// *************************************************************************** *
// *                                                                           *
// *                      Mentor Graphics Corporation                          *
// *                          All rights reserved                              *
// *                                                                           *
// *************************************************************************** *
// *                                                                           *
// * Description:         CANDB File                                           *
// * Generated at:        2025-06-23 15:14                                     *
// * System:              PP                                                   *
// * Variant:             DMH                                                  *
// * Network:             PTCANFD                                              *
// *                                                                           *
// *************************************************************************** *
// *                                                                           *
// *             THIS CONFIGURATION MIGHT CONTAIN SOME ERRORS                  *
// *              IF THE INPUT MODEL WAS NOT PROPERLY FORMED!                  *
// *                    Do Not Use this File directly!                         *
// *                                                                           *
// *************************************************************************** *
VERSION "PTCANFD"

NS_ :

BS_ :

BU_ :  BMS CCU PEU PICU TC TESTER VIU0

BO_ 267 MCUR_State_2 : 32 TC
 SG_ MCUR_CBKTq : 31|10@0+ (1.0,-500.0) [-500.0|500.0] "Nm" VIU0
 SG_ MCUR_CurrtPhaA : 151|16@0+ (0.1,-3276.8) [-3276.8|3276.7] "A" VIU0
 SG_ MCUR_CurrtPhaB : 167|16@0+ (0.1,-3276.8) [-3276.8|3276.7] "A" VIU0
 SG_ MCUR_CurrtPhaC : 183|16@0+ (0.1,-3276.8) [-3276.8|3276.7] "A" VIU0
 SG_ MCUR_DATSTq : 199|10@0+ (1.0,-500.0) [-500.0|500.0] "Nm" TESTER
 SG_ MCUR_DCCurrt : 215|16@0+ (0.1,-1000.0) [-1000.0|5553.5] "A" BMS,VIU0
 SG_ MCUR_DCVolt : 231|16@0+ (0.1,0.0) [0.0|6553.5] "V" BMS,VIU0
 SG_ MCUR_FaultLamp : 247|1@0+ (1,0) [0|1] "" TESTER
 SG_ MCUR_IGBTNTCTempA : 79|8@0+ (1.0,-48.0) [-48.0|207.0] "℃" PICU,TESTER
 SG_ MCUR_IGBTNTCTempB : 135|8@0+ (1.0,-48.0) [-48.0|207.0] "℃" PICU,TESTER
 SG_ MCUR_IGBTNTCTemPC : 143|8@0+ (1.0,-48.0) [-48.0|207.0] "℃" PICU,TESTER
 SG_ MCUR_KL30_Volt : 246|9@0+ (0.1,0.0) [0.0|51.1] "V" TESTER
 SG_ MCUR_MIL_Request : 248|1@0+ (1,0) [0|1] "" PICU,TESTER
 SG_ MCUR_OBDFaultExistSts : 37|1@0+ (1,0) [0|1] "" PICU,VIU0
 SG_ MCUR_RMotActvDampLvlSt : 52|2@0+ (1,0) [0|3] "" VIU0
 SG_ MCUR_RMotTqContnsMax : 47|11@0+ (1.0,-1024.0) [-1000.0|1000.0] "Nm" VIU0
 SG_ MCUR_RMotTqContnsMin : 50|11@0+ (1.0,-1024.0) [-1000.0|1000.0] "Nm" VIU0
 SG_ MCUR_RMotTqLongMax : 111|11@0+ (1.0,-1024.0) [-1000.0|1000.0] "Nm" VIU0
 SG_ MCUR_RMotTqLongMin : 114|11@0+ (1.0,-1024.0) [-1000.0|1000.0] "Nm" VIU0
 SG_ MCUR_RMotTqShoMax : 87|11@0+ (1.0,-1024.0) [-1000.0|1000.0] "Nm" VIU0
 SG_ MCUR_RMotTqShoMin : 90|11@0+ (1.0,-1024.0) [-1000.0|1000.0] "Nm" VIU0
 SG_ MCUR_State_2_Checksum : 7|16@0+ (1.0,0.0) [0.0|65535.0] "" VIU0
 SG_ MCUR_State_2_Counter : 23|8@0+ (1.0,0.0) [0.0|255.0] "" VIU0

BO_ 854 MCUR_State_3 : 32 TC
 SG_ MCUR_CBKEnaSt : 127|1@0+ (1,0) [0|1] "" VIU0
 SG_ MCUR_DATSEnableSt : 113|2@0+ (1,0) [0|3] "" TESTER
 SG_ MCUR_DCHV_OverU_OBDFlt : 193|2@0+ (1,0) [0|3] "" TESTER
 SG_ MCUR_EOP_Actual_Speed : 31|8@0+ (1.0,0.0) [0.0|255.0] "" TESTER
 SG_ MCUR_EOP_AIRmix_Fault : 83|1@0+ (1,0) [0|1] "" TESTER
 SG_ MCUR_EOP_Current : 55|8@0+ (0.2,0.0) [0.0|51.0] "" TESTER
 SG_ MCUR_EOP_MOS_Temp : 63|8@0+ (1.0,-40.0) [-40.0|215.0] "℃" TESTER
 SG_ MCUR_EOP_Over_Current_Fault : 87|1@0+ (1,0) [0|1] "" TESTER
 SG_ MCUR_EOP_Over_Temp_Fault : 85|1@0+ (1,0) [0|1] "" TESTER
 SG_ MCUR_EOP_Over_Voltage_Fault : 86|1@0+ (1,0) [0|1] "" TESTER
 SG_ MCUR_EOP_Self_Check_Fault : 103|1@0+ (1,0) [0|1] "" TESTER
 SG_ MCUR_EOP_State : 82|3@0+ (1,0) [0|7] "" TESTER
 SG_ MCUR_EOP_Stuck_Fault : 84|1@0+ (1,0) [0|1] "" TESTER
 SG_ MCUR_EOP_Target_Speed : 39|8@0+ (1.0,0.0) [0.0|255.0] "" TESTER
 SG_ MCUR_EOP_Under_Voltage_Fault : 95|1@0+ (1,0) [0|1] "" TESTER
 SG_ MCUR_EOP_Voltage : 47|8@0+ (0.2,0.0) [0.0|51.0] "" TESTER
 SG_ MCUR_HVAuxPwrSt : 116|1@0+ (1,0) [0|1] "" TESTER
 SG_ MCUR_HVCalSt : 115|2@0+ (1,0) [0|3] "" TESTER
 SG_ MCUR_HWWakeupSt : 117|1@0+ (1,0) [0|1] "" TESTER
 SG_ MCUR_IGBTOverTWarn_OBDFlt : 197|2@0+ (1,0) [0|3] "" TESTER
 SG_ MCUR_KL30_OverU_OBDFlt : 195|2@0+ (1,0) [0|3] "" TESTER
 SG_ MCUR_MotOverTWarn_OBDFlt : 199|2@0+ (1,0) [0|3] "" TESTER
 SG_ MCUR_PCBTemp : 111|8@0+ (1.0,-48.0) [-48.0|207.0] "℃" VIU0
 SG_ MCUR_RMotHeatActPwr : 94|7@0+ (0.1,0.0) [0.0|10.0] "KW" TESTER
 SG_ MCUR_RMotHeatMaxPwr : 102|7@0+ (0.1,0.0) [0.0|10.0] "KW" TESTER
 SG_ MCUR_RMotHeatSt : 119|2@0+ (1,0) [0|3] "" TESTER

BO_ 1459 MCUR_Version : 32 TC
 SG_ MCUR_HwVersion : 23|8@0+ (1.0,0.0) [0.0|255.0] "" TESTER
 SG_ MCUR_SupplierCode : 7|16@0+ (1.0,0.0) [0.0|65535.0] "" TESTER
 SG_ MCUR_SwMajorVersion : 31|8@0+ (1.0,0.0) [0.0|255.0] "" TESTER
 SG_ MCUR_SwMinorVersion : 39|8@0+ (1.0,0.0) [0.0|255.0] "" TESTER
 SG_ MCUR_SwPatchVersion : 47|8@0+ (1.0,0.0) [0.0|255.0] "" TESTER
 SG_ MCUR_SwVersionDay : 71|8@0+ (1.0,0.0) [0.0|31.0] "" TESTER
 SG_ MCUR_SwVersionMonth : 63|8@0+ (1.0,0.0) [0.0|12.0] "" TESTER
 SG_ MCUR_SwVersionYear : 55|8@0+ (1.0,0.0) [0.0|255.0] "" TESTER

BO_ 1042 NM_Autosar_BMS : 8 BMS
 SG_ NM_Autosar_BMS : 7|64@0+ (1,0) [0|0] "" VIU0

BO_ 1045 NM_Autosar_CDU : 8 CCU
 SG_ NM_Autosar_CDU : 7|64@0+ (1,0) [0|0] "" VIU0

BO_ 1048 NM_Autosar_GCU : 8 PEU
 SG_ NM_Autosar_GCU : 7|64@0+ (1,0) [0|0] "" VIU0

BO_ 1044 NM_Autosar_MCUR : 8 TC
 SG_ NM_Autosar_MCUR : 7|64@0+ (1,0) [0|0] "" VIU0

BO_ 1073 NM_Autosar_TDU : 8 PICU
 SG_ NM_Autosar_TDU : 7|64@0+ (1,0) [0|0] "" VIU0

BO_ 1041 NM_Autosar_VDC : 8 VIU0
 SG_ NM_Autosar_VDC : 7|64@0+ (1,0) [0|0] "" BMS, CCU, PEU, PICU, TC, TESTER

BO_ 2018 OBD_PhyReq_BMS : 8 VIU0
 SG_ OBD_PhyReq_BMS : 7|64@0+ (1,0) [0|0] "" BMS

BO_ 2020 OBD_PhyReq_GCU : 8 VIU0
 SG_ OBD_PhyReq_GCU : 7|64@0+ (1,0) [0|0] "" PEU

BO_ 2019 OBD_PhyReq_MCUR : 8 VIU0
 SG_ OBD_PhyReq_MCUR : 7|64@0+ (1,0) [0|0] "" TC

BO_ 2026 OBD_Resp_BMS : 8 BMS
 SG_ OBD_Resp_BMS : 7|64@0+ (1,0) [0|0] "" VIU0

BO_ 2028 OBD_Resp_GCU : 8 PEU
 SG_ OBD_Resp_GCU : 7|64@0+ (1,0) [0|0] "" VIU0

BO_ 2027 OBD_Resp_MCUR : 8 TC
 SG_ OBD_Resp_MCUR : 7|64@0+ (1,0) [0|0] "" VIU0

BO_ 896 TBOX_RemoteSet : 32 VIU0
 SG_ TBOX_ACDefrostSet : 35|2@0+ (1,0) [0|3] "" PICU
 SG_ TBOX_ACONOFFSet : 25|2@0+ (1,0) [0|3] "" PICU
 SG_ Tbox_ACParkAutoVentSetSts : 45|2@0+ (1,0) [0|3] "" PICU
 SG_ TBOX_ACTempSet : 31|6@0+ (0.5,15.0) [15.0|32.5] "" PICU
 SG_ TBOX_ACVentSet : 33|2@0+ (1,0) [0|3] "" PICU
 SG_ TBOX_MaxACSet : 37|2@0+ (1,0) [0|3] "" PICU
 SG_ TBOX_MaxHeatSet : 39|2@0+ (1,0) [0|3] "" PICU
 SG_ VDC_ScheduleChrgEndHour : 76|5@0+ (1.0,0.0) [0.0|23.0] "h" BMS
 SG_ VDC_ScheduleChrgEndMin : 87|6@0+ (1.0,0.0) [0.0|59.0] "min" BMS
 SG_ VDC_ScheduleChrgStarMin : 66|6@0+ (1.0,0.0) [0.0|59.0] "min" BMS
 SG_ VDC_ScheduleChrgStartHour : 71|5@0+ (1.0,0.0) [0.0|23.0] "h" BMS

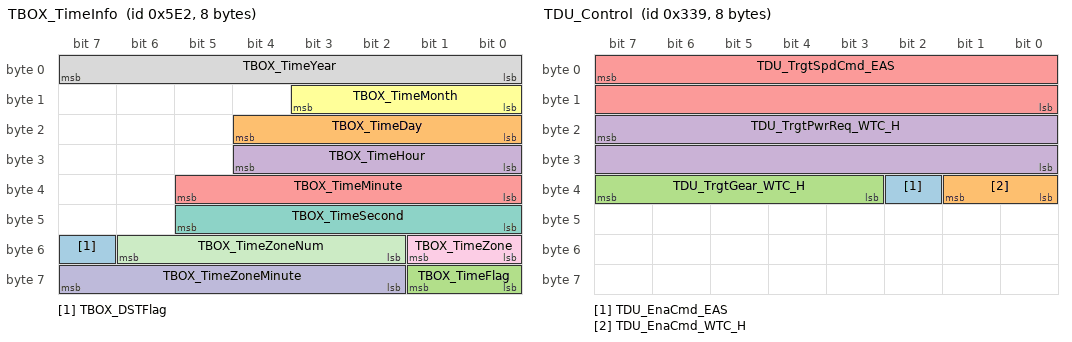
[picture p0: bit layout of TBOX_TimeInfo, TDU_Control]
BO_ 1506 TBOX_TimeInfo : 8 VIU0
 SG_ TBOX_DSTFlag : 55|1@0+ (1,0) [0|1] "" BMS,CCU,PEU,PICU,TC
 SG_ TBOX_TimeDay : 20|5@0+ (1.0,0.0) [1.0|31.0] "Day" BMS,CCU,PEU,PICU,TC
 SG_ TBOX_TimeFlag : 57|2@0+ (1,0) [0|3] "" BMS,CCU,PEU,PICU,TC
 SG_ TBOX_TimeHour : 28|5@0+ (1.0,0.0) [0.0|23.0] "h" BMS,CCU,PEU,PICU,TC
 SG_ TBOX_TimeMinute : 37|6@0+ (1.0,0.0) [0.0|59.0] "min" BMS,CCU,PEU,PICU,TC
 SG_ TBOX_TimeMonth : 11|4@0+ (1.0,0.0) [1.0|12.0] "Month" BMS,CCU,PEU,PICU,TC
 SG_ TBOX_TimeSecond : 45|6@0+ (1.0,0.0) [0.0|59.0] "s" BMS,CCU,PEU,PICU,TC
 SG_ TBOX_TimeYear : 7|8@0+ (1.0,2000.0) [2000.0|2255.0] "Year" BMS,CCU,PEU,PICU,TC
 SG_ TBOX_TimeZone : 49|2@0+ (1,0) [0|3] "" BMS,CCU,PEU,PICU,TC
 SG_ TBOX_TimeZoneMinute : 63|6@0+ (1.0,0.0) [0.0|63.0] "" BMS,CCU,PEU,PICU,TC
 SG_ TBOX_TimeZoneNum : 54|5@0+ (1,0) [0|31] "" BMS,CCU,PEU,PICU,TC

BO_ 820 TDU_ACCtrl : 32 PICU
 SG_ TDU_ACMainSwtSts : 25|2@0+ (1,0) [0|3] "" VIU0
 SG_ TDU_ACMaxSts : 109|2@0+ (1,0) [0|3] "" VIU0
 SG_ TDU_ACSts : 27|2@0+ (1,0) [0|3] "" VIU0
 SG_ TDU_ACSyncSts : 33|2@0+ (1,0) [0|3] "" VIU0
 SG_ TDU_ACWorkModeSts : 114|3@0+ (1,0) [0|7] "" VIU0
 SG_ TDU_AutoDefogRunSts : 213|2@0+ (1,0) [0|3] "" VIU0
 SG_ TDU_AutoDefogSts : 55|2@0+ (1,0) [0|3] "" VIU0
 SG_ TDU_CircModSts : 31|2@0+ (1,0) [0|3] "" VIU0
 SG_ TDU_DriverTempSts : 45|6@0+ (0.5,15.0) [15.0|32.5] "" VIU0
 SG_ TDU_FBlowModeAutoSts : 210|1@0+ (1,0) [0|1] "" VIU0
 SG_ TDU_FHvacBlowLv : 59|4@0+ (1,0) [0|15] "" VIU0
 SG_ TDU_FHvacBlowLvAutoSts : 208|1@0+ (1,0) [0|1] "" VIU0
 SG_ TDU_FogRiskLvl : 191|3@0+ (1,0) [0|7] "" VIU0
 SG_ TDU_FrontAutoSts : 29|2@0+ (1,0) [0|3] "" VIU0
 SG_ TDU_FrontBlowModeSts : 63|4@0+ (1,0) [0|15] "" VIU0
 SG_ TDU_FrontDefrostSts : 47|2@0+ (1,0) [0|3] "" VIU0
 SG_ TDU_HeatMaxSts : 111|2@0+ (1,0) [0|3] "" VIU0
 SG_ TDU_InsdTemp : 87|12@0+ (0.1,-48.0) [-48.0|80.0] "℃" VIU0
 SG_ TDU_OutdTemp : 91|12@0+ (0.1,-48.0) [-48.0|80.0] "℃" BMS,TC,VIU0
 SG_ TDU_ParkAutoVentSts : 116|2@0+ (1,0) [0|3] "" VIU0
 SG_ TDU_PassengerTemptSts : 53|6@0+ (0.5,15.0) [15.0|32.5] "" VIU0
 SG_ TDU_RACMainSwtSts : 159|2@0+ (1,0) [0|3] "" VIU0
 SG_ TDU_TempExclusiveSts : 35|2@0+ (1,0) [0|3] "" VIU0
 SG_ TDU_UnlockVentSt : 227|2@0+ (1,0) [0|3] "" VIU0

BO_ 827 TDU_ACCtrl1 : 32 PICU
 SG_ TDU_ACECOModSts : 107|2@0+ (1,0) [0|3] "" VIU0
 SG_ TDU_AGS1_Position_Cmd : 31|8@0+ (1.0,0.0) [0.0|255.0] "" VIU0
 SG_ TDU_AutoDrySts : 105|2@0+ (1,0) [0|3] "" VIU0
 SG_ TDU_RemDefrostSts : 147|2@0+ (1,0) [0|3] "" VIU0
 SG_ TDU_RemFaultSts : 145|2@0+ (1,0) [0|3] "" VIU0
 SG_ TDU_RemSts : 149|2@0+ (1,0) [0|3] "" VIU0
 SG_ TDU_RemTempSetSts : 159|8@0+ (0.5,0.0) [0.0|127.5] "" VIU0
 SG_ TDU_VentSts : 109|2@0+ (1,0) [0|3] "" VIU0

BO_ 825 TDU_Control : 8 PICU
 SG_ TDU_EnaCmd_EAS : 34|1@0+ (1,0) [0|1] "" TESTER
 SG_ TDU_EnaCmd_WTC_H : 33|2@0+ (1,0) [0|3] "" TESTER
 SG_ TDU_TrgtGear_WTC_H : 39|5@0+ (1,0) [0|31] "" TESTER
 SG_ TDU_TrgtPwrReq_WTC_H : 23|16@0+ (1.0,0.0) [0.0|10000.0] "W" TESTER
 SG_ TDU_TrgtSpdCmd_EAS : 7|16@0+ (0.25,0.0) [0.0|16383.75] "rpm" TESTER

BO_ 823 TDU_EngThermMngt : 32 PICU
 SG_ TDU_CVM_B_ActPerc : 63|8@0+ (0.4,0.0) [0.0|100.0] "%" TESTER
 SG_ TDU_CVM_B_TrgtPerc : 47|8@0+ (0.4,0.0) [0.0|100.0] "%" TESTER
 SG_ TDU_CVM_H_ActPerc : 71|8@0+ (0.4,0.0) [0.0|100.0] "%" TESTER
 SG_ TDU_CVM_H_TrgtPerc : 55|8@0+ (0.4,0.0) [0.0|100.0] "%" TESTER
 SG_ TDU_EngingstartReq : 15|1@0+ (1,0) [0|1] "" VIU0
 SG_ TDU_EngPmpSpdHeatReq : 7|7@0+ (1.0,0.0) [0.0|100.0] "%" VIU0
 SG_ TDU_EngPmpSpdHeatReqVld : 0|1@0+ (1,0) [0|1] "" VIU0
 SG_ TDU_EXV_B_LPTSnsrP : 98|9@0+ (0.01,0.0) [0.0|5.0] "MPa" TESTER
 SG_ TDU_EXV_B_LPTSnsrT : 115|12@0+ (0.1,-50.0) [-50.0|150.0] "℃" TESTER
 SG_ TDU_EXV_H_LPTSnsrP : 87|9@0+ (0.01,0.0) [0.0|5.0] "MPa" TESTER
 SG_ TDU_EXV_H_LPTSnsrT : 94|12@0+ (0.1,-50.0) [-50.0|150.0] "℃" TESTER
 SG_ TDU_FWV_CCWFlg : 38|1@0+ (1.0,0.0) [0.0|1.0] "" TESTER
 SG_ TDU_FWV_FltSt : 11|3@0+ (1.0,0.0) [0.0|7.0] "" TESTER
 SG_ TDU_FWV_InitSta : 39|1@0+ (1.0,0.0) [0.0|1.0] "" TESTER
 SG_ TDU_FWV_location : 8|9@0+ (0.25,0.0) [0.0|100.0] "%" TESTER
 SG_ TDU_FWV_location_FB : 31|8@0+ (0.4,0.0) [0.0|100.0] "%" TESTER
 SG_ TDU_FWV_MotorSta : 37|1@0+ (1.0,0.0) [0.0|1.0] "" TESTER
 SG_ TDU_FWV_MoveEnable : 14|1@0+ (1.0,0.0) [0.0|1.0] "" TESTER
 SG_ TDU_FWV_ReqMotorEmgyStop : 13|1@0+ (1.0,0.0) [0.0|1.0] "" TESTER
 SG_ TDU_FWV_ReqMotorOptRecovery : 12|1@0+ (1.0,0.0) [0.0|1.0] "" TESTER
 SG_ TDU_IcoInlT : 79|8@0+ (1.0,-48.0) [-48.0|207.0] "℃" TESTER,VIU0

BO_ 1420 TDU_Fault : 32 PICU
 SG_ TDU_FaultNum1 : 23|12@0+ (1.0,0.0) [0.0|4095.0] "" VIU0
 SG_ TDU_FaultNum10 : 123|12@0+ (1.0,0.0) [0.0|4095.0] "" VIU0
 SG_ TDU_FaultNum11 : 143|12@0+ (1.0,0.0) [0.0|4095.0] "" VIU0
 SG_ TDU_FaultNum12 : 147|12@0+ (1.0,0.0) [0.0|4095.0] "" VIU0
 SG_ TDU_FaultNum13 : 167|12@0+ (1.0,0.0) [0.0|4095.0] "" VIU0
 SG_ TDU_FaultNum14 : 171|12@0+ (1.0,0.0) [0.0|4095.0] "" VIU0
 SG_ TDU_FaultNum15 : 191|12@0+ (1.0,0.0) [0.0|4095.0] "" VIU0
 SG_ TDU_FaultNum16 : 195|12@0+ (1.0,0.0) [0.0|4095.0] "" VIU0
 SG_ TDU_FaultNum17 : 215|12@0+ (1.0,0.0) [0.0|4095.0] "" VIU0
 SG_ TDU_FaultNum18 : 219|12@0+ (1.0,0.0) [0.0|4095.0] "" VIU0
 SG_ TDU_FaultNum19 : 239|12@0+ (1.0,0.0) [0.0|4095.0] "" VIU0
 SG_ TDU_FaultNum2 : 27|12@0+ (1.0,0.0) [0.0|4095.0] "" VIU0
 SG_ TDU_FaultNum20 : 243|12@0+ (1.0,0.0) [0.0|4095.0] "" VIU0
 SG_ TDU_FaultNum3 : 47|12@0+ (1.0,0.0) [0.0|4095.0] "" VIU0
 SG_ TDU_FaultNum4 : 51|12@0+ (1.0,0.0) [0.0|4095.0] "" VIU0
 SG_ TDU_FaultNum5 : 71|12@0+ (1.0,0.0) [0.0|4095.0] "" VIU0
 SG_ TDU_FaultNum6 : 75|12@0+ (1.0,0.0) [0.0|4095.0] "" VIU0
 SG_ TDU_FaultNum7 : 95|12@0+ (1.0,0.0) [0.0|4095.0] "" VIU0
 SG_ TDU_FaultNum8 : 99|12@0+ (1.0,0.0) [0.0|4095.0] "" VIU0
 SG_ TDU_FaultNum9 : 119|12@0+ (1.0,0.0) [0.0|4095.0] "" VIU0
 SG_ TDU_FrameIndex : 12|5@0+ (1.0,0.0) [0.0|31.0] "" VIU0
 SG_ TDU_SupplierNum : 15|3@0+ (1.0,0.0) [0.0|7.0] "" VIU0
 SG_ TDU_TotalFaultNum : 7|8@0+ (1.0,0.0) [0.0|255.0] "" VIU0

BO_ 821 TDU_HybMotCtrl : 32 PICU
 SG_ TDU_CircHybThrMotActPerc : 55|8@0+ (1.0,0.0) [0.0|100.0] "%" VIU0
 SG_ TDU_CircHybThrMotTrgtPerc : 23|8@0+ (1.0,0.0) [0.0|100.0] "%" TESTER
 SG_ TDU_LeBlowFaceAirOutlT : 135|12@0+ (0.1,-48.0) [-48.0|207.0] "℃" TESTER
 SG_ TDU_LeBlowFootAirOutlT : 159|12@0+ (0.1,-48.0) [-48.0|207.0] "℃" TESTER
 SG_ TDU_LeModHybThrMotActGear_F : 59|4@0+ (1,0) [0|15] "" TESTER
 SG_ TDU_LeModHybThrMotTrgtGear_F : 27|4@0+ (1,0) [0|15] "" TESTER
 SG_ TDU_LeTHybThrMotActPerc_F : 39|8@0+ (1.0,0.0) [0.0|100.0] "%" TESTER
 SG_ TDU_LeTHybThrMotTrgtPerc_F : 7|8@0+ (1.0,0.0) [0.0|100.0] "%" TESTER
 SG_ TDU_RiBlowFaceAirOutlT : 139|12@0+ (0.1,-48.0) [-48.0|207.0] "℃" TESTER
 SG_ TDU_RiBlowFootAirOutlT : 163|12@0+ (0.1,-48.0) [-48.0|207.0] "℃" TESTER
 SG_ TDU_RiTHybThrMotActPerc_F : 47|8@0+ (1.0,0.0) [0.0|100.0] "%" TESTER
 SG_ TDU_RiTHybThrMotTrgtPerc_F : 15|8@0+ (1.0,0.0) [0.0|100.0] "%" TESTER

BO_ 908 TDU_PTCCtrlFD : 32 PICU
 SG_ ACComprMngmntInfo : 199|6@0+ (1,0) [0|63] "" TESTER
 SG_ AmbtTemSnsrFlrSts : 34|3@0+ (1.0,0.0) [0.0|7.0] "" TESTER
 SG_ AmbtTemSnsrFlrStsInvsn : 59|3@0+ (1.0,0.0) [0.0|7.0] "" TESTER
 SG_ EvapACMangmntInfo : 95|8@0+ (1.0,0.0) [0.0|255.0] "" TESTER
 SG_ HeatPumpErMngmntInfo : 207|5@0+ (1,0) [0|31] "" TESTER
 SG_ HeatPumpMd : 187|4@0+ (1,0) [0|15] "" TESTER
 SG_ PTCMngmntInfo : 103|8@0+ (1.0,0.0) [0.0|255.0] "" TESTER
 SG_ TDU_AGS1_CurrentPos : 79|8@0+ (1.0,0.0) [0.0|255.0] "%" VIU0
 SG_ TDU_AGS2_CurrentPos : 71|8@0+ (1.0,0.0) [0.0|255.0] "%" VIU0
 SG_ TDU_AGS_TarPos : 87|8@0+ (1.0,0.0) [0.0|255.0] "%" TESTER
 SG_ TDU_BypsVlv_Sts : 63|2@0+ (1.0,0.0) [0.0|3.0] "" TESTER
 SG_ TDU_ESSPTC_HVIL_St : 209|2@0+ (1,0) [0|3] "" VIU0
 SG_ TDU_ESSTC_HVIL_St : 202|2@0+ (1,0) [0|3] "" TESTER
 SG_ TDU_ExInnerInletTem : 163|12@0+ (0.1,-48.0) [-48.0|207.0] "℃" TESTER
 SG_ TDU_ExInnerOutletTem : 183|12@0+ (0.1,-48.0) [-48.0|207.0] "℃" TESTER
 SG_ TDU_HtngVlv_Sts : 61|2@0+ (1.0,0.0) [0.0|3.0] "" TESTER
 SG_ TDU_LePTCAirOutlT : 115|12@0+ (0.1,-48.0) [-48.0|207.0] "℃" TESTER
 SG_ TDU_LePTCAirOutlTrgtTemp : 139|12@0+ (0.1,-48.0) [-48.0|207.0] "℃" TESTER
 SG_ TDU_OtsdAirTemRaw : 111|12@0+ (0.1,-48.0) [-48.0|80.0] "℃" TESTER
 SG_ TDU_RiPTCAirOutlT : 135|12@0+ (0.1,-48.0) [-48.0|207.0] "℃" TESTER
 SG_ TDU_RiPTCAirOutlTrgtTemp : 159|12@0+ (0.1,-48.0) [-48.0|207.0] "℃" TESTER
 SG_ TDU_SOTXV_Sts : 36|2@0+ (1.0,0.0) [0.0|3.0] "" TESTER
 SG_ TDU_TempExclusiveRearFlg : 193|2@0+ (1,0) [0|3] "" TESTER
 SG_ TDUEnbPTC : 39|1@0+ (1,0) [0|1] "" VIU0
 SG_ TDUReqMd : 38|2@0+ (1,0) [0|3] "" VIU0
 SG_ TDUReqPTCPwr : 47|16@0+ (1.0,0.0) [0.0|65535.0] "" VIU0

BO_ 829 TDU_Pump : 32 PICU
 SG_ TDU_BatPumpTrgtSpd : 111|8@0+ (0.4,0.0) [0.0|100.0] "%" TESTER
 SG_ TDU_MotPumpTrgtSpd : 103|8@0+ (0.4,0.0) [0.0|100.0] "%" TESTER
 SG_ TDU_PumpBActSpd : 39|8@0+ (0.4,0.0) [0.0|100.0] "%" TESTER
 SG_ TDU_PumpBCurrt : 63|8@0+ (0.1,0.0) [0.0|25.5] "A" TESTER
 SG_ TDU_PumpBTemp : 55|8@0+ (1.0,-48.0) [-48.0|206.0] "℃" TESTER
 SG_ TDU_PumpBVolt : 47|8@0+ (0.1,0.0) [0.0|25.400000000000002] "V" TESTER
 SG_ TDU_PumpPActSpd : 71|8@0+ (0.4,0.0) [0.0|100.0] "%" TESTER
 SG_ TDU_PumpPCurrt : 95|8@0+ (0.1,0.0) [0.0|25.5] "A" TESTER
 SG_ TDU_PumpPTemp : 87|8@0+ (1.0,-48.0) [-48.0|206.0] "℃" TESTER
 SG_ TDU_PumpPVolt : 79|8@0+ (0.1,0.0) [0.0|25.400000000000002] "V" TESTER

BO_ 1329 TDU_SubSnsrState_1 : 32 PICU
 SG_ TDU_HPTSnsrP : 7|9@0+ (0.01,0.0) [0.0|5.0] "MPa" TESTER
 SG_ TDU_HPTSnsrT : 11|12@0+ (0.1,-50.0) [-50.0|150.0] "℃" TESTER
 SG_ TDU_LPTSnsrP : 31|9@0+ (0.01,0.0) [0.0|5.0] "MPa" TESTER
 SG_ TDU_LPTSnsrT : 35|12@0+ (0.1,-50.0) [-50.0|150.0] "℃" TESTER

BO_ 828 TDU_SubSnsrState_2 : 32 PICU
 SG_ TDU_AirBlowerDownFbU : 87|11@0+ (0.01,0.0) [0.0|16.0] "V" TESTER
 SG_ TDU_AirBlowerRelaySpdPWM : 55|8@0+ (0.4,0.0) [0.0|100.0] "" TESTER
 SG_ TDU_AirBlowerRelaySpdU : 71|11@0+ (0.01,0.0) [0.0|16.0] "V" TESTER
 SG_ TDU_AirBlowerUpFbU : 90|11@0+ (0.01,0.0) [0.0|16.0] "V" TESTER
 SG_ TDU_EvaprTemp : 35|12@0+ (0.1,-48.0) [-48.0|207.0] "℃" TESTER
 SG_ TDU_FEvaprTrgtTemp : 135|12@0+ (0.1,-48.0) [-48.0|207.0] "℃" TESTER
 SG_ TDU_LeSunshineSnsrT : 111|11@0+ (1.0,0.0) [0.0|1200.0] "W" TESTER
 SG_ TDU_RiSunshineSnsrT : 114|11@0+ (1.0,0.0) [0.0|1200.0] "" TESTER
 SG_ TDU_UBRVolt : 31|12@0+ (0.01,0.0) [0.0|16.0] "V" TESTER
 SG_ TDU_WakeupVolt : 23|8@0+ (0.1,0.0) [0.0|16.0] "V" TESTER

BO_ 1328 TDU_TempFeedBack : 32 PICU
 SG_ TDU_BattInlT : 23|8@0+ (1.0,-48.0) [-48.0|207.0] "℃" BMS,VIU0
 SG_ TDU_BattOutlT : 31|8@0+ (1.0,-48.0) [-48.0|207.0] "℃" BMS,VIU0
 SG_ TDU_HEXInWtrT : 55|12@0+ (1.0,-48.0) [-48.0|207.0] "°C" TESTER
 SG_ TDU_MotInletWaterT : 39|8@0+ (1.0,-48.0) [-48.0|207.0] "℃" TC,VIU0
 SG_ TDU_MotLoopCooltFlow : 47|8@0+ (0.1,0.0) [0.0|25.5] "L/min" TC,VIU0

BO_ 817 TDU_ThermalState : 32 PICU
 SG_ TDU_BattCoolgLoopSts : 43|2@0+ (1,0) [0|3] "" BMS
 SG_ TDU_BattModSt : 59|4@0+ (1,0) [0|15] "" BMS,VIU0
 SG_ TDU_BattThermRunawaySts : 82|1@0+ (1,0) [0|1] "" TESTER
 SG_ TDU_BattWrmLoopSts : 35|2@0+ (1,0) [0|3] "" BMS
 SG_ TDU_CabCoolLoopSts : 39|2@0+ (1,0) [0|3] "" TESTER
 SG_ TDU_CabHeatLoopSts : 37|2@0+ (1,0) [0|3] "" TESTER
 SG_ TDU_CabModSt : 55|4@0+ (1,0) [0|15] "" BMS,VIU0
 SG_ TDU_FaultLevel : 87|3@0+ (1,0) [0|7] "" VIU0
 SG_ TDU_HeatMngtFctLim : 33|1@0+ (1,0) [0|1] "" TESTER
 SG_ TDU_HeatMngtSysFlt : 24|1@0+ (1,0) [0|1] "" TESTER
 SG_ TDU_HeatMngtSysFltNr : 119|16@0+ (1.0,0.0) [0.0|65535.0] "" TESTER
 SG_ TDU_HEnerConsume : 103|16@0+ (1.0,0.0) [0.0|30000.0] "W" VIU0
 SG_ TDU_HVCnctHldReq : 83|1@0+ (1,0) [0|1] "" VIU0
 SG_ TDU_HVPwrMaxReq : 135|16@0+ (1.0,0.0) [0.0|60000.0] "" VIU0
 SG_ TDU_HVPwrMinReq : 151|16@0+ (1.0,0.0) [0.0|60000.0] "" VIU0
 SG_ TDU_LEnerConsume : 81|10@0+ (1.0,0.0) [0.0|1000.0] "W" TESTER
 SG_ TDU_LVPwrMaxReq : 167|16@0+ (1.0,0.0) [0.0|60000.0] "" TESTER
 SG_ TDU_LVPwrMinReq : 183|16@0+ (1.0,0.0) [0.0|60000.0] "" TESTER
 SG_ TDU_MotCoolgLoopSts : 41|2@0+ (1,0) [0|3] "" TC,VIU0
 SG_ TDU_MotHeatPwrAvl : 247|8@0+ (0.1,0.0) [0.0|25.400000000000002] "kw" VIU0
 SG_ TDU_OperMod : 51|4@0+ (1,0) [0|15] "" VIU0
 SG_ TDU_PTCPwrAct : 239|8@0+ (0.1,0.0) [0.0|25.400000000000002] "kw" VIU0
 SG_ TDU_PTCPwrAvl : 231|8@0+ (0.1,0.0) [0.0|25.400000000000002] "kw" VIU0
 SG_ TDU_PwrModSt : 63|4@0+ (1,0) [0|15] "" TESTER
 SG_ TDU_RefModSt : 47|4@0+ (1,0) [0|15] "" VIU0
 SG_ TDU_SafteyModSts : 32|1@0+ (1,0) [0|1] "" VIU0
 SG_ TDU_SilentCoolgErrWakeup : 29|1@0+ (1,0) [0|1] "" TESTER
 SG_ TDU_SilentCoolgSts : 28|2@0+ (1,0) [0|3] "" TESTER
 SG_ TDU_WakeupHldReq : 84|1@0+ (1,0) [0|1] "" TESTER

BO_ 1333 TDU_ValveCtrl : 32 PICU
 SG_ TDU_CoolgFanActSpd : 7|8@0+ (0.4,0.0) [0.0|100.0] "%" TESTER
 SG_ TDU_CoolgFanOpenCmd : 15|8@0+ (0.4,0.0) [0.0|100.0] "" TESTER
 SG_ TDU_EXVB_ActOpenVal : 103|16@0+ (1.0,0.0) [0.0|576.0] "" TESTER
 SG_ TDU_EXVB_InitSts : 132|2@0+ (1,0) [0|3] "" TESTER
 SG_ TDU_EXVB_OpenCmd : 71|16@0+ (1.0,0.0) [0.0|576.0] "" TESTER
 SG_ TDU_EXVB_Sts : 133|1@0+ (1,0) [0|1] "" TESTER
 SG_ TDU_EXVH_ActOpenVal : 119|16@0+ (1.0,0.0) [0.0|576.0] "" TESTER
 SG_ TDU_EXVH_InitSts : 129|2@0+ (1,0) [0|3] "" TESTER
 SG_ TDU_EXVH_OpenCmd : 87|16@0+ (1.0,0.0) [0.0|576.0] "" TESTER
 SG_ TDU_EXVH_Sts : 130|1@0+ (1,0) [0|1] "" TESTER

BO_ 1461 TDU_Version : 32 PICU
 SG_ EAS_HwVersion : 223|8@0+ (1.0,0.0) [0.0|255.0] "" TESTER
 SG_ EAS_SwMajorVersion : 231|8@0+ (1.0,0.0) [0.0|255.0] "" TESTER
 SG_ EAS_SwMinorVersion : 239|8@0+ (1.0,0.0) [0.0|255.0] "" TESTER
 SG_ PTC_R_HwVersion : 247|8@0+ (1.0,0.0) [0.0|255.0] "" TESTER
 SG_ PTC_R_SwVersion : 255|8@0+ (1.0,0.0) [0.0|255.0] "" TESTER
 SG_ TDU_HwVersion : 23|8@0+ (1.0,0.0) [0.0|255.0] "" TESTER
 SG_ TDU_PartVers : 79|32@0+ (1.0,0.0) [0.0|4294967295.0] "" TESTER
 SG_ TDU_SupplierCode : 7|16@0+ (1.0,0.0) [0.0|65535.0] "" TESTER
 SG_ TDU_SwMajorVersion : 31|8@0+ (1.0,0.0) [0.0|255.0] "" TESTER
 SG_ TDU_SwMinorVersion : 39|8@0+ (1.0,0.0) [0.0|255.0] "" TESTER
 SG_ TDU_SwPatchVersion : 47|8@0+ (1.0,0.0) [0.0|255.0] "" TESTER
 SG_ TDU_SwVersionDay : 71|8@0+ (1.0,0.0) [0.0|31.0] "" TESTER
 SG_ TDU_SwVersionMonth : 63|8@0+ (1.0,0.0) [0.0|12.0] "" TESTER
 SG_ TDU_SwVersionYear : 55|8@0+ (1.0,0.0) [0.0|255.0] "" TESTER
 SG_ WTC_H_HwVersion : 199|8@0+ (1.0,0.0) [0.0|255.0] "" TESTER
 SG_ WTC_H_SwMajorVersion : 207|8@0+ (1.0,0.0) [0.0|255.0] "" TESTER
 SG_ WTC_H_SwMinorVersion : 215|8@0+ (1.0,0.0) [0.0|255.0] "" TESTER

BO_ 818 TDU_WTC_EAS : 32 PICU
 SG_ TDU_EAS_CrtPwr : 207|16@0+ (0.2,0.0) [0.0|13107.0] "W" VIU0
 SG_ TDU_EAS_CrtSts : 141|2@0+ (1,0) [0|3] "" TESTER
 SG_ TDU_EAS_CtrlrCurrt : 247|16@0+ (0.02,0.0) [0.0|1310.7] "A" BMS
 SG_ TDU_EAS_CtrlrVolt : 231|16@0+ (0.02,0.0) [0.0|1310.7] "V" BMS
 SG_ TDU_EAS_HVIL_St : 143|2@0+ (1,0) [0|3] "" VIU0
 SG_ TDU_EAS_IPMTemp : 199|8@0+ (1.0,-48.0) [-48.0|207.0] "℃" TESTER
 SG_ TDU_EAS_MotCurrt : 183|16@0+ (0.02,0.0) [0.0|1310.7] "A" BMS,TESTER
 SG_ TDU_EAS_MotSpd : 167|16@0+ (0.25,0.0) [0.0|16383.75] "rpm" TESTER
 SG_ TDU_WTC_H_ActGear : 68|5@0+ (1,0) [0|31] "" TESTER
 SG_ TDU_WTC_H_CrtPwr : 39|16@0+ (1.0,0.0) [0.0|65534.0] "W" VIU0
 SG_ TDU_WTC_H_CrtSts : 71|3@0+ (1,0) [0|7] "" TESTER
 SG_ TDU_WTC_H_CrtTemp : 119|8@0+ (1.0,-48.0) [-48.0|207.0] "℃" TESTER
 SG_ TDU_WTC_H_Currt : 79|16@0+ (0.001,0.0) [0.0|65.535] "" BMS
 SG_ TDU_WTC_H_HVPwrSplySts : 95|16@0+ (0.02,0.0) [0.0|1310.7] "V" BMS
 SG_ TDU_WTC_H_InpTemp : 55|8@0+ (1.0,-48.0) [-48.0|207.0] "℃" TESTER
 SG_ TDU_WTC_H_OutpTemp : 63|8@0+ (1.0,-48.0) [-48.0|207.0] "℃" TESTER
 SG_ TDU_WTC_H_PCBTemp : 111|8@0+ (1.0,-48.0) [-48.0|207.0] "" TESTER
 SG_ TDU_WTC_H_TarOutpTemp : 127|8@0+ (1.0,-48.0) [-48.0|207.0] "℃" TESTER
 SG_ TDU_WTC_HVIL_St : 31|2@0+ (1,0) [0|3] "" VIU0

BO_ 582 VDC_BCM_DoorState : 32 VIU0
 SG_ VDC_DrvrDoorLockSt : 87|2@0+ (1,0) [0|3] "" PICU
 SG_ VDC_DrvrDoorLockStVld : 84|1@0+ (1,0) [0|1] "" PICU
 SG_ VDC_DrvrDoorSt : 31|2@0+ (1,0) [0|3] "" PICU
 SG_ VDC_DrvrDoorStValid : 29|1@0+ (1,0) [0|1] "" PICU
 SG_ VDC_HoodSts : 37|2@0+ (1,0) [0|3] "" PICU
 SG_ VDC_PassDoorLockSt : 83|2@0+ (1,0) [0|3] "" PICU
 SG_ VDC_PassDoorSt : 28|2@0+ (1,0) [0|3] "" PICU
 SG_ VDC_RLDoorLockSt : 81|2@0+ (1,0) [0|3] "" PICU
 SG_ VDC_RLDoorSt : 26|2@0+ (1,0) [0|3] "" PICU
 SG_ VDC_RRDoorLockSt : 95|2@0+ (1,0) [0|3] "" PICU
 SG_ VDC_RRDoorSt : 39|2@0+ (1,0) [0|3] "" PICU
 SG_ VDC_TailgateSt : 35|4@0+ (1,0) [0|15] "" PICU

BO_ 798 VDC_BCM_SeatState : 32 VIU0
 SG_ VDC_BCM_SeatState_Checksum : 7|16@0+ (1.0,0.0) [0.0|65535.0] "" TESTER
 SG_ VDC_BCM_SeatState_Counter : 23|8@0+ (1.0,0.0) [0.0|255.0] "" TESTER
 SG_ VDC_DriverSeatOccptSt : 47|2@0+ (1,0) [0|3] "" PICU
 SG_ VDC_PassSeatOccptSt : 45|2@0+ (1,0) [0|3] "" PICU
 SG_ VDC_RLSecRowSeatOccptSt : 43|2@0+ (1,0) [0|3] "" PICU
 SG_ VDC_RMSecRowSeatOccptSt : 41|2@0+ (1,0) [0|3] "" PICU
 SG_ VDC_RRSecRowSeatOccptSt : 55|2@0+ (1,0) [0|3] "" PICU

BO_ 819 VDC_CDC_TDUSet : 32 VIU0
 SG_ VDC_CDC_ACECOModReq : 151|2@0+ (1,0) [0|3] "" PICU
 SG_ VDC_CDC_ACFourZoneSync : 101|2@0+ (1,0) [0|3] "" PICU
 SG_ VDC_CDC_ACMaxSet : 97|2@0+ (1,0) [0|3] "" PICU
 SG_ VDC_CDC_ACParkAutoVentSet : 111|2@0+ (1,0) [0|3] "" PICU
 SG_ VDC_CDC_ACSet : 27|2@0+ (1,0) [0|3] "" PICU
 SG_ VDC_CDC_ACSystemOnOffSet : 31|2@0+ (1,0) [0|3] "" PICU
 SG_ VDC_CDC_AutoDefogSet : 105|2@0+ (1,0) [0|3] "" PICU
 SG_ VDC_CDC_AutoDrySet : 149|2@0+ (1,0) [0|3] "" PICU
 SG_ VDC_CDC_CircModSet : 87|2@0+ (1,0) [0|3] "" PICU
 SG_ VDC_CDC_DriverTempSet : 53|6@0+ (0.5,15.0) [15.0|32.5] "" PICU
 SG_ VDC_CDC_FHvacBlowLvSet : 39|4@0+ (1,0) [0|15] "" PICU
 SG_ VDC_CDC_FHvacModeSet : 47|4@0+ (1,0) [0|15] "" PICU
 SG_ VDC_CDC_FrontDefrostSet : 25|2@0+ (1,0) [0|3] "" PICU
 SG_ VDC_CDC_HeatMaxSet : 99|2@0+ (1,0) [0|3] "" PICU
 SG_ VDC_CDC_HvacAutoModeSet : 95|2@0+ (1,0) [0|3] "" PICU
 SG_ VDC_CDC_PassengerTempSet : 61|6@0+ (0.5,15.0) [15.0|32.5] "" PICU
 SG_ VDC_CDC_RACSystemOnOffSet : 29|2@0+ (1,0) [0|3] "" PICU
 SG_ VDC_CDC_SceneModPwrOnSts : 175|2@0+ (1,0) [0|3] "" PICU
 SG_ VDC_CDC_SupCoolingModSet : 117|2@0+ (1,0) [0|3] "" PICU
 SG_ VDC_CDC_TempExclusive : 103|2@0+ (1,0) [0|3] "" PICU
 SG_ VDC_CDC_VentSet : 153|2@0+ (1,0) [0|3] "" PICU

BO_ 289 VDC_EMSCtrl : 32 VIU0
 SG_ VDC_CoordiRespondSt : 26|1@0+ (1,0) [0|1] "" PICU
 SG_ VDC_DrvgCyc : 39|1@0+ (1,0) [0|1] "" TESTER
 SG_ VDC_EMSCtrl_Checksum : 7|16@0+ (1.0,0.0) [0.0|65535.0] "" PICU
 SG_ VDC_EMSCtrl_Counter : 23|8@0+ (1.0,0.0) [0.0|255.0] "" PICU
 SG_ VDC_EngCrankReq : 51|1@0+ (1,0) [0|1] "" PICU
 SG_ VDC_EngCtrlSt : 30|4@0+ (1,0) [0|15] "" PICU,TESTER
 SG_ VDC_EngMaxSpdLim : 183|13@0+ (1.0,0.0) [0.0|8000.0] "" PICU
 SG_ VDC_EngRampEna : 60|1@0+ (1,0) [0|1] "" PICU
 SG_ VDC_EngReadySt : 31|1@0+ (1,0) [0|1] "" PICU
 SG_ VDC_EngStartMod : 53|2@0+ (1,0) [0|3] "" PICU
 SG_ VDC_EngStartReq : 55|2@0+ (1,0) [0|3] "" PICU
 SG_ VDC_EngStopReq : 48|1@0+ (1,0) [0|1] "" PICU
 SG_ VDC_EngStrtFuInjInhb : 50|1@0+ (1,0) [0|1] "" PICU
 SG_ VDC_EngTqResv : 130|11@0+ (0.5,-500.0) [-500.0|500.0] "Nm" PICU
 SG_ VDC_FlyWhFastTqReq : 151|13@0+ (0.1,-350.0) [-350.0|400.0] "Nm" PICU
 SG_ VDC_FlyWhFastTqReqVld : 154|1@0+ (1,0) [0|1] "" PICU
 SG_ VDC_FlyWhSlowTqReq : 167|13@0+ (0.1,-350.0) [-350.0|400.0] "Nm" PICU
 SG_ VDC_FlyWhSlowTqReqVld : 170|1@0+ (1,0) [0|1] "" PICU
 SG_ VDC_FuelChargeStatus : 227|2@0+ (1,0) [0|3] "" TESTER
 SG_ VDC_FuelChargeSwitch : 228|1@0+ (1,0) [0|1] "" TESTER
 SG_ VDC_FuelCutOffReq : 63|1@0+ (1,0) [0|1] "" PICU
 SG_ VDC_FueldetectionStatus : 230|2@0+ (1,0) [0|3] "" TESTER
 SG_ VDC_FueldetectionSwitch : 231|1@0+ (1,0) [0|1] "" TESTER
 SG_ VDC_FuelRemaining : 47|7@0+ (1.0,0.0) [0.0|100.0] "%" PICU
 SG_ VDC_FuelRemainingVld : 40|1@0+ (1,0) [0|1] "" PICU
 SG_ VDC_FuelRemainingVol : 215|14@0+ (0.01,0.0) [0.0|100.0] "L" PICU
 SG_ VDC_GenStableTqAdpSt : 25|1@0+ (1,0) [0|1] "" PICU
 SG_ VDC_IdleChrgActvReq : 97|2@0+ (1,0) [0|3] "" PICU
 SG_ VDC_IdleChrgFlyWhlLoadTq : 127|13@0+ (0.1,-350.0) [-350.0|400.0] "" PICU
 SG_ VDC_IdleChrgFlyWhlLoadTqVld : 114|1@0+ (1,0) [0|1] "" PICU
 SG_ VDC_IdleChrgSpdReq : 111|12@0+ (1.0,0.0) [0.0|2550.0] "" PICU
 SG_ VDC_IdleChrgSpdReqVld : 115|1@0+ (1,0) [0|1] "" PICU
 SG_ VDC_IdleCtrlReq : 59|2@0+ (1,0) [0|3] "" PICU
 SG_ VDC_IdleLoadTq : 95|13@0+ (0.1,-350.0) [-350.0|400.0] "" PICU
 SG_ VDC_IdleLoadTqVld : 98|1@0+ (1,0) [0|1] "" PICU
 SG_ VDC_IgAglRlsActvSts : 62|2@0+ (1,0) [0|3] "" PICU
 SG_ VDC_IgnCyc : 24|1@0+ (1,0) [0|1] "" TESTER
 SG_ VDC_MILReq : 49|1@0+ (1,0) [0|1] "" PICU
 SG_ VDC_OBDFaultExistSts : 113|1@0+ (1,0) [0|1] "" PICU
 SG_ VDC_REVMod : 198|3@0+ (1,0) [0|7] "" TESTER
 SG_ VDC_TarIdleSpdReq : 77|13@0+ (1.0,0.0) [0.0|8000.0] "rpm" PICU
 SG_ VDC_TarIdleSpdReqVld : 80|1@0+ (1,0) [0|1] "" PICU
 SG_ VDC_WarmupCyc : 38|1@0+ (1,0) [0|1] "" TESTER

BO_ 1408 VDC_EngyCalcu : 64 VIU0
 SG_ VDC_ChrgPostCurrent : 495|10@0+ (1.0,0.0) [0.0|1000.0] "A" BMS
 SG_ VDC_ChrgPostPwr : 500|13@0+ (0.1,0.0) [0.0|819.1] "kW" BMS
 SG_ VDC_CLTCRang : 263|11@0+ (1.0,0.0) [0.0|2047.0] "km" PICU,TC
 SG_ VDC_CompositeRang_VV01 : 266|11@0+ (1.0,0.0) [0.0|2047.0] "km" PEU,PICU,TC
 SG_ VDC_EngyAfAvgLastChrg : 242|11@0+ (1.0,-50.0) [-50.0|1997.0] "kwh/100km" TESTER
 SG_ VDC_EngyAfLastChrg : 239|11@0+ (0.1,-100.0) [-100.0|100.0] "kWh" TESTER
 SG_ VDC_EngyAvgRstA : 215|11@0+ (1.0,-1024.0) [-1024.0|1023.0] "Wh/km" TESTER
 SG_ VDC_EngyAvgRstB : 218|11@0+ (1.0,-1024.0) [-1024.0|1023.0] "Wh/km" TESTER
 SG_ VDC_EngyDrvAvePerKm : 98|11@0+ (1.0,-1024.0) [-1024.0|1023.0] "Wh/km" TESTER
 SG_ VDC_EngyRegenPerKm : 73|10@0+ (1.0,0.0) [0.0|1023.0] "Wh/km" TESTER
 SG_ VDC_EngyRstA : 165|14@0+ (1.0,-100.0) [-100.0|8191.0] "kWh" TESTER
 SG_ VDC_EngyRstB : 181|14@0+ (1.0,-100.0) [-100.0|8191.0] "kWh" TESTER
 SG_ VDC_EngytotalCurCyc : 95|11@0+ (0.1,-100.0) [-100.0|100.0] "kWh" TESTER
 SG_ VDC_EngyTotalRegen : 55|16@0+ (1.0,0.0) [0.0|65535.0] "Wh" TESTER
 SG_ VDC_EstimdArrivalDst : 479|16@0+ (0.1,0.0) [0.0|6553.5] "km" BMS
 SG_ VDC_EstimdArrivalSOC : 455|10@0+ (0.1,0.0) [0.0|100.0] "%" BMS
 SG_ VDC_EstimdArrivalTi : 457|10@0+ (1.0,0.0) [0.0|1023.0] "min" BMS
 SG_ VDC_HeatEngy : 439|16@0+ (1.0,0.0) [0.0|65534.0] "wh" BMS
 SG_ VDC_RangAfLastChrg : 197|14@0+ (0.1,0.0) [0.0|1600.0] "km" TESTER
 SG_ VDC_RangChrgSet : 33|10@0+ (1.0,0.0) [0.0|1000.0] "Km" TESTER
 SG_ VDC_RangeRstSetSt : 18|3@0+ (1,0) [0|7] "" TESTER
 SG_ VDC_RangRstA : 134|15@0+ (1.0,0.0) [0.0|32767.0] "km" TESTER
 SG_ VDC_RangRstB : 150|15@0+ (1.0,0.0) [0.0|32767.0] "km" TESTER
 SG_ VDC_RatRegen : 119|8@0+ (1.0,0.0) [0.0|100.0] "%" TESTER
 SG_ VDC_RMotPwr : 71|14@0+ (0.1,-270.0) [-270.0|1000.0] "kW" TESTER
 SG_ VDC_TotalRang_VV01 : 7|20@0+ (1.0,0.0) [0.0|1048575.0] "km" BMS,CCU,PEU,PICU,TC

BO_ 848 VDC_EVR : 32 VIU0
 SG_ VDC_GCUPowergenerationstatus : 26|2@0+ (1,0) [0|3] "" BMS

BO_ 1302 VDC_Fault : 32 VIU0
 SG_ VDC_FaultNum1 : 23|12@0+ (1.0,0.0) [0.0|4095.0] "" TESTER
 SG_ VDC_FaultNum10 : 123|12@0+ (1.0,0.0) [0.0|4095.0] "" TESTER
 SG_ VDC_FaultNum11 : 143|12@0+ (1.0,0.0) [0.0|4095.0] "" TESTER
 SG_ VDC_FaultNum12 : 147|12@0+ (1.0,0.0) [0.0|4095.0] "" TESTER
 SG_ VDC_FaultNum13 : 167|12@0+ (1.0,0.0) [0.0|4095.0] "" TESTER
 SG_ VDC_FaultNum14 : 171|12@0+ (1.0,0.0) [0.0|4095.0] "" TESTER
 SG_ VDC_FaultNum15 : 191|12@0+ (1.0,0.0) [0.0|4095.0] "" TESTER
 SG_ VDC_FaultNum16 : 195|12@0+ (1.0,0.0) [0.0|4095.0] "" TESTER
 SG_ VDC_FaultNum17 : 215|12@0+ (1.0,0.0) [0.0|4095.0] "" TESTER
 SG_ VDC_FaultNum18 : 219|12@0+ (1.0,0.0) [0.0|4095.0] "" TESTER
 SG_ VDC_FaultNum19 : 239|12@0+ (1.0,0.0) [0.0|4095.0] "" TESTER
 SG_ VDC_FaultNum2 : 27|12@0+ (1.0,0.0) [0.0|4095.0] "" TESTER
 SG_ VDC_FaultNum20 : 243|12@0+ (1.0,0.0) [0.0|4095.0] "" TESTER
 SG_ VDC_FaultNum3 : 47|12@0+ (1.0,0.0) [0.0|4095.0] "" TESTER
 SG_ VDC_FaultNum4 : 51|12@0+ (1.0,0.0) [0.0|4095.0] "" TESTER
 SG_ VDC_FaultNum5 : 71|12@0+ (1.0,0.0) [0.0|4095.0] "" TESTER
 SG_ VDC_FaultNum6 : 75|12@0+ (1.0,0.0) [0.0|4095.0] "" TESTER
 SG_ VDC_FaultNum7 : 95|12@0+ (1.0,0.0) [0.0|4095.0] "" TESTER
 SG_ VDC_FaultNum8 : 99|12@0+ (1.0,0.0) [0.0|4095.0] "" TESTER
 SG_ VDC_FaultNum9 : 119|12@0+ (1.0,0.0) [0.0|4095.0] "" TESTER
 SG_ VDC_FrameIndex : 12|5@0+ (1.0,0.0) [0.0|31.0] "" TESTER
 SG_ VDC_SupplierNum : 15|3@0+ (1.0,0.0) [0.0|7.0] "" TESTER
 SG_ VDC_TotalFaultNum : 7|8@0+ (1.0,0.0) [0.0|255.0] "" TESTER

BO_ 384 VDC_GCUCtrl : 32 VIU0
 SG_ VDC_GCUCtrl_Checksum : 7|16@0+ (1.0,0.0) [0.0|65535.0] "" PEU,PICU
 SG_ VDC_GCUCtrl_Counter : 23|8@0+ (1.0,0.0) [0.0|255.0] "" PEU,PICU
 SG_ VDC_GMotActvDampReq : 30|1@0+ (1,0) [0|1] "" PEU,PICU
 SG_ VDC_GMotEna : 31|1@0+ (1,0) [0|1] "" PEU,PICU
 SG_ VDC_GMotModReq : 29|4@0+ (1,0) [0|15] "" PEU,PICU
 SG_ VDC_GMotSpdReq : 63|16@0+ (1.0,-32768.0) [-32768.0|32767.0] "rpm" PEU,PICU
 SG_ VDC_GMotTqReq : 47|16@0+ (0.1,-3276.8) [-3276.8|3276.7] "Nm" PEU,PICU
 SG_ VDC_GMotVoltReq : 25|10@0+ (1.0,0.0) [0.0|800.0] "V" PEU,PICU
 SG_ VDC_MaxEleTqLim : 83|12@0+ (1.0,-2048.0) [-1500.0|1500.0] "Nm" PEU,PICU
 SG_ VDC_MaxGenTqLim : 79|12@0+ (1.0,-2048.0) [-1500.0|1500.0] "Nm" PEU,PICU

BO_ 385 VDC_HVCtrl : 32 VIU0
 SG_ VDC_ACChrgAllwdSts : 158|1@0+ (1,0) [0|1] "" BMS
 SG_ VDC_BMSDchaMaxPwr : 150|7@0+ (0.1,0.0) [0.0|12.700000000000001] "kW" BMS,CCU
 SG_ VDC_BMSHVConsumePower : 87|8@0+ (0.1,0.0) [0.0|25.0] "kW" BMS
 SG_ VDC_ChrgAlld : 28|1@0+ (1,0) [0|1] "" BMS
 SG_ VDC_ChrgPilePowerSupplyAllow : 59|1@0+ (1,0) [0|1] "" BMS
 SG_ VDC_ChrgPortLockSt : 173|2@0+ (1,0) [0|3] "" BMS
 SG_ VDC_ChrgStopType : 61|2@0+ (1,0) [0|3] "" BMS
 SG_ VDC_ChrgTrgtSOC : 127|7@0+ (1.0,0.0) [0.0|100.0] "%" BMS
 SG_ VDC_DCBoostChrgAllwdSts : 159|1@0+ (1,0) [0|1] "" BMS
 SG_ VDC_DCChrgAllwd : 155|4@0+ (1,0) [0|15] "" BMS
 SG_ VDC_DCDCEnableCmd : 31|3@0+ (1,0) [0|7] "" CCU
 SG_ VDC_DCDCMaxCurrtAlld : 55|10@0+ (0.5,0.0) [0.0|511.5] "A" CCU
 SG_ VDC_DCDCMaxPwrAlld : 47|8@0+ (0.1,0.0) [0.0|15.0] "kW" TESTER
 SG_ VDC_DCDCSetVolt : 39|8@0+ (0.1,0.0) [0.0|25.400000000000002] "V" CCU
 SG_ VDC_DchaAllwdSts : 151|1@0+ (1,0) [0|1] "" BMS
 SG_ VDC_DchaStopType : 116|2@0+ (1,0) [0|3] "" BMS
 SG_ VDC_ExtrLoTMod : 175|2@0+ (1,0) [0|3] "" TESTER
 SG_ VDC_HeatMod : 157|2@0+ (1,0) [0|3] "" BMS,PICU
 SG_ VDC_HVBattHVONCmd : 27|4@0+ (1,0) [0|15] "" BMS
 SG_ VDC_HVCtrl_Checksum : 7|16@0+ (1.0,0.0) [0.0|65535.0] "" BMS,CCU
 SG_ VDC_HVCtrl_Counter : 23|8@0+ (1.0,0.0) [0.0|255.0] "" BMS,CCU
 SG_ VDC_NavChrgThermReq : 57|2@0+ (1,0) [0|3] "" BMS
 SG_ VDC_OBCACCurrtMaxPerm : 95|7@0+ (1.0,0.0) [0.0|100.0] "A" BMS,CCU
 SG_ VDC_PTCPwrReq : 167|8@0+ (0.1,0.0) [0.0|25.400000000000002] "kw" PICU
 SG_ VDC_TDUHVPwrLimMax : 111|8@0+ (0.1,0.0) [0.0|25.400000000000002] "kW" PICU
 SG_ VDC_TDUModReq : 119|3@0+ (1,0) [0|7] "" PICU
 SG_ VDC_VehDCChrgCurrtLimit : 88|9@0+ (2.0,0.0) [0.0|1000.0] "A" BMS

BO_ 283 VDC_PTSt_VV01 : 32 VIU0
 SG_ VDC_AccPedalAcPositionValid : 74|1@0+ (1,0) [0|1] "" PICU
 SG_ VDC_AccPedalActualPosition : 73|10@0+ (0.1,0.0) [0.0|102.30000000000001] "%" PICU
 SG_ VDC_AccPedalPosition : 71|10@0+ (0.1,0.0) [0.0|102.30000000000001] "%" PICU
 SG_ VDC_AccPedalPositionValid : 77|1@0+ (1,0) [0|1] "" PICU
 SG_ VDC_ActualGear : 93|2@0+ (1,0) [0|3] "" PICU
 SG_ VDC_ActualGearValid : 94|1@0+ (1,0) [0|1] "" PICU
 SG_ VDC_AdsLowPowCmd : 202|3@0+ (1,0) [0|7] "" TESTER
 SG_ VDC_BMS_SOC : 143|8@0+ (1.0,0.0) [0.0|255.0] "%" TESTER
 SG_ VDC_BrakePedalFeelSet : 145|2@0+ (1,0) [0|3] "" TESTER
 SG_ VDC_brakePedalSts : 111|1@0+ (1,0) [0|1] "" PICU
 SG_ VDC_brakePedalStsValid : 110|1@0+ (1,0) [0|1] "" PICU
 SG_ VDC_CDC_OnHighwaySt : 199|2@0+ (1,0) [0|3] "" TESTER
 SG_ VDC_CDCremindReq : 178|3@0+ (1,0) [0|7] "" TESTER
 SG_ VDC_CompositeRang : 39|11@0+ (1.0,0.0) [0.0|2047.0] "km" PEU,PICU
 SG_ VDC_driveReady : 97|2@0+ (1,0) [0|3] "" TESTER
 SG_ VDC_DrvMod : 167|4@0+ (1,0) [0|15] "" PICU
 SG_ VDC_DrvrAccrPedlOvrd : 117|1@0+ (1,0) [0|1] "" TESTER
 SG_ VDC_DrvrGearOvrd : 115|1@0+ (1,0) [0|1] "" TESTER
 SG_ VDC_ECASFuncLimit : 209|2@0+ (1,0) [0|3] "" TESTER
 SG_ VDC_ECASHeightAdjust : 213|3@0+ (1,0) [0|7] "" TESTER
 SG_ VDC_ECASMaintenanceMode : 215|2@0+ (1,0) [0|3] "" TESTER
 SG_ VDC_EDCModeSet : 151|3@0+ (1,0) [0|7] "" TESTER
 SG_ VDC_epbRequest : 103|2@0+ (1,0) [0|3] "" TESTER
 SG_ VDC_epbRequestValid : 98|1@0+ (1,0) [0|1] "" TESTER
 SG_ VDC_EPSModeRequest : 114|3@0+ (1,0) [0|7] "" TESTER
 SG_ VDC_ESCdriveReady : 119|2@0+ (1,0) [0|3] "" TESTER
 SG_ VDC_ESCModeSet : 159|3@0+ (1,0) [0|7] "" TESTER
 SG_ VDC_GearShiftAvl : 116|1@0+ (1,0) [0|1] "" TESTER
 SG_ VDC_HV_State : 109|3@0+ (1,0) [0|7] "" PICU
 SG_ VDC_LVEM_LoEgyCnsModReq : 241|2@0+ (1,0) [0|3] "" TESTER
 SG_ VDC_OnePedalstatus : 210|1@0+ (1,0) [0|1] "" TESTER
 SG_ VDC_PTSt_Checksum : 7|16@0+ (1.0,0.0) [0.0|65535.0] "" PICU
 SG_ VDC_PTSt_RollingCounter : 23|8@0+ (1.0,0.0) [0.0|255.0] "" PICU
 SG_ VDC_PtTqAvl : 243|2@0+ (1,0) [0|3] "" TESTER
 SG_ VDC_RegenModeStatus : 162|3@0+ (1,0) [0|7] "" TESTER
 SG_ VDC_targetGear : 89|2@0+ (1,0) [0|3] "" PICU
 SG_ VDC_targetGearValid : 90|1@0+ (1,0) [0|1] "" PICU
 SG_ VDC_TotalRang : 43|20@0+ (1.0,0.0) [0.0|1048575.0] "km" PEU,PICU
 SG_ VDC_towMode_VV01 : 101|2@0+ (1,0) [0|3] "" TESTER
 SG_ VDC_TraveMode : 131|3@0+ (1,0) [0|7] "" Vector_XXX
 SG_ VDC_VehicleStopTime : 197|10@0+ (1.0,0.0) [0.0|1023.0] "min" PICU
 SG_ VDC_VehicleStopTimeValid : 203|1@0+ (1,0) [0|1] "" PICU
 SG_ VDC_VehSpd : 223|13@0+ (0.05625,0.0) [0.0|460.74375000000003] "km/h" TESTER
 SG_ VDC_VehSpdDir : 76|2@0+ (1,0) [0|3] "" TESTER
 SG_ VDC_VehSpdVld : 226|2@0+ (1,0) [0|3] "" TESTER

BO_ 258 VDC_RMotCtrl : 32 VIU0
 SG_ VDC_RMcuWakUpReq : 26|1@0+ (1,0) [0|1] "" TC
 SG_ VDC_RMotActiveDampReq : 25|1@0+ (1,0) [0|1] "" TC
 SG_ VDC_RMotActiveDATSReq : 119|2@0+ (1,0) [0|3] "" TC
 SG_ VDC_RMotActvDampLvlReq : 117|2@0+ (1,0) [0|3] "" TC
 SG_ VDC_RMotCtrl_Checksum : 7|16@0+ (1.0,0.0) [0.0|65535.0] "" TC
 SG_ VDC_RMotCtrl_Counter : 23|8@0+ (1.0,0.0) [0.0|255.0] "" TC
 SG_ VDC_RMotEnable : 24|1@0+ (1,0) [0|1] "" TC
 SG_ VDC_RMotMaxDrvTqLimt : 87|12@0+ (1.0,-2048.0) [-1000.0|1000.0] "Nm" TC
 SG_ VDC_RMotMaxRegenTqLimt : 91|12@0+ (1.0,-2048.0) [-1000.0|1000.0] "Nm" TC
 SG_ VDC_RMotModReq : 31|4@0+ (1,0) [0|15] "" TC
 SG_ VDC_RMotSpdLimMax : 247|12@0+ (5.0,-3000.0) [-3000.0|17475.0] "rpm" TC
 SG_ VDC_RMotSpdRate : 226|11@0+ (5.0,-5115.0) [-5115.0|5120.0] "rpm/s" TC
 SG_ VDC_RMotSpdReq : 55|16@0+ (1.0,-32768.0) [-32768.0|32767.0] "rpm" TC
 SG_ VDC_RMotStopDst : 220|10@0+ (0.5,0.0) [0.0|511.5] "cm" TC
 SG_ VDC_RMotSVReplan : 251|2@0+ (1,0) [0|3] "" TC
 SG_ VDC_RMotTqRateLimMax : 206|9@0+ (5.0,-1275.0) [-1275.0|1280.0] "Nm/s" TC
 SG_ VDC_RMotTqRateLimMin : 199|9@0+ (5.0,-1275.0) [-1275.0|1280.0] "Nm/s" TC
 SG_ VDC_RMotTqReq : 39|16@0+ (0.1,-3276.8) [-3276.8|3276.7] "Nm" TC
 SG_ VDC_RMotTqUnloadEna : 111|2@0+ (1,0) [0|3] "" TC
 SG_ VDC_RMotTqUnloadRate : 213|9@0+ (5.0,-1275.0) [-1275.0|1280.0] "Nm/s" TC
 SG_ VDC_RMotTrackingMod : 249|2@0+ (1,0) [0|3] "" TC

BO_ 275 VDC_RMtTq_PT : 32 VIU0
 SG_ VDC_CoastRegenRequest_RA : 151|16@0+ (1.0,-32768.0) [-32768.0|32767.0] "N.m" TESTER
 SG_ VDC_CoastRegenRequest_RAValid : 136|1@0+ (1,0) [0|1] "" TESTER
 SG_ VDC_DriverTorqueDesired : 231|16@0+ (1.0,-32768.0) [-32768.0|32767.0] "N.m" TESTER
 SG_ VDC_MotorRegenTorqueInD_VV01 : 199|13@0+ (1.0,-8191.0) [-8191.0|0.0] "N.m" TESTER
 SG_ VDC_MotorRegenTorqueInDValid : 202|1@0+ (1,0) [0|1] "" TESTER
 SG_ VDC_MotorRegenTorqueLmtInD_VV01 : 215|13@0+ (1.0,-8191.0) [-8191.0|0.0] "N.m" TESTER
 SG_ VDC_MotorRegenTrqLmtInDValid : 200|1@0+ (1,0) [0|1] "" TESTER
 SG_ VDC_OPDHydBrkCompenRqSts : 40|1@0+ (1,0) [0|1] "" TESTER
 SG_ VDC_OPDHydBrkCompenRqTq : 55|16@0+ (1.0,-65535.0) [-65535.0|0.0] "Nm" TESTER
 SG_ VDC_OPDHydBrkCompenRqTqValid : 71|1@0+ (1,0) [0|1] "" TESTER
 SG_ VDC_PtTqActvSts : 217|1@0+ (1,0) [0|1] "" PICU
 SG_ VDC_rearMotorRegenTorqueInD : 115|12@0+ (1.0,-4095.0) [-4095.0|0.0] "N.m" TESTER
 SG_ VDC_rearMotorRegenTorqueInDValid : 116|1@0+ (1,0) [0|1] "" TESTER
 SG_ VDC_rearMotorRegenTorqueLmtInD : 135|12@0+ (1.0,-4095.0) [-4095.0|0.0] "N.m" TESTER
 SG_ VDC_rearMotorRegenTrqLmtInDValid : 139|1@0+ (1,0) [0|1] "" TESTER
 SG_ VDC_rearMotorRpm : 103|16@0+ (1.0,-30000.0) [-30000.0|35535.0] "RPM" TESTER
 SG_ VDC_rearMotorRpmValid : 119|1@0+ (1,0) [0|1] "" TESTER
 SG_ VDC_rearMotorTorquePed_VV01 : 85|14@0+ (1.0,-5000.0) [-5000.0|11383.0] "N.m" TESTER
 SG_ VDC_rearMotorTorquePedValid : 86|1@0+ (1,0) [0|1] "" TESTER
 SG_ VDC_rearMotorTorqueReqPed_VV01 : 69|14@0+ (1.0,-5000.0) [-5000.0|11383.0] "N.m" TESTER
 SG_ VDC_rearMotorTqReqPedValid : 70|1@0+ (1,0) [0|1] "" TESTER
 SG_ VDC_RMtTq_Checksum : 7|16@0+ (1.0,0.0) [0.0|65535.0] "" PICU
 SG_ VDC_RMtTq_RollingCounter : 23|8@0+ (1.0,0.0) [0.0|255.0] "" PICU
 SG_ VDC_vehicleTorqueMax : 165|14@0+ (1.0,0.0) [0.0|16383.0] "N.m" PICU
 SG_ VDC_vehicleTorqueMaxValid : 166|1@0+ (1,0) [0|1] "" PICU
 SG_ VDC_vehicleTorqueMin_VV01 : 181|14@0+ (1.0,-10000.0) [-10000.0|6383.0] "N.m" TESTER
 SG_ VDC_vehicleTorqueMinValid : 182|1@0+ (1,0) [0|1] "" PICU
 SG_ VDC_VehWhlActTq : 247|16@0+ (1.0,-32768.0) [-32768.0|32767.0] "N.m" PICU
 SG_ VDC_VehWhlActTqVld : 218|1@0+ (1,0) [0|1] "" PICU
 SG_ VDC_VehWhlReqTq : 31|16@0+ (1.0,-32768.0) [-32768.0|32767.0] "Nm" PICU
 SG_ VDC_VehWhlReqTqVld : 47|1@0+ (1,0) [0|1] "" PICU

BO_ 388 VDC_SysState : 32 VIU0
 SG_ VDC_AccPedalPos : 41|10@0+ (0.1,0.0) [0.0|100.0] "%" PICU,TC,TESTER
 SG_ VDC_AccrPedlUFirst : 84|13@0+ (0.001,0.0) [0.0|5.0] "V" PICU,TESTER
 SG_ VDC_AccrPedlUFirst_Input : 164|13@0+ (0.001,0.0) [0.0|6.0] "V" PICU,TESTER
 SG_ VDC_AccrPedlUSecond : 100|13@0+ (0.001,0.0) [0.0|3.0] "V" PICU,TESTER
 SG_ VDC_AccrPedlUSecond_Input : 180|13@0+ (0.001,0.0) [0.0|6.0] "V" PICU,TESTER
 SG_ VDC_ActGearSt : 31|4@0+ (1,0) [0|15] "" BMS,CCU,PEU,PICU,TC
 SG_ VDC_BrkPedalPressed : 42|1@0+ (1,0) [0|1] "" PICU,TC
 SG_ VDC_BrkPedalPressedValid : 43|1@0+ (1,0) [0|1] "" PICU,TC
 SG_ VDC_KeyOnSt : 27|1@0+ (1,0) [0|1] "" TESTER
 SG_ VDC_PowerMode : 47|2@0+ (1,0) [0|3] "" TESTER
 SG_ VDC_PTReadySt : 35|1@0+ (1,0) [0|1] "" BMS,PEU,PICU,TC
 SG_ VDC_RoadSlop : 151|9@0+ (0.2,-50.0) [-50.0|50.0] "deg" PICU
 SG_ VDC_RoadSlopRate : 158|9@0+ (0.2,-50.0) [-50.0|50.0] "deg/s" PICU
 SG_ VDC_SysFaultLevel_VV01 : 39|4@0+ (1,0) [0|15] "" PICU,TESTER
 SG_ VDC_SysState_Checksum : 7|16@0+ (1.0,0.0) [0.0|65535.0] "" BMS,CCU,PICU,TC
 SG_ VDC_SysState_Counter : 23|8@0+ (1.0,0.0) [0.0|255.0] "" BMS,CCU,PICU,TC
 SG_ VDC_TargetGearSt : 26|3@0+ (1,0) [0|7] "" PEU,PICU,TESTER
 SG_ VDC_VehPowerSt : 34|3@0+ (1,0) [0|7] "" TESTER

BO_ 785 VDC_VehState : 32 VIU0
 SG_ VDC_AccMod : 62|4@0+ (1,0) [0|15] "" PICU,TC
 SG_ VDC_CDC_ACChrgCurrtSet : 190|7@0+ (0.5,0.0) [0.0|63.0] "A" BMS
 SG_ VDC_ChrgFaultSt : 95|5@0+ (1,0) [0|31] "" TESTER
 SG_ VDC_ChrgLockSts : 79|2@0+ (1,0) [0|3] "" BMS
 SG_ VDC_CoastRegnSt : 42|3@0+ (1,0) [0|7] "" TESTER
 SG_ VDC_CoolSysOTSt : 29|1@0+ (1,0) [0|1] "" TESTER
 SG_ VDC_CooltLvlStatus : 174|2@0+ (1,0) [0|3] "" PICU
 SG_ VDC_CreepModSt : 44|1@0+ (1,0) [0|1] "" TESTER
 SG_ VDC_DCScheduleChrgAlld : 168|1@0+ (1,0) [0|1] "" BMS
 SG_ VDC_DrvMod_VV01 : 39|4@0+ (1,0) [0|15] "" BMS,PICU,TC
 SG_ VDC_EstimdSlop : 183|8@0+ (0.5,-50.0) [-50.0|50.0] "deg" PICU
 SG_ VDC_EstimdSlopVld : 172|1@0+ (1,0) [0|1] "" PICU
 SG_ VDC_FactoryReset : 56|1@0+ (1,0) [0|1] "" PICU
 SG_ VDC_GearFailedWarnInfo : 90|3@0+ (1,0) [0|7] "" TESTER
 SG_ VDC_HVAllowSts : 150|3@0+ (1,0) [0|7] "" TESTER
 SG_ VDC_HVBattFaultSt : 31|1@0+ (1,0) [0|1] "" TESTER
 SG_ VDC_LowSOCSt : 175|1@0+ (1,0) [0|1] "" TESTER
 SG_ VDC_LowSocWarn : 86|3@0+ (1,0) [0|7] "" TESTER
 SG_ VDC_LVBattChrgFault : 103|4@0+ (1,0) [0|15] "" TESTER
 SG_ VDC_LVBattChrgReqSt : 171|3@0+ (1,0) [0|7] "" TESTER
 SG_ VDC_LVBattChrgSt : 51|4@0+ (1,0) [0|15] "" TESTER
 SG_ VDC_LVBattFaultSt : 52|1@0+ (1,0) [0|1] "" TESTER
 SG_ VDC_MCUPwrAct : 231|8@0+ (0.1,0.0) [0.0|25.400000000000002] "kw" TESTER
 SG_ VDC_MCUPwrReq : 223|8@0+ (0.1,0.0) [0.0|25.400000000000002] "kw" TESTER
 SG_ VDC_MotFaultSt : 87|1@0+ (1,0) [0|1] "" TESTER
 SG_ VDC_NavTunnelSt : 205|1@0+ (1,0) [0|1] "" PICU
 SG_ VDC_OnePedlModSt : 47|2@0+ (1,0) [0|3] "" TC
 SG_ VDC_PwrLimitSt : 28|1@0+ (1,0) [0|1] "" TESTER
 SG_ VDC_RemThermReq : 215|2@0+ (1,0) [0|3] "" BMS
 SG_ VDC_RemThermTiCalcdReq : 213|2@0+ (1,0) [0|3] "" BMS
 SG_ VDC_RepairModeSts : 202|2@0+ (1,0) [0|3] "" TESTER
 SG_ VDC_ScheduleChrgCtrlSts : 67|4@0+ (1,0) [0|15] "" TESTER
 SG_ VDC_ScheduleChrgStartStopCmd : 71|4@0+ (1,0) [0|15] "" TESTER
 SG_ VDC_ShiftGearWarnSt : 27|4@0+ (1,0) [0|15] "" TESTER
 SG_ VDC_SpdLimWarn : 43|1@0+ (1,0) [0|1] "" TESTER
 SG_ VDC_SysFaultText : 99|4@0+ (1,0) [0|15] "" TESTER
 SG_ VDC_TempExclusivePassFlg : 211|2@0+ (1,0) [0|3] "" PICU
 SG_ VDC_TempExclusiveRearFlg : 209|2@0+ (1,0) [0|3] "" PICU
 SG_ VDC_TempExclusiveRearRiFlg : 207|2@0+ (1,0) [0|3] "" PICU
 SG_ VDC_TimeChargeSwtichSts : 58|1@0+ (1,0) [0|1] "" BMS
 SG_ VDC_TVModSt : 45|1@0+ (1,0) [0|1] "" TESTER
 SG_ VDC_Usagemode : 55|3@0+ (1,0) [0|7] "" TESTER
 SG_ VDC_VehFaultLevel : 83|4@0+ (1,0) [0|15] "" TESTER
 SG_ VDC_VehModSt : 35|4@0+ (1,0) [0|15] "" TESTER
 SG_ VDC_VehState_Checksum : 7|16@0+ (1.0,0.0) [0.0|65535.0] "" CCU
 SG_ VDC_VehState_Counter : 23|8@0+ (1.0,0.0) [0.0|255.0] "" CCU
 SG_ VDC_VehSysWarnSt : 30|1@0+ (1,0) [0|1] "" TESTER
 SG_ VDC_WeakRegnRemind : 63|1@0+ (1,0) [0|1] "" TESTER

BO_ 788 VDC_VehSts : 32 VIU0
 SG_ VDC_EnaCmd_EAS : 71|1@0+ (1,0) [0|1] "" TESTER
 SG_ VDC_EngCrankReason : 159|16@0+ (1.0,0.0) [0.0|65535.0] "" TESTER
 SG_ VDC_EngIdleReason : 143|16@0+ (1.0,0.0) [0.0|65535.0] "" TESTER
 SG_ VDC_EngNotReadyReason : 70|5@0+ (1,0) [0|31] "" PICU
 SG_ VDC_EngStartForbidReason : 175|4@0+ (1,0) [0|15] "" TESTER
 SG_ VDC_EngStartReason : 79|32@0+ (1.0,0.0) [0.0|4294967295.0] "" TESTER
 SG_ VDC_EngStartSOCCurrtMod : 183|7@0+ (1.0,0.0) [0.0|100.0] "" TESTER
 SG_ VDC_EngStopReason : 111|32@0+ (1.0,0.0) [0.0|4294967295.0] "" TESTER
 SG_ VDC_EngStopSOCCurrtMod : 191|7@0+ (1.0,0.0) [0.0|100.0] "" TESTER
 SG_ VDC_FuelAddingAlldSt : 65|2@0+ (1,0) [0|3] "" TESTER
 SG_ VDC_ReevVHRSignal1 : 199|8@0+ (1.0,0.0) [0.0|255.0] "" TESTER
 SG_ VDC_ReevVHRSignal2 : 207|8@0+ (1.0,0.0) [0.0|255.0] "" TESTER
 SG_ VDC_ReevVHRSignal3 : 215|8@0+ (1.0,0.0) [0.0|255.0] "" TESTER
 SG_ VDC_ReevVHRSignal4 : 223|8@0+ (1.0,0.0) [0.0|255.0] "" TESTER
 SG_ VDC_ReevVHRSignal5 : 231|8@0+ (1.0,0.0) [0.0|255.0] "" TESTER
 SG_ VDC_TarSpdCmd_EAS : 55|16@0+ (0.25,0.0) [0.0|16383.75] "rpm" TESTER
 SG_ VDC_TotalRang_1 : 31|24@0+ (0.1,0.0) [0.0|1677721.5] "km" PEU,PICU

BO_ 1456 VDC_Version : 32 VIU0
 SG_ VDC_HwVersion : 23|8@0+ (1.0,0.0) [0.0|255.0] "" TESTER
 SG_ VDC_SupplierCode : 7|16@0+ (1.0,0.0) [0.0|65535.0] "" TESTER
 SG_ VDC_SwMajorVersion : 31|8@0+ (1.0,0.0) [0.0|255.0] "" TESTER
 SG_ VDC_SwMinorVersion : 39|8@0+ (1.0,0.0) [0.0|255.0] "" TESTER
 SG_ VDC_SwPatchVersion : 47|8@0+ (1.0,0.0) [0.0|255.0] "" TESTER
 SG_ VDC_SwVersionDay : 71|8@0+ (1.0,0.0) [0.0|31.0] "" TESTER
 SG_ VDC_SwVersionMonth : 63|8@0+ (1.0,0.0) [0.0|12.0] "" TESTER
 SG_ VDC_SwVersionYear : 55|8@0+ (1.0,0.0) [0.0|255.0] "" TESTER

BO_ 857 VIU_API2CAN_EVR : 32 VIU0
 SG_ VIU_AmbT : 35|12@0+ (0.1,-48.0) [-48.0|80.0] "℃" PICU
 SG_ VIU_AmbTVld : 55|1@0+ (1,0) [0|1] "" PICU
 SG_ VIU_API2CAN_EMS_GCU_Checksum : 7|16@0+ (1.0,0.0) [0.0|65535.0] "" PICU
 SG_ VIU_API2CAN_EMS_GCU_Counter : 23|8@0+ (1.0,0.0) [0.0|255.0] "" PICU
 SG_ VIU_FuelSigFlt : 38|3@0+ (1,0) [0|7] "" PICU
 SG_ VIU_HVFuelRleaseRequest : 54|2@0+ (1,0) [0|3] "" PICU
 SG_ VIU_OilSnsrResistorVal : 31|9@0+ (1.0,0.0) [0.0|509.0] "Ω" PICU

BO_ 688 VIU_DoorLock_VV01 : 32 VIU0
 SG_ VIU_DoorLock_Chks : 7|16@0+ (1.0,0.0) [0.0|65535.0] "" PICU
 SG_ VIU_DoorLock_Cntr : 23|8@0+ (1.0,0.0) [0.0|255.0] "" PICU
 SG_ VIU_FuCapSt : 45|2@0+ (1,0) [0|3] "" PICU

BO_ 467 VIU_Info_VV02 : 32 VIU0
 SG_ VIU_CarMode : 27|4@0+ (1,0) [0|15] "" BMS,CCU,PEU,PICU,TC
 SG_ VIU_Info_Checksum_VV01 : 7|16@0+ (1.0,0.0) [0.0|65535.0] "" BMS,CCU,PEU,PICU,TC
 SG_ VIU_Info_Counter : 23|8@0+ (1.0,0.0) [0.0|255.0] "" BMS,CCU,PEU,PICU,TC
 SG_ VIU_PowerMode : 39|2@0+ (1,0) [0|3] "" BMS,CCU,PEU,PICU,TC
 SG_ VIU_PowerModeFltFlag : 37|2@0+ (1,0) [0|3] "" BMS,PICU,TC
 SG_ VIU_UsageMode : 31|4@0+ (1,0) [0|15] "" BMS,CCU,PEU,PICU,TC
 SG_ VIU_VehAntithftSt : 87|3@0+ (1,0) [0|7] "" PICU

BO_ 856 VIU_Route_EP : 32 VIU0
 SG_ RSM_AirT : 82|11@0+ (0.1,-39.6) [-39.6|100.0] "℃" PICU
 SG_ RSM_DewPointT : 111|11@0+ (0.1,-39.6) [-39.6|100.0] "℃" PICU
 SG_ RSM_HumTFlt : 85|1@0+ (1,0) [0|1] "" PICU
 SG_ RSM_LeSolarInten : 159|8@0+ (5.0,0.0) [0.0|1265.0] "" PICU
 SG_ RSM_LiSnsrErr : 84|1@0+ (1,0) [0|1] "" PICU
 SG_ RSM_Rainfall : 116|2@0+ (1,0) [0|3] "" PICU
 SG_ RSM_RainSnsrErr : 83|1@0+ (1,0) [0|1] "" PICU
 SG_ RSM_RelHum : 103|8@0+ (0.5,-0.5) [-0.5|100.0] "%" PICU
 SG_ RSM_RiSolarInten : 167|8@0+ (5.0,0.0) [0.0|1265.0] "" PICU
 SG_ RSM_WinT : 114|11@0+ (0.1,-39.6) [-39.6|100.0] "℃" PICU
 SG_ VIU_Reserved : 184|1@0+ (1.0,0.0) [0.0|1.0] "" TESTER
 SG_ VIU_Route_EP_Checksum : 7|16@0+ (1.0,0.0) [0.0|65535.0] "" BMS,CCU
 SG_ VIU_Route_EP_Counter : 23|8@0+ (1.0,0.0) [0.0|255.0] "" BMS,CCU

BO_ 463 VIU_Route_EP_2 : 32 VIU0
 SG_ ADS_MotSpdCtrlEna : 56|1@0+ (1,0) [0|1] "" TC
 SG_ CS_FWiperMistReq : 44|2@0+ (1,0) [0|3] "" PICU
 SG_ CS_FWiperSwtReq : 47|3@0+ (1,0) [0|7] "" PICU
 SG_ CS_FWiperWashReq : 42|2@0+ (1,0) [0|3] "" PICU
 SG_ EPS_SteerWheelAngle : 31|14@0+ (0.1,-780.0) [-780.0|858.3000000000002] "deg" TC
 SG_ EPS_SteerWheelAngleValid : 33|1@0+ (1,0) [0|1] "" TC
 SG_ IBS_AVHAvailable : 53|1@0+ (1,0) [0|1] "" TC
 SG_ IBS_AVHStatus : 55|2@0+ (1,0) [0|3] "" TC
 SG_ IBS_ESCOFF_Status : 40|1@0+ (1,0) [0|1] "" TC
 SG_ VIU_Route_EP_2_Checksum : 7|16@0+ (1.0,0.0) [0.0|65535.0] "" TC
 SG_ VIU_Route_EP_2_Counter : 23|8@0+ (1.0,0.0) [0.0|255.0] "" TC

BO_ 796 VIU_Route_EVR_1 : 32 VIU0
 SG_ IBS_OBDFaultExistSts : 102|1@0+ (1,0) [0|1] "" PICU
 SG_ IPB_OBD_MILOnReq : 88|1@0+ (1,0) [0|1] "" PICU
 SG_ VIU_Route_EMS_GCU_1_Checksum : 7|16@0+ (1.0,0.0) [0.0|65535.0] "" PEU,PICU
 SG_ VIU_Route_EMS_GCU_1_Counter : 23|8@0+ (1.0,0.0) [0.0|255.0] "" PEU,PICU

CM_ SG_ 267 MCUR_CBKTq "MCUR 舒适制动扭矩值";
CM_ SG_ 267 MCUR_CurrtPhaA "后电机A相电流";
CM_ SG_ 267 MCUR_CurrtPhaB "后电机B相电流";
CM_ SG_ 267 MCUR_CurrtPhaC "后电机C相电流";
CM_ SG_ 267 MCUR_DATSTq "MCUR DATS扭矩值";
CM_ SG_ 267 MCUR_DCCurrt "MCUR直流母线电流";
CM_ SG_ 267 MCUR_DCVolt "MCUR直流母线电压";
CM_ SG_ 267 MCUR_FaultLamp "后电机系统故障指示灯控制";
CM_ SG_ 267 MCUR_IGBTNTCTempA "IGBT NTC温度A";
CM_ SG_ 267 MCUR_IGBTNTCTempB "IGBT NTC温度B";
CM_ SG_ 267 MCUR_IGBTNTCTemPC "IGBT NTC温度C";
CM_ SG_ 267 MCUR_KL30_Volt "MCUR KL30电压";
CM_ SG_ 267 MCUR_MIL_Request "后电机点MIL灯请求(EVR需求)";
CM_ SG_ 267 MCUR_OBDFaultExistSts "当前驾驶循环MCUF监测OBD实时故障标志位";
CM_ SG_ 267 MCUR_RMotActvDampLvlSt "后电机主动阻尼档位状态(三电机默认左后)";
CM_ SG_ 267 MCUR_RMotTqContnsMax "后电机持续最大扭矩限值";
CM_ SG_ 267 MCUR_RMotTqContnsMin "后电机持续最小扭矩限值";
CM_ SG_ 267 MCUR_RMotTqLongMax "后电机长时最大扭矩限值";
CM_ SG_ 267 MCUR_RMotTqLongMin "后电机长时最小扭矩限值";
CM_ SG_ 267 MCUR_RMotTqShoMax "后电机短时最大扭矩限值";
CM_ SG_ 267 MCUR_RMotTqShoMin "后电机短时最小扭矩限值";
CM_ SG_ 267 MCUR_State_2_Checksum "CRC16 checksum  (DataID: 0x810B)";
CM_ SG_ 267 MCUR_State_2_Counter "Rolling Counter";
CM_ SG_ 854 MCUR_CBKEnaSt "MCUR 舒适制动开启状态";
CM_ SG_ 854 MCUR_DATSEnableSt "MCUR DATS开启状态";
CM_ SG_ 854 MCUR_DCHV_OverU_OBDFlt "后电机直流软件过压";
CM_ SG_ 854 MCUR_EOP_Actual_Speed "油泵反馈的实际转速占空步进值
F=(N/255)*100";
CM_ SG_ 854 MCUR_EOP_AIRmix_Fault "空吸(干转)故障";
CM_ SG_ 854 MCUR_EOP_Current "油泵反馈的实际电流";
CM_ SG_ 854 MCUR_EOP_MOS_Temp "油泵反馈的实际MOS温度";
CM_ SG_ 854 MCUR_EOP_Over_Current_Fault "过流故障";
CM_ SG_ 854 MCUR_EOP_Over_Temp_Fault "过温停机故障";
CM_ SG_ 854 MCUR_EOP_Over_Voltage_Fault "过压故障";
CM_ SG_ 854 MCUR_EOP_Self_Check_Fault "自检故障";
CM_ SG_ 854 MCUR_EOP_State "油泵反馈的运行状态";
CM_ SG_ 854 MCUR_EOP_Stuck_Fault "堵转故障";
CM_ SG_ 854 MCUR_EOP_Target_Speed "油泵目标转速占空步进值
F=(N/255)*100";
CM_ SG_ 854 MCUR_EOP_Under_Voltage_Fault "欠压故障";
CM_ SG_ 854 MCUR_EOP_Voltage "油泵反馈的实际电压";
CM_ SG_ 854 MCUR_HVAuxPwrSt "MCUR 高压辅源开启状态";
CM_ SG_ 854 MCUR_HVCalSt "MCUR 母线电压校准状态";
CM_ SG_ 854 MCUR_HWWakeupSt "硬线唤醒源状态";
CM_ SG_ 854 MCUR_IGBTOverTWarn_OBDFlt "后电机IGBT过温";
CM_ SG_ 854 MCUR_KL30_OverU_OBDFlt "后电机低压电源过压";
CM_ SG_ 854 MCUR_MotOverTWarn_OBDFlt "后电机电机过温";
CM_ SG_ 854 MCUR_PCBTemp "控制器单板温度";
CM_ SG_ 854 MCUR_RMotHeatActPwr "后电机制热功率";
CM_ SG_ 854 MCUR_RMotHeatMaxPwr "后电机最大制热功率";
CM_ SG_ 854 MCUR_RMotHeatSt "后电机制热状态";
CM_ SG_ 1459 MCUR_HwVersion "硬件版本号";
CM_ SG_ 1459 MCUR_SupplierCode "供应商代码";
CM_ SG_ 1459 MCUR_SwMajorVersion "软件主版本号";
CM_ SG_ 1459 MCUR_SwMinorVersion "软件子版本号";
CM_ SG_ 1459 MCUR_SwPatchVersion "软件补充版本号";
CM_ SG_ 1459 MCUR_SwVersionDay "软件版本日";
CM_ SG_ 1459 MCUR_SwVersionMonth "软件版本月";
CM_ SG_ 1459 MCUR_SwVersionYear "软件版本年-2000";
CM_ SG_ 896 TBOX_ACDefrostSet "远程除霜设置";
CM_ SG_ 896 TBOX_ACONOFFSet "远程空调开启设置";
CM_ SG_ 896 Tbox_ACParkAutoVentSetSts "驻车自动通风设置开关状态";
CM_ SG_ 896 TBOX_ACTempSet "远程温度设置";
CM_ SG_ 896 TBOX_ACVentSet "远程通风设置";
CM_ SG_ 896 TBOX_MaxACSet "远程速冷设置";
CM_ SG_ 896 TBOX_MaxHeatSet "远程速热设置";
CM_ SG_ 896 VDC_ScheduleChrgEndHour "预约充电结束时间_时";
CM_ SG_ 896 VDC_ScheduleChrgEndMin "预约充电结束时间_分";
CM_ SG_ 896 VDC_ScheduleChrgStarMin "预约充电开始时间_分";
CM_ SG_ 896 VDC_ScheduleChrgStartHour "预约充电开始时间_时";
CM_ SG_ 1506 TBOX_DSTFlag "夏令时标志位";
CM_ SG_ 1506 TBOX_TimeDay "本地时间_日";
CM_ SG_ 1506 TBOX_TimeFlag "时间有效性标志";
CM_ SG_ 1506 TBOX_TimeHour "本地时间_时";
CM_ SG_ 1506 TBOX_TimeMinute "本地时间_分";
CM_ SG_ 1506 TBOX_TimeMonth "本地时间_月";
CM_ SG_ 1506 TBOX_TimeSecond "本地时间_秒";
CM_ SG_ 1506 TBOX_TimeYear "本地时间_年";
CM_ SG_ 1506 TBOX_TimeZone "东/西时区";
CM_ SG_ 1506 TBOX_TimeZoneMinute "时区信息_分钟";
CM_ SG_ 1506 TBOX_TimeZoneNum "时区编号";
CM_ SG_ 820 TDU_ACMainSwtSts "空调总开关状态";
CM_ SG_ 820 TDU_ACMaxSts "最大制冷状态";
CM_ SG_ 820 TDU_ACSts "AC压缩机状态";
CM_ SG_ 820 TDU_ACSyncSts "温区同步状态";
CM_ SG_ 820 TDU_ACWorkModeSts "空调系统模式状态(制冷,制热,通风)(预留)";
CM_ SG_ 820 TDU_AutoDefogRunSts "自动除雾运行状态";
CM_ SG_ 820 TDU_AutoDefogSts "自动除雾状态";
CM_ SG_ 820 TDU_CircModSts "内外循环状态";
CM_ SG_ 820 TDU_DriverTempSts "主驾温度值设定状态";
CM_ SG_ 820 TDU_FBlowModeAutoSts "前空调吹风模式自动状态";
CM_ SG_ 820 TDU_FHvacBlowLv "前排风量档位";
CM_ SG_ 820 TDU_FHvacBlowLvAutoSts "前空调箱风量自动状态";
CM_ SG_ 820 TDU_FogRiskLvl "起雾风险等级";
CM_ SG_ 820 TDU_FrontAutoSts "前空调AUTO状态";
CM_ SG_ 820 TDU_FrontBlowModeSts "前排吹风模式状态";
CM_ SG_ 820 TDU_FrontDefrostSts "前除霜状态";
CM_ SG_ 820 TDU_HeatMaxSts "最大制热状态";
CM_ SG_ 820 TDU_InsdTemp "车内温度";
CM_ SG_ 820 TDU_OutdTemp "车外环境温度";
CM_ SG_ 820 TDU_ParkAutoVentSts "驻车自动通风状态";
CM_ SG_ 820 TDU_PassengerTemptSts "副驾温度值设定状态";
CM_ SG_ 820 TDU_RACMainSwtSts "后空调开关状态";
CM_ SG_ 820 TDU_TempExclusiveSts "温区独享状态(单席)";
CM_ SG_ 820 TDU_UnlockVentSt "解锁通风状态";
CM_ SG_ 827 TDU_ACECOModSts "空调ECO模式状态";
CM_ SG_ 827 TDU_AGS1_Position_Cmd "目标位置指令";
CM_ SG_ 827 TDU_AutoDrySts "空调自干燥状态";
CM_ SG_ 827 TDU_RemDefrostSts "远程除霜工作状态";
CM_ SG_ 827 TDU_RemFaultSts "空调故障反馈(远控)";
CM_ SG_ 827 TDU_RemSts "远程空调工作状态";
CM_ SG_ 827 TDU_RemTempSetSts "远程温度设定状态";
CM_ SG_ 827 TDU_VentSts "通风反馈信号";
CM_ SG_ 825 TDU_EnaCmd_EAS "EAS使能指令";
CM_ SG_ 825 TDU_EnaCmd_WTC_H "WTC_H使能指令";
CM_ SG_ 825 TDU_TrgtGear_WTC_H "WTC_H目标挡位";
CM_ SG_ 825 TDU_TrgtPwrReq_WTC_H "WTC_H目标功率需求";
CM_ SG_ 825 TDU_TrgtSpdCmd_EAS "压缩机目标转速指令";
CM_ SG_ 823 TDU_CVM_B_ActPerc "三通水阀CVM_B实际开度";
CM_ SG_ 823 TDU_CVM_B_TrgtPerc "三通水阀CVM_B目标开度";
CM_ SG_ 823 TDU_CVM_H_ActPerc "三通水阀CVM_H实际开度";
CM_ SG_ 823 TDU_CVM_H_TrgtPerc "三通水阀CVM_H目标开度";
CM_ SG_ 823 TDU_EngingstartReq "发动机启动请求";
CM_ SG_ 823 TDU_EngPmpSpdHeatReq "基于采暖请求对EMS发动机水泵请求信号";
CM_ SG_ 823 TDU_EngPmpSpdHeatReqVld "基于采暖请求对EMS发动机水泵请求信号有效位";
CM_ SG_ 823 TDU_EXV_B_LPTSnsrP "EXV_B出口低压压力温度传感器压力值";
CM_ SG_ 823 TDU_EXV_B_LPTSnsrT "EXV_B出口低压压力温度传感器温度值";
CM_ SG_ 823 TDU_EXV_H_LPTSnsrP "EXV_H出口低压压力温度传感器压力值";
CM_ SG_ 823 TDU_EXV_H_LPTSnsrT "EXV_H出口低压压力温度传感器温度值";
CM_ SG_ 823 TDU_FWV_CCWFlg "四通阀逆时针状态";
CM_ SG_ 823 TDU_FWV_FltSt "四通阀故障状态";
CM_ SG_ 823 TDU_FWV_InitSta "四通阀初始化状态";
CM_ SG_ 823 TDU_FWV_location "四通阀位置请求";
CM_ SG_ 823 TDU_FWV_location_FB "四通阀位置反馈";
CM_ SG_ 823 TDU_FWV_MotorSta "四通阀电机工作状态";
CM_ SG_ 823 TDU_FWV_MoveEnable "四通阀电机工作请求";
CM_ SG_ 823 TDU_FWV_ReqMotorEmgyStop "四通阀电机紧急停机请求";
CM_ SG_ 823 TDU_FWV_ReqMotorOptRecovery "四通阀电机位置复位请求";
CM_ SG_ 823 TDU_IcoInlT "中冷器的进水温度";
CM_ SG_ 1420 TDU_FaultNum1 "故障编号1";
CM_ SG_ 1420 TDU_FaultNum10 "故障编号10";
CM_ SG_ 1420 TDU_FaultNum11 "故障编号11";
CM_ SG_ 1420 TDU_FaultNum12 "故障编号12";
CM_ SG_ 1420 TDU_FaultNum13 "故障编号13";
CM_ SG_ 1420 TDU_FaultNum14 "故障编号14";
CM_ SG_ 1420 TDU_FaultNum15 "故障编号15";
CM_ SG_ 1420 TDU_FaultNum16 "故障编号16";
CM_ SG_ 1420 TDU_FaultNum17 "故障编号17";
CM_ SG_ 1420 TDU_FaultNum18 "故障编号18";
CM_ SG_ 1420 TDU_FaultNum19 "故障编号19";
CM_ SG_ 1420 TDU_FaultNum2 "故障编号2";
CM_ SG_ 1420 TDU_FaultNum20 "故障编号20";
CM_ SG_ 1420 TDU_FaultNum3 "故障编号3";
CM_ SG_ 1420 TDU_FaultNum4 "故障编号4";
CM_ SG_ 1420 TDU_FaultNum5 "故障编号5";
CM_ SG_ 1420 TDU_FaultNum6 "故障编号6";
CM_ SG_ 1420 TDU_FaultNum7 "故障编号7";
CM_ SG_ 1420 TDU_FaultNum8 "故障编号8";
CM_ SG_ 1420 TDU_FaultNum9 "故障编号9";
CM_ SG_ 1420 TDU_FrameIndex "帧序号";
CM_ SG_ 1420 TDU_SupplierNum "供应商代码";
CM_ SG_ 1420 TDU_TotalFaultNum "当前故障总数";
CM_ SG_ 821 TDU_CircHybThrMotActPerc "内外循环风门电机实际开度";
CM_ SG_ 821 TDU_CircHybThrMotTrgtPerc "内外循环风门电机目标开度";
CM_ SG_ 821 TDU_LeBlowFaceAirOutlT "左吹面出风口温度";
CM_ SG_ 821 TDU_LeBlowFootAirOutlT "左吹脚出风口温度";
CM_ SG_ 821 TDU_LeModHybThrMotActGear_F "前左模式风门电机实际档位";
CM_ SG_ 821 TDU_LeModHybThrMotTrgtGear_F "前左模式风门电机目标档位";
CM_ SG_ 821 TDU_LeTHybThrMotActPerc_F "前左温度风门电机实际开度";
CM_ SG_ 821 TDU_LeTHybThrMotTrgtPerc_F "前左温度风门电机目标开度";
CM_ SG_ 821 TDU_RiBlowFaceAirOutlT "右吹面出风口温度";
CM_ SG_ 821 TDU_RiBlowFootAirOutlT "右吹脚出风口温度";
CM_ SG_ 821 TDU_RiTHybThrMotActPerc_F "前右温度风门电机实际开度";
CM_ SG_ 821 TDU_RiTHybThrMotTrgtPerc_F "前右温度风门电机目标开度";
CM_ SG_ 908 ACComprMngmntInfo "压缩机运行状态";
CM_ SG_ 908 AmbtTemSnsrFlrSts "环境温度传感器故障状态";
CM_ SG_ 908 AmbtTemSnsrFlrStsInvsn "环境温度传感器故障状态取反";
CM_ SG_ 908 EvapACMangmntInfo "蒸发器运行状态";
CM_ SG_ 908 HeatPumpErMngmntInfo "热泵系统故障信号";
CM_ SG_ 908 HeatPumpMd "热泵模式";
CM_ SG_ 908 PTCMngmntInfo "HVPTC运行状态";
CM_ SG_ 908 TDU_AGS1_CurrentPos "当前位置反馈
(0x1~0x63按步进1线性增长)";
CM_ SG_ 908 TDU_AGS2_CurrentPos "当前位置反馈
(0x1~0x63按步进1线性增长)";
CM_ SG_ 908 TDU_AGS_TarPos "当前位置反馈
(0x1~0x63按步进1线性增长)";
CM_ SG_ 908 TDU_BypsVlv_Sts "热泵控制bypass阀状态";
CM_ SG_ 908 TDU_ESSPTC_HVIL_St "ESSPTC连接互锁状态";
CM_ SG_ 908 TDU_ESSTC_HVIL_St "TDU转发的ESSPTC高压互锁状态";
CM_ SG_ 908 TDU_ExInnerInletTem "内冷进口温度";
CM_ SG_ 908 TDU_ExInnerOutletTem "内冷出口温度";
CM_ SG_ 908 TDU_HtngVlv_Sts "热泵控制制热阀状态";
CM_ SG_ 908 TDU_LePTCAirOutlT "左PTC出风口温度";
CM_ SG_ 908 TDU_LePTCAirOutlTrgtTemp "左PTC出风口目标温度";
CM_ SG_ 908 TDU_OtsdAirTemRaw "车外环境温度原始值";
CM_ SG_ 908 TDU_RiPTCAirOutlT "右PTC出风口温度";
CM_ SG_ 908 TDU_RiPTCAirOutlTrgtTemp "右PTC出风口目标温度";
CM_ SG_ 908 TDU_SOTXV_Sts "Cabin SO-TXV状态";
CM_ SG_ 908 TDU_TempExclusiveRearFlg "后排温区独享进入标志位";
CM_ SG_ 908 TDUEnbPTC "TDU使能ESSPTC";
CM_ SG_ 908 TDUReqMd "TDU的请求模式";
CM_ SG_ 908 TDUReqPTCPwr "TDU请求ESSPTC功率";
CM_ SG_ 829 TDU_BatPumpTrgtSpd "电池水泵目标转速";
CM_ SG_ 829 TDU_MotPumpTrgtSpd "电机水泵目标转速";
CM_ SG_ 829 TDU_PumpBActSpd "水泵Pump_B实际转速";
CM_ SG_ 829 TDU_PumpBCurrt "水泵Pump_B电流";
CM_ SG_ 829 TDU_PumpBTemp "水泵Pump_B温度";
CM_ SG_ 829 TDU_PumpBVolt "水泵Pump_B电压";
CM_ SG_ 829 TDU_PumpPActSpd "水泵Pump_P实际转速";
CM_ SG_ 829 TDU_PumpPCurrt "水泵Pump_P电流";
CM_ SG_ 829 TDU_PumpPTemp "水泵Pump_P温度";
CM_ SG_ 829 TDU_PumpPVolt "水泵Pump_P电压";
CM_ SG_ 1329 TDU_HPTSnsrP "压缩机出口高压压力温度传感器压力值";
CM_ SG_ 1329 TDU_HPTSnsrT "压缩机出口高压压力温度传感器温度值";
CM_ SG_ 1329 TDU_LPTSnsrP "低压压力温度传感器压力值";
CM_ SG_ 1329 TDU_LPTSnsrT "低压压力温度传感器温度值";
CM_ SG_ 828 TDU_AirBlowerDownFbU "鼓风机下端反馈电压值";
CM_ SG_ 828 TDU_AirBlowerRelaySpdPWM "鼓风机调速PWM";
CM_ SG_ 828 TDU_AirBlowerRelaySpdU "鼓风机调速电压";
CM_ SG_ 828 TDU_AirBlowerUpFbU "鼓风机上端反馈电压值";
CM_ SG_ 828 TDU_EvaprTemp "蒸发器温度";
CM_ SG_ 828 TDU_FEvaprTrgtTemp "前蒸发器目标温度";
CM_ SG_ 828 TDU_LeSunshineSnsrT "左阳光传感器值";
CM_ SG_ 828 TDU_RiSunshineSnsrT "右阳光传感器值";
CM_ SG_ 828 TDU_UBRVolt "UBR电压";
CM_ SG_ 828 TDU_WakeupVolt "TDU硬线唤醒电压";
CM_ SG_ 1328 TDU_BattInlT "电池包进水口温度";
CM_ SG_ 1328 TDU_BattOutlT "电池包出水口温度";
CM_ SG_ 1328 TDU_HEXInWtrT "暖风进水口温度";
CM_ SG_ 1328 TDU_MotInletWaterT "驱动电机进水口温度";
CM_ SG_ 1328 TDU_MotLoopCooltFlow "驱动电机回路冷却液流量";
CM_ SG_ 817 TDU_BattCoolgLoopSts "电池冷却回路状态";
CM_ SG_ 817 TDU_BattModSt "电池热管理模式";
CM_ SG_ 817 TDU_BattThermRunawaySts "电池热失控冷却运行状态";
CM_ SG_ 817 TDU_BattWrmLoopSts "电池加热回路状态";
CM_ SG_ 817 TDU_CabCoolLoopSts "乘员舱冷却回路状态";
CM_ SG_ 817 TDU_CabHeatLoopSts "乘员舱采暖回路状态";
CM_ SG_ 817 TDU_CabModSt "乘员舱热管理模式";
CM_ SG_ 817 TDU_FaultLevel "TDU故障等级";
CM_ SG_ 817 TDU_HeatMngtFctLim "乘员舱热管理功能限制";
CM_ SG_ 817 TDU_HeatMngtSysFlt "热管理系统故障";
CM_ SG_ 817 TDU_HeatMngtSysFltNr "热管理系统故障码";
CM_ SG_ 817 TDU_HEnerConsume "高压能耗";
CM_ SG_ 817 TDU_HVCnctHldReq "TMS请求高压保持连接";
CM_ SG_ 817 TDU_HVPwrMaxReq "高压功率总需求";
CM_ SG_ 817 TDU_HVPwrMinReq "高压功率最小需求";
CM_ SG_ 817 TDU_LEnerConsume "低压能耗";
CM_ SG_ 817 TDU_LVPwrMaxReq "低压功率总需求";
CM_ SG_ 817 TDU_LVPwrMinReq "低压功率最小需求";
CM_ SG_ 817 TDU_MotCoolgLoopSts "驱动电机冷却回路状态";
CM_ SG_ 817 TDU_MotHeatPwrAvl "TDU反馈电机加热允许功率";
CM_ SG_ 817 TDU_OperMod "TDU工作模式";
CM_ SG_ 817 TDU_PTCPwrAct "TDU实际执行PTC功率";
CM_ SG_ 817 TDU_PTCPwrAvl "TDU反馈PTC可用功率";
CM_ SG_ 817 TDU_PwrModSt "动力系统热管理模式";
CM_ SG_ 817 TDU_RefModSt "制冷剂回路模式";
CM_ SG_ 817 TDU_SafteyModSts "TDU最小系统运行状态";
CM_ SG_ 817 TDU_SilentCoolgErrWakeup "热管理静默异常唤醒";
CM_ SG_ 817 TDU_SilentCoolgSts "热管理静默工作状态";
CM_ SG_ 817 TDU_WakeupHldReq "TMS请求唤醒保持";
CM_ SG_ 1333 TDU_CoolgFanActSpd "冷却风扇实际转速";
CM_ SG_ 1333 TDU_CoolgFanOpenCmd "冷却风扇开度指令";
CM_ SG_ 1333 TDU_EXVB_ActOpenVal "EXVB电池电子膨胀阀实际开度";
CM_ SG_ 1333 TDU_EXVB_InitSts "EXVB初始化状态";
CM_ SG_ 1333 TDU_EXVB_OpenCmd "电子膨胀阀EXVB开度指令";
CM_ SG_ 1333 TDU_EXVB_Sts "EXVB运行状态";
CM_ SG_ 1333 TDU_EXVH_ActOpenVal "EXVH空调箱电子膨胀阀实际开度";
CM_ SG_ 1333 TDU_EXVH_InitSts "EXVH初始化状态";
CM_ SG_ 1333 TDU_EXVH_OpenCmd "电子膨胀阀EXVH开度指令";
CM_ SG_ 1333 TDU_EXVH_Sts "EXVH运行状态";
CM_ SG_ 1461 EAS_HwVersion "EAS硬件版本号";
CM_ SG_ 1461 EAS_SwMajorVersion "EAS主软件版本号";
CM_ SG_ 1461 EAS_SwMinorVersion "EAS次软件版本号";
CM_ SG_ 1461 PTC_R_HwVersion "PTC_R硬件版本号";
CM_ SG_ 1461 PTC_R_SwVersion "PTC_R软件版本号";
CM_ SG_ 1461 TDU_HwVersion "硬件版本号";
CM_ SG_ 1461 TDU_PartVers "TDU零部件总成号";
CM_ SG_ 1461 TDU_SupplierCode "供应商代码";
CM_ SG_ 1461 TDU_SwMajorVersion "软件主版本号";
CM_ SG_ 1461 TDU_SwMinorVersion "软件子版本号";
CM_ SG_ 1461 TDU_SwPatchVersion "软件补充版本号";
CM_ SG_ 1461 TDU_SwVersionDay "软件版本日";
CM_ SG_ 1461 TDU_SwVersionMonth "软件版本月";
CM_ SG_ 1461 TDU_SwVersionYear "软件版本年-2000";
CM_ SG_ 1461 WTC_H_HwVersion "WTC_H硬件版本号";
CM_ SG_ 1461 WTC_H_SwMajorVersion "WTC_H主软件版本号";
CM_ SG_ 1461 WTC_H_SwMinorVersion "WTC_H次软件版本号";
CM_ SG_ 818 TDU_EAS_CrtPwr "压缩机当前功率";
CM_ SG_ 818 TDU_EAS_CrtSts "压缩机当前状态";
CM_ SG_ 818 TDU_EAS_CtrlrCurrt "压缩机当前工作电流";
CM_ SG_ 818 TDU_EAS_CtrlrVolt "压缩机高压供电电压";
CM_ SG_ 818 TDU_EAS_HVIL_St "压缩机高压互锁状态";
CM_ SG_ 818 TDU_EAS_IPMTemp "压缩机IPM温度";
CM_ SG_ 818 TDU_EAS_MotCurrt "压缩机电机电流";
CM_ SG_ 818 TDU_EAS_MotSpd "压缩机电机实际转速";
CM_ SG_ 818 TDU_WTC_H_ActGear "WTC_H实际挡位";
CM_ SG_ 818 TDU_WTC_H_CrtPwr "WTC_H当前功率";
CM_ SG_ 818 TDU_WTC_H_CrtSts "WTC_H当前工作状态";
CM_ SG_ 818 TDU_WTC_H_CrtTemp "WTC_H当前工作温度";
CM_ SG_ 818 TDU_WTC_H_Currt "WTC_H当前工作电流";
CM_ SG_ 818 TDU_WTC_H_HVPwrSplySts "WTC_H高压供电电压";
CM_ SG_ 818 TDU_WTC_H_InpTemp "WTC_H进口温度";
CM_ SG_ 818 TDU_WTC_H_OutpTemp "WTC_H出口温度";
CM_ SG_ 818 TDU_WTC_H_PCBTemp "WTC_HPCB温度";
CM_ SG_ 818 TDU_WTC_H_TarOutpTemp "PTC出口目标水温";
CM_ SG_ 818 TDU_WTC_HVIL_St "WTC高压互锁状态";
CM_ SG_ 582 VDC_DrvrDoorLockSt "主驾门锁状态";
CM_ SG_ 582 VDC_DrvrDoorLockStVld "主驾门锁状态有效";
CM_ SG_ 582 VDC_DrvrDoorSt "主驾门状态";
CM_ SG_ 582 VDC_DrvrDoorStValid "主驾门状态有效位";
CM_ SG_ 582 VDC_HoodSts "前舱盖状态";
CM_ SG_ 582 VDC_PassDoorLockSt "副驾门锁状态";
CM_ SG_ 582 VDC_PassDoorSt "副驾门状态";
CM_ SG_ 582 VDC_RLDoorLockSt "左后门锁状态";
CM_ SG_ 582 VDC_RLDoorSt "左后门状态";
CM_ SG_ 582 VDC_RRDoorLockSt "右后门锁状态";
CM_ SG_ 582 VDC_RRDoorSt "右后门状态";
CM_ SG_ 582 VDC_TailgateSt "后背门状态";
CM_ SG_ 798 VDC_BCM_SeatState_Checksum "CRC16 checksum  (DataID: 0x831E)";
CM_ SG_ 798 VDC_BCM_SeatState_Counter "Rolling Counter";
CM_ SG_ 798 VDC_DriverSeatOccptSt "主驾占位状态";
CM_ SG_ 798 VDC_PassSeatOccptSt "副驾占位状态";
CM_ SG_ 798 VDC_RLSecRowSeatOccptSt "二排左占位状态";
CM_ SG_ 798 VDC_RMSecRowSeatOccptSt "二排中占位状态";
CM_ SG_ 798 VDC_RRSecRowSeatOccptSt "二排右占位状态";
CM_ SG_ 819 VDC_CDC_ACECOModReq "空调ECO模式设置";
CM_ SG_ 819 VDC_CDC_ACFourZoneSync "温区同步设置";
CM_ SG_ 819 VDC_CDC_ACMaxSet "最大制冷设置";
CM_ SG_ 819 VDC_CDC_ACParkAutoVentSet "驻车自动通风开关设置";
CM_ SG_ 819 VDC_CDC_ACSet "AC请求设置";
CM_ SG_ 819 VDC_CDC_ACSystemOnOffSet "空调系统开关设置";
CM_ SG_ 819 VDC_CDC_AutoDefogSet "自动除雾设置";
CM_ SG_ 819 VDC_CDC_AutoDrySet "空调自干燥设置";
CM_ SG_ 819 VDC_CDC_CircModSet "内外循环设置";
CM_ SG_ 819 VDC_CDC_DriverTempSet "驾驶侧温度设置";
CM_ SG_ 819 VDC_CDC_FHvacBlowLvSet "前排风量档位设置";
CM_ SG_ 819 VDC_CDC_FHvacModeSet "前空调出风模式设置";
CM_ SG_ 819 VDC_CDC_FrontDefrostSet "前除霜设置";
CM_ SG_ 819 VDC_CDC_HeatMaxSet "最大制热设置";
CM_ SG_ 819 VDC_CDC_HvacAutoModeSet "前空调Auto设置";
CM_ SG_ 819 VDC_CDC_PassengerTempSet "副驾温度设置";
CM_ SG_ 819 VDC_CDC_RACSystemOnOffSet "后空调系统开关设置";
CM_ SG_ 819 VDC_CDC_SceneModPwrOnSts "情景智能模式维持上电状态通知";
CM_ SG_ 819 VDC_CDC_SupCoolingModSet "超级冷却功能开关请求";
CM_ SG_ 819 VDC_CDC_TempExclusive "温区独享设置";
CM_ SG_ 819 VDC_CDC_VentSet "通风设置信号";
CM_ SG_ 289 VDC_CoordiRespondSt "VDC工况协调响应状态";
CM_ SG_ 289 VDC_DrvgCyc "驾驶循环";
CM_ SG_ 289 VDC_EMSCtrl_Checksum "CRC16 checksum  (DataID: 0x8121)";
CM_ SG_ 289 VDC_EMSCtrl_Counter "Rolling Counter";
CM_ SG_ 289 VDC_EngCrankReq "发电机倒拖启动指令";
CM_ SG_ 289 VDC_EngCtrlSt "增程系统控制状态";
CM_ SG_ 289 VDC_EngMaxSpdLim "发动机最大转速限制";
CM_ SG_ 289 VDC_EngRampEna "发动机扭矩快降使能";
CM_ SG_ 289 VDC_EngReadySt "增程系统就绪状态";
CM_ SG_ 289 VDC_EngStartMod "发动机启动模式";
CM_ SG_ 289 VDC_EngStartReq "发动机启动请求";
CM_ SG_ 289 VDC_EngStopReq "发动机停机请求";
CM_ SG_ 289 VDC_EngStrtFuInjInhb "发动机启动喷油抑制指令";
CM_ SG_ 289 VDC_EngTqResv "飞轮段负载要求发动机建立的储备扭矩";
CM_ SG_ 289 VDC_FlyWhFastTqReq "发动机快扭目标请求值";
CM_ SG_ 289 VDC_FlyWhFastTqReqVld "发动机快扭目标请求值有效位";
CM_ SG_ 289 VDC_FlyWhSlowTqReq "发动机慢扭目标请求值";
CM_ SG_ 289 VDC_FlyWhSlowTqReqVld "发动机慢扭目标请求值有效位";
CM_ SG_ 289 VDC_FuelChargeStatus "燃油补电模式档位";
CM_ SG_ 289 VDC_FuelChargeSwitch "燃油补电模式状态";
CM_ SG_ 289 VDC_FuelCutOffReq "减速断油指令";
CM_ SG_ 289 VDC_FueldetectionStatus "燃油检测模式档位";
CM_ SG_ 289 VDC_FueldetectionSwitch "燃油检测模式状态";
CM_ SG_ 289 VDC_FuelRemaining "剩余油量";
CM_ SG_ 289 VDC_FuelRemainingVld "剩余油量有效位";
CM_ SG_ 289 VDC_FuelRemainingVol "剩余油量真实体积";
CM_ SG_ 289 VDC_GenStableTqAdpSt "发动机工况稳定状态,可进行扭矩自学习";
CM_ SG_ 289 VDC_IdleChrgActvReq "发动机怠速充电激活标志";
CM_ SG_ 289 VDC_IdleChrgFlyWhlLoadTq "发动机飞轮端怠速充电负载扭矩";
CM_ SG_ 289 VDC_IdleChrgFlyWhlLoadTqVld "发动机飞轮端怠速充电负载扭矩有效位";
CM_ SG_ 289 VDC_IdleChrgSpdReq "发动机怠速充电目标转速";
CM_ SG_ 289 VDC_IdleChrgSpdReqVld "发动机怠速充电目标转速有效位";
CM_ SG_ 289 VDC_IdleCtrlReq "发动机怠速控制请求";
CM_ SG_ 289 VDC_IdleLoadTq "怠速负载扭矩";
CM_ SG_ 289 VDC_IdleLoadTqVld "怠速负载扭矩有效位";
CM_ SG_ 289 VDC_IgAglRlsActvSts "点火角释放请求";
CM_ SG_ 289 VDC_IgnCyc "点火循环";
CM_ SG_ 289 VDC_MILReq "VDC点MIL灯请求";
CM_ SG_ 289 VDC_OBDFaultExistSts "当前驾驶循环VDC监测OBD实时故障标志位";
CM_ SG_ 289 VDC_REVMod "增程模式";
CM_ SG_ 289 VDC_TarIdleSpdReq "发动机目标怠速请求";
CM_ SG_ 289 VDC_TarIdleSpdReqVld "发动机目标怠速有效位";
CM_ SG_ 289 VDC_WarmupCyc "暖机循环";
CM_ SG_ 1408 VDC_ChrgPostCurrent "充电桩额定电流";
CM_ SG_ 1408 VDC_ChrgPostPwr "充电桩额定功率";
CM_ SG_ 1408 VDC_CLTCRang "CLTC总续航里程";
CM_ SG_ 1408 VDC_EngyAfAvgLastChrg "自上次充电平均电耗";
CM_ SG_ 1408 VDC_EngyAfLastChrg "上次充电后的能耗";
CM_ SG_ 1408 VDC_EngyAvgRstA "小计里程A重置后平均能耗";
CM_ SG_ 1408 VDC_EngyAvgRstB "小计里程B重置后平均能耗";
CM_ SG_ 1408 VDC_EngyDrvAvePerKm "当前驾驶循环所行驶的里程的平均能耗";
CM_ SG_ 1408 VDC_EngyRegenPerKm "当前驾驶循环每公里再生制动回收能源";
CM_ SG_ 1408 VDC_EngyRstA "小计里程A重置后的能耗";
CM_ SG_ 1408 VDC_EngyRstB "小计里程B重置后的能耗";
CM_ SG_ 1408 VDC_EngytotalCurCyc "当前驾驶循环在行驶中的总能耗";
CM_ SG_ 1408 VDC_EngyTotalRegen "当前驾驶循环再生制动回收的总能量";
CM_ SG_ 1408 VDC_EstimdArrivalDst "预估到达充电桩剩余里程";
CM_ SG_ 1408 VDC_EstimdArrivalSOC "预估到达充电桩SOC";
CM_ SG_ 1408 VDC_EstimdArrivalTi "预估到达充电桩时间";
CM_ SG_ 1408 VDC_HeatEngy "当前驾驶循环累计加热能量";
CM_ SG_ 1408 VDC_RangAfLastChrg "自上次充电里程";
CM_ SG_ 1408 VDC_RangChrgSet "目标充电续驶里程设置值";
CM_ SG_ 1408 VDC_RangeRstSetSt "里程重置设置信号(每一个bit,0表示不重置,1表示重置)";
CM_ SG_ 1408 VDC_RangRstA "小计里程A重置后的里程";
CM_ SG_ 1408 VDC_RangRstB "小计里程B重置后的里程";
CM_ SG_ 1408 VDC_RatRegen "当前驾驶循环再生制动回收能源与总消耗的能量比值";
CM_ SG_ 1408 VDC_RMotPwr "后电机瞬时功率";
CM_ SG_ 848 VDC_GCUPowergenerationstatus "GCU发电状态";
CM_ SG_ 1302 VDC_FaultNum1 "故障编号1";
CM_ SG_ 1302 VDC_FaultNum10 "故障编号10";
CM_ SG_ 1302 VDC_FaultNum11 "故障编号11";
CM_ SG_ 1302 VDC_FaultNum12 "故障编号12";
CM_ SG_ 1302 VDC_FaultNum13 "故障编号13";
CM_ SG_ 1302 VDC_FaultNum14 "故障编号14";
CM_ SG_ 1302 VDC_FaultNum15 "故障编号15";
CM_ SG_ 1302 VDC_FaultNum16 "故障编号16";
CM_ SG_ 1302 VDC_FaultNum17 "故障编号17";
CM_ SG_ 1302 VDC_FaultNum18 "故障编号18";
CM_ SG_ 1302 VDC_FaultNum19 "故障编号19";
CM_ SG_ 1302 VDC_FaultNum2 "故障编号2";
CM_ SG_ 1302 VDC_FaultNum20 "故障编号20";
CM_ SG_ 1302 VDC_FaultNum3 "故障编号3";
CM_ SG_ 1302 VDC_FaultNum4 "故障编号4";
CM_ SG_ 1302 VDC_FaultNum5 "故障编号5";
CM_ SG_ 1302 VDC_FaultNum6 "故障编号6";
CM_ SG_ 1302 VDC_FaultNum7 "故障编号7";
CM_ SG_ 1302 VDC_FaultNum8 "故障编号8";
CM_ SG_ 1302 VDC_FaultNum9 "故障编号9";
CM_ SG_ 1302 VDC_FrameIndex "帧序号";
CM_ SG_ 1302 VDC_SupplierNum "供应商代码";
CM_ SG_ 1302 VDC_TotalFaultNum "当前故障总数";
CM_ SG_ 384 VDC_GCUCtrl_Checksum "CRC16 checksum (DataID: 0x8180)";
CM_ SG_ 384 VDC_GCUCtrl_Counter "Rolling Counter";
CM_ SG_ 384 VDC_GMotActvDampReq "发电机主动阻尼功能请求";
CM_ SG_ 384 VDC_GMotEna "发电机控制器使能指令";
CM_ SG_ 384 VDC_GMotModReq "发电机工作模式请求";
CM_ SG_ 384 VDC_GMotSpdReq "发电机转速请求";
CM_ SG_ 384 VDC_GMotTqReq "发电机扭矩请求";
CM_ SG_ 384 VDC_GMotVoltReq "发电机目标电压请求";
CM_ SG_ 384 VDC_MaxEleTqLim "最大允许电动转矩限制";
CM_ SG_ 384 VDC_MaxGenTqLim "最大允许发电转矩限制";
CM_ SG_ 385 VDC_ACChrgAllwdSts "VDC允许交流充电状态";
CM_ SG_ 385 VDC_BMSDchaMaxPwr "VDC允许放电功率";
CM_ SG_ 385 VDC_BMSHVConsumePower "高压附件消耗功率";
CM_ SG_ 385 VDC_ChrgAlld "VDC允许充电";
CM_ SG_ 385 VDC_ChrgPilePowerSupplyAllow "VDC允许桩端供电";
CM_ SG_ 385 VDC_ChrgPortLockSt "充电电子锁状态";
CM_ SG_ 385 VDC_ChrgStopType "充电停止形式";
CM_ SG_ 385 VDC_ChrgTrgtSOC "充电目标SOC";
CM_ SG_ 385 VDC_DCBoostChrgAllwdSts "VDC允许升压直流充电状态";
CM_ SG_ 385 VDC_DCChrgAllwd "直流充电允许";
CM_ SG_ 385 VDC_DCDCEnableCmd "DCDC工作使能指令";
CM_ SG_ 385 VDC_DCDCMaxCurrtAlld "DCDC最大许用输出电流(低压侧)";
CM_ SG_ 385 VDC_DCDCMaxPwrAlld "DCDC最大允许输入功率(高压侧)(预留)";
CM_ SG_ 385 VDC_DCDCSetVolt "DCDC输出目标电压(低压侧)";
CM_ SG_ 385 VDC_DchaAllwdSts "VDC允许放电状态";
CM_ SG_ 385 VDC_DchaStopType "整车禁止放电原因";
CM_ SG_ 385 VDC_ExtrLoTMod "极低温启动模式状态反馈";
CM_ SG_ 385 VDC_HeatMod "VDC加热模式";
CM_ SG_ 385 VDC_HVBattHVONCmd "动力电池上高压指令";
CM_ SG_ 385 VDC_HVCtrl_Checksum "CRC16 checksum  (DataID: 0x8181)";
CM_ SG_ 385 VDC_HVCtrl_Counter "Rolling Counter";
CM_ SG_ 385 VDC_NavChrgThermReq "使能BMS开启导航充电场景热管理";
CM_ SG_ 385 VDC_OBCACCurrtMaxPerm "OBC交流侧电流限值";
CM_ SG_ 385 VDC_PTCPwrReq "VDC计算的PTC功率";
CM_ SG_ 385 VDC_TDUHVPwrLimMax "TDU高压功率限值MAX";
CM_ SG_ 385 VDC_TDUModReq "TDU工作模式请求";
CM_ SG_ 385 VDC_VehDCChrgCurrtLimit "整车直流充电电流限制值";
CM_ SG_ 283 VDC_AccPedalAcPositionValid "加速踏板实际位置有效位";
CM_ SG_ 283 VDC_AccPedalActualPosition "加速踏板实际位置(如果在巡航状态下踩下踏板,该信号是实际踏板位置)";
CM_ SG_ 283 VDC_AccPedalPosition "加速踏板位置(巡航状态为虚拟踏板,如果巡航功能不开,驾驶员踩油门踏板的话两个信号是一致的)";
CM_ SG_ 283 VDC_AccPedalPositionValid "加速踏板位置有效位";
CM_ SG_ 283 VDC_ActualGear "真实挡位";
CM_ SG_ 283 VDC_ActualGearValid "真实挡位有效位";
CM_ SG_ 283 VDC_AdsLowPowCmd "ADAS低功耗命令";
CM_ SG_ 283 VDC_BMS_SOC "大电池SOC(预留信号)";
CM_ SG_ 283 VDC_BrakePedalFeelSet "IBS踏板感设置";
CM_ SG_ 283 VDC_brakePedalSts "Indicating brake pedal activated by driver or not
制动踏板状态";
CM_ SG_ 283 VDC_brakePedalStsValid "Indicating the valid bit for brake pedal status
制动踏板状态有效位";
CM_ SG_ 283 VDC_CDC_OnHighwaySt "车辆处于高速公路状态";
CM_ SG_ 283 VDC_CDCremindReq "CDC 提示请求";
CM_ SG_ 283 VDC_CompositeRang "综合总续航里程";
CM_ SG_ 283 VDC_driveReady "驾驶员Ready指示";
CM_ SG_ 283 VDC_DrvMod "车辆驾驶模式";
CM_ SG_ 283 VDC_DrvrAccrPedlOvrd "驾驶员加速踏板干预状态
当驾驶员踩油门驱动扭矩大于ADS请求驱动扭矩,置为1";
CM_ SG_ 283 VDC_DrvrGearOvrd "驾驶员干预档位状态";
CM_ SG_ 283 VDC_ECASFuncLimit "空气弹簧功能限制";
CM_ SG_ 283 VDC_ECASHeightAdjust "空气弹簧高度调节";
CM_ SG_ 283 VDC_ECASMaintenanceMode "空气弹簧手动维修模式请求";
CM_ SG_ 283 VDC_EDCModeSet "EDC Mode Set
EDC模式设置";
CM_ SG_ 283 VDC_epbRequest "驻车请求";
CM_ SG_ 283 VDC_epbRequestValid "驻车请求有效位";
CM_ SG_ 283 VDC_EPSModeRequest "EPS Mode Request
EPS模式请求";
CM_ SG_ 283 VDC_ESCdriveReady "Drive ready indicator To ESC";
CM_ SG_ 283 VDC_ESCModeSet "ESC模式设置";
CM_ SG_ 283 VDC_GearShiftAvl "挡位切换可用状态";
CM_ SG_ 283 VDC_HV_State "高压上电状态";
CM_ SG_ 283 VDC_LVEM_LoEgyCnsModReq "低功耗模式请求";
CM_ SG_ 283 VDC_OnePedalstatus "单踏板模式开启状态(底盘专用)";
CM_ SG_ 283 VDC_PTSt_Checksum "CRC16 checksum(DataID: 0x611B)";
CM_ SG_ 283 VDC_PTSt_RollingCounter "Rolling Counter";
CM_ SG_ 283 VDC_PtTqAvl "动力系统扭矩可用状态";
CM_ SG_ 283 VDC_RegenModeStatus "能量回收状态
Energy recovery on off status";
CM_ SG_ 283 VDC_targetGear "Target gear
目标挡位";
CM_ SG_ 283 VDC_targetGearValid "Target gear valid signal
目标挡位有效位";
CM_ SG_ 283 VDC_TotalRang "整个寿命内的车辆总行驶里程";
CM_ SG_ 283 VDC_TraveMode "道路模式";
CM_ SG_ 283 VDC_VehicleStopTime "整车停车时间(当车辆起步时,如果车辆停止时间大于5min,则发出该信号;前期车型为IC发送)";
CM_ SG_ 283 VDC_VehicleStopTimeValid "整车停车时间有效位";
CM_ SG_ 283 VDC_VehSpd "车速";
CM_ SG_ 283 VDC_VehSpdDir "车速方向";
CM_ SG_ 283 VDC_VehSpdVld "车速有效位";
CM_ SG_ 258 VDC_RMcuWakUpReq "后MCU唤醒/休眠指令(VIU硬线唤醒预留信号)";
CM_ SG_ 258 VDC_RMotActiveDampReq "后电机主动阻尼功能请求";
CM_ SG_ 258 VDC_RMotActiveDATSReq "后驱动电机DATS功能请求";
CM_ SG_ 258 VDC_RMotActvDampLvlReq "后电机主动阻尼档位(三电机默认左后)";
CM_ SG_ 258 VDC_RMotCtrl_Checksum "CRC16 checksum  (DataID: 0x8102)";
CM_ SG_ 258 VDC_RMotCtrl_Counter "Rolling Counter";
CM_ SG_ 258 VDC_RMotEnable "后电机控制器使能指令";
CM_ SG_ 258 VDC_RMotMaxDrvTqLimt "最大允许驱动扭矩限制";
CM_ SG_ 258 VDC_RMotMaxRegenTqLimt "最大允许回收扭矩限制";
CM_ SG_ 258 VDC_RMotModReq "后电机工作模式请求";
CM_ SG_ 258 VDC_RMotSpdLimMax "电机最大转速限值";
CM_ SG_ 258 VDC_RMotSpdRate "转速变化率参考";
CM_ SG_ 258 VDC_RMotSpdReq "后电机转速请求";
CM_ SG_ 258 VDC_RMotStopDst "剩余距离";
CM_ SG_ 258 VDC_RMotSVReplan "SV重规划标志";
CM_ SG_ 258 VDC_RMotTqRateLimMax "电机端扭矩变化率上限";
CM_ SG_ 258 VDC_RMotTqRateLimMin "电机端扭矩变化率下限";
CM_ SG_ 258 VDC_RMotTqReq "后电机扭矩请求";
CM_ SG_ 258 VDC_RMotTqUnloadEna "请求卸扭使能";
CM_ SG_ 258 VDC_RMotTqUnloadRate "电机端卸扭斜率";
CM_ SG_ 258 VDC_RMotTrackingMod "跟踪模式标志";
CM_ SG_ 275 VDC_CoastRegenRequest_RA "Currently requested Coast Recuperation from Generator
后电机当前滑行目标扭矩,轮端扭矩
(三电机配置时默认为左后电机)";
CM_ SG_ 275 VDC_CoastRegenRequest_RAValid "Status of Currently requested Coast Recuperation from Generator
后电机当前滑行目标扭矩有效位
(三电机配置时默认为左后电机)";
CM_ SG_ 275 VDC_DriverTorqueDesired "驾驶员需求驱动力矩(驾驶员油门对应的驱动力矩)
结合加速踏板开度,车速,电系统能力等因素进行计算,经驾驶性处理后的整车轮端扭矩需求";
CM_ SG_ 275 VDC_MotorRegenTorqueInD_VV01 "motor actual regen torque in D gearAlways positive or 0Only valid in D gear when rear motor generates regen torqueOtherwise this value will be 0Nm
整车实际制动能量回收扭矩,轮端扭矩(减去滑行后扭矩)";
CM_ SG_ 275 VDC_MotorRegenTorqueInDValid "VDC_MotorRegenTorqueInDValid
整车实际制动能量回收扭矩有效位";
CM_ SG_ 275 VDC_MotorRegenTorqueLmtInD_VV01 "motor minimum torque limitIt stands for the maximum torque that the front motor can generate towards the rear end of the carPositive value means the torque points to the front end of the carNegative value means the torque points to the rear end of the car
整车最大允许制动能量回收扭矩,轮端扭矩";
CM_ SG_ 275 VDC_MotorRegenTrqLmtInDValid "VDC_MotorRegenTrqLmtInDValid
整车最大允许制动能量回收扭矩有效位";
CM_ SG_ 275 VDC_OPDHydBrkCompenRqSts "液压制动补偿请求状态";
CM_ SG_ 275 VDC_OPDHydBrkCompenRqTq "液压制动补偿力矩";
CM_ SG_ 275 VDC_OPDHydBrkCompenRqTqValid "液压制动补偿力矩有效位";
CM_ SG_ 275 VDC_PtTqActvSts "VDC扭矩响应状态";
CM_ SG_ 275 VDC_rearMotorRegenTorqueInD "Rear motor actual regen torque in D gearAlways positive or 0Only valid in D gear when rear motor generates regen torqueOtherwise this value will be 0Nm
后电机实际能量回收扭矩,轮端扭矩";
CM_ SG_ 275 VDC_rearMotorRegenTorqueInDValid "VDC_rearMotorRegenTorqueInDValid
后电机实际能量回收扭矩有效位";
CM_ SG_ 275 VDC_rearMotorRegenTorqueLmtInD "Rear motor minimum torque limitIt stands for the maximum torque that the rear motor can generate towards the rear end of the carPositive value means the torque points to the front end of the carNegative value means the torque points to the rear end of the car
后电机最大制动能量回收扭矩,轮端扭矩";
CM_ SG_ 275 VDC_rearMotorRegenTrqLmtInDValid "VDC_rearMotorRegenTrqLmtInDValid
后电机最大制动能量回收扭矩有效位";
CM_ SG_ 275 VDC_rearMotorRpm "Rear motor actual motor speed in RPMPositive value means the motor speed points to the front end of the carNegative value means the motor speed points to the rear end of the car
后电机转速
(三电机配置时默认为左后电机)";
CM_ SG_ 275 VDC_rearMotorRpmValid "VDC_rearMotorRpmValid
后电机转速有效位
(三电机配置时默认为左后电机)";
CM_ SG_ 275 VDC_rearMotorTorquePed_VV01 "Rear motor actual generated torqueIn D gear, positive value means the torque points to the front end of the car; negative value means the torque points to the rear end of the car. In R gear, positive value means the torque points to the rear end of the car; negative value means the torque points to the front end of the car 
后电机实际扭矩(正值代表驱动,负值代表回馈),轮端扭矩
(三电机配置时默认为左后电机)";
CM_ SG_ 275 VDC_rearMotorTorquePedValid "VDC_rearMotorTorquePedValid
后电机实际扭矩有效位
(三电机配置时默认为左后电机)";
CM_ SG_ 275 VDC_rearMotorTorqueReqPed_VV01 "Rear motor torque request from VDCIn D gear, positive value means the torque points to the front end of the car; negative value means the torque points to the rear end of the car. In R gear, positive value means the torque points to the rear end of the car; negative value means the torque points to the front end of the car 
后电机需求扭矩(正值代表驱动,负值代表回馈),轮端扭矩
(三电机配置时默认为左后电机)";
CM_ SG_ 275 VDC_rearMotorTqReqPedValid "VDC_rearMotorTorqueReqPedValid
后电机需求扭矩有效位
(三电机配置时默认为左后电机)";
CM_ SG_ 275 VDC_RMtTq_Checksum "CRC16 checksum(DataID: 0x6113)";
CM_ SG_ 275 VDC_RMtTq_RollingCounter "Rolling Counter";
CM_ SG_ 275 VDC_vehicleTorqueMax "整车最大扭矩,轮端扭矩(驱动最大扭矩)";
CM_ SG_ 275 VDC_vehicleTorqueMaxValid "整车最大扭矩有效,轮端扭矩";
CM_ SG_ 275 VDC_vehicleTorqueMin_VV01 "整车最小回收扭矩,轮端扭矩(回馈最小扭矩)";
CM_ SG_ 275 VDC_vehicleTorqueMinValid "整车最小扭矩有效,轮端扭矩";
CM_ SG_ 275 VDC_VehWhlActTq "整车实际轮端扭矩";
CM_ SG_ 275 VDC_VehWhlActTqVld "整车实际轮端扭矩有效";
CM_ SG_ 275 VDC_VehWhlReqTq "整车需求轮端扭矩";
CM_ SG_ 275 VDC_VehWhlReqTqVld "整车需求轮端扭矩有效";
CM_ SG_ 388 VDC_AccPedalPos "油门踏板开度";
CM_ SG_ 388 VDC_AccrPedlUFirst "加速踏板1路电压值";
CM_ SG_ 388 VDC_AccrPedlUFirst_Input "加速踏板1路传感器输入电压";
CM_ SG_ 388 VDC_AccrPedlUSecond "加速踏板2路电压值";
CM_ SG_ 388 VDC_AccrPedlUSecond_Input "加速踏板2路传感器输入电压";
CM_ SG_ 388 VDC_ActGearSt "实际挡位";
CM_ SG_ 388 VDC_BrkPedalPressed "制动踏板状态";
CM_ SG_ 388 VDC_BrkPedalPressedValid "制动踏板状态有效";
CM_ SG_ 388 VDC_KeyOnSt "KeyOn信号(预留)";
CM_ SG_ 388 VDC_PowerMode "整车电源模式(预留)";
CM_ SG_ 388 VDC_PTReadySt "Ready信号";
CM_ SG_ 388 VDC_RoadSlop "道路坡度";
CM_ SG_ 388 VDC_RoadSlopRate "道路坡度坡度变化率";
CM_ SG_ 388 VDC_SysState_Checksum "CRC16 checksum  (DataID: 0x8184)";
CM_ SG_ 388 VDC_SysState_Counter "Rolling Counter";
CM_ SG_ 388 VDC_TargetGearSt "目标档位";
CM_ SG_ 388 VDC_VehPowerSt "整车低压电源状态信号(预留)";
CM_ SG_ 785 VDC_AccMod "车辆加速模式";
CM_ SG_ 785 VDC_CDC_ACChrgCurrtSet "大屏设置交流充电电流";
CM_ SG_ 785 VDC_ChrgFaultSt "停充故障";
CM_ SG_ 785 VDC_ChrgLockSts "充电枪锁状态";
CM_ SG_ 785 VDC_CoastRegnSt "滑行制动回馈状态";
CM_ SG_ 785 VDC_CoolSysOTSt "冷却系统过温指示灯";
CM_ SG_ 785 VDC_CooltLvlStatus "冷却液位状态";
CM_ SG_ 785 VDC_CreepModSt "爬行功能开启状态";
CM_ SG_ 785 VDC_DCScheduleChrgAlld "直流预约充电允许";
CM_ SG_ 785 VDC_EstimdSlop "坡度估计值(上坡为正,下坡为负)";
CM_ SG_ 785 VDC_EstimdSlopVld "坡度估计值有效位";
CM_ SG_ 785 VDC_FactoryReset "恢复空调设置项为出厂";
CM_ SG_ 785 VDC_GearFailedWarnInfo "换挡失败提醒信息";
CM_ SG_ 785 VDC_HVAllowSts "允许上高压状态(维修模式)";
CM_ SG_ 785 VDC_HVBattFaultSt "动力电池故障状态";
CM_ SG_ 785 VDC_LowSOCSt "SOC低报警信号";
CM_ SG_ 785 VDC_LowSocWarn "低电量报警提示";
CM_ SG_ 785 VDC_LVBattChrgFault "无法低压补电故障原因";
CM_ SG_ 785 VDC_LVBattChrgReqSt "智能补电模式请求状态";
CM_ SG_ 785 VDC_LVBattChrgSt "12V蓄电池补电状态";
CM_ SG_ 785 VDC_LVBattFaultSt "低压供电系统故障状态";
CM_ SG_ 785 VDC_MCUPwrAct "MCU实际执行功率";
CM_ SG_ 785 VDC_MCUPwrReq "VDC请求MCU功率";
CM_ SG_ 785 VDC_MotFaultSt "电机系统故障状态";
CM_ SG_ 785 VDC_NavTunnelSt "导航隧道状态";
CM_ SG_ 785 VDC_OnePedlModSt "单踏板模式开启状态";
CM_ SG_ 785 VDC_PwrLimitSt "功率限制灯信号(乌龟灯,故障或电量不足时点亮)";
CM_ SG_ 785 VDC_RemThermReq "VDC使能BMS开始备车热管理指令";
CM_ SG_ 785 VDC_RemThermTiCalcdReq "VDC请求BMS计算备车热管理所需时间";
CM_ SG_ 785 VDC_RepairModeSts "维修模式状态反馈";
CM_ SG_ 785 VDC_ScheduleChrgCtrlSts "直流预约充电控制命令";
CM_ SG_ 785 VDC_ScheduleChrgStartStopCmd "预约充电指令";
CM_ SG_ 785 VDC_ShiftGearWarnSt "驾驶员换挡操作异常提示标志位,每个bit表示一个标志";
CM_ SG_ 785 VDC_SpdLimWarn "超速警示标志";
CM_ SG_ 785 VDC_SysFaultText "系统故障文字提示";
CM_ SG_ 785 VDC_TempExclusivePassFlg "副驾温区独享进入标志位";
CM_ SG_ 785 VDC_TempExclusiveRearFlg "后排温区独享进入标志位";
CM_ SG_ 785 VDC_TempExclusiveRearRiFlg "后排右温区独享进入标志位";
CM_ SG_ 785 VDC_TimeChargeSwtichSts "车辆预约充电开启状态";
CM_ SG_ 785 VDC_TVModSt "TV模式开启状态";
CM_ SG_ 785 VDC_Usagemode "整车用户模式(预留)";
CM_ SG_ 785 VDC_VehFaultLevel "整车故障等级";
CM_ SG_ 785 VDC_VehModSt "整车模式状态(依赖平台定义)";
CM_ SG_ 785 VDC_VehState_Checksum "CRC16 checksum  (DataID: 0x8311)";
CM_ SG_ 785 VDC_VehState_Counter "Rolling Counter";
CM_ SG_ 785 VDC_VehSysWarnSt "整车系统警示信号";
CM_ SG_ 785 VDC_WeakRegnRemind "能量回收制动力减弱信号提示";
CM_ SG_ 788 VDC_EnaCmd_EAS "EAS使能指令";
CM_ SG_ 788 VDC_EngCrankReason "倒拖原因";
CM_ SG_ 788 VDC_EngIdleReason "怠速原因";
CM_ SG_ 788 VDC_EngNotReadyReason "发动机未Ready原因";
CM_ SG_ 788 VDC_EngStartForbidReason "禁止启动原因";
CM_ SG_ 788 VDC_EngStartReason "启动运行原因";
CM_ SG_ 788 VDC_EngStartSOCCurrtMod "当前增程模式启动SOC";
CM_ SG_ 788 VDC_EngStopReason "停机原因";
CM_ SG_ 788 VDC_EngStopSOCCurrtMod "当前增程模式停机SOC";
CM_ SG_ 788 VDC_FuelAddingAlldSt "VDC允许加油标志位(维测)";
CM_ SG_ 788 VDC_ReevVHRSignal1 "VDC增程控制VHR信号1";
CM_ SG_ 788 VDC_ReevVHRSignal2 "VDC增程控制VHR信号2";
CM_ SG_ 788 VDC_ReevVHRSignal3 "VDC增程控制VHR信号3";
CM_ SG_ 788 VDC_ReevVHRSignal4 "VDC增程控制VHR信号4";
CM_ SG_ 788 VDC_ReevVHRSignal5 "VDC增程控制VHR信号5";
CM_ SG_ 788 VDC_TarSpdCmd_EAS "压缩机目标转速指令";
CM_ SG_ 788 VDC_TotalRang_1 "整个生命内的车辆总行驶里程(精度0.1)";
CM_ SG_ 1456 VDC_HwVersion "硬件版本号";
CM_ SG_ 1456 VDC_SupplierCode "供应商代码";
CM_ SG_ 1456 VDC_SwMajorVersion "软件主版本号";
CM_ SG_ 1456 VDC_SwMinorVersion "软件子版本号";
CM_ SG_ 1456 VDC_SwPatchVersion "软件补充版本号";
CM_ SG_ 1456 VDC_SwVersionDay "软件版本日";
CM_ SG_ 1456 VDC_SwVersionMonth "软件版本月";
CM_ SG_ 1456 VDC_SwVersionYear "软件版本年-2000";
CM_ SG_ 857 VIU_AmbT "环境温度";
CM_ SG_ 857 VIU_AmbTVld "环境温度有效";
CM_ SG_ 857 VIU_API2CAN_EMS_GCU_Checksum "CRC16 checksum  (DataID: 0x4359)";
CM_ SG_ 857 VIU_API2CAN_EMS_GCU_Counter "Rolling Counter";
CM_ SG_ 857 VIU_FuelSigFlt "油位信号输入电路故障";
CM_ SG_ 857 VIU_HVFuelRleaseRequest "高压油箱泄压请求";
CM_ SG_ 857 VIU_OilSnsrResistorVal "油位传感器电阻值";
CM_ SG_ 688 VIU_DoorLock_Chks "CRC16 checksum(DataID: 0x42B0)";
CM_ SG_ 688 VIU_DoorLock_Cntr "Rolling Counter";
CM_ SG_ 688 VIU_FuCapSt "加油口盖状态";
CM_ SG_ 467 VIU_CarMode "车辆模式";
CM_ SG_ 467 VIU_Info_Checksum_VV01 "CRC16 Checksum(Data ID:0x81D3)";
CM_ SG_ 467 VIU_Info_Counter "RollingCounter";
CM_ SG_ 467 VIU_PowerMode "电源模式";
CM_ SG_ 467 VIU_PowerModeFltFlag "电源模式故障状态";
CM_ SG_ 467 VIU_UsageMode "用户模式";
CM_ SG_ 467 VIU_VehAntithftSt "车辆防盗状态";
CM_ SG_ 856 RSM_AirT "玻璃附近空气温度";
CM_ SG_ 856 RSM_DewPointT "露点温度";
CM_ SG_ 856 RSM_HumTFlt "温湿度传感器故障";
CM_ SG_ 856 RSM_LeSolarInten "左太阳光强度";
CM_ SG_ 856 RSM_LiSnsrErr "光线传感器故障";
CM_ SG_ 856 RSM_Rainfall "雨量大小";
CM_ SG_ 856 RSM_RainSnsrErr "雨量传感器故障";
CM_ SG_ 856 RSM_RelHum "相对湿度";
CM_ SG_ 856 RSM_RiSolarInten "右太阳光强度";
CM_ SG_ 856 RSM_WinT "玻璃温度";
CM_ SG_ 856 VIU_Reserved "预留";
CM_ SG_ 856 VIU_Route_EP_Checksum "CRC16 checksum  (DataID: 0x8358)";
CM_ SG_ 856 VIU_Route_EP_Counter "Rolling Counter";
CM_ SG_ 463 ADS_MotSpdCtrlEna "转速模式控制使能";
CM_ SG_ 463 CS_FWiperMistReq "前雨刮点刮请求";
CM_ SG_ 463 CS_FWiperSwtReq "前雨刮刮刷请求";
CM_ SG_ 463 CS_FWiperWashReq "前雨刮洗涤刮刷请求";
CM_ SG_ 463 EPS_SteerWheelAngle "小齿轮转角(左正右负)TAS";
CM_ SG_ 463 EPS_SteerWheelAngleValid "小齿轮转角有效位TAS";
CM_ SG_ 463 IBS_AVHAvailable "HMI Responsible,CAN get degrateAVH statement from DSW and send out
AVH是否可用";
CM_ SG_ 463 IBS_AVHStatus "indicates AVH in active or not
AVH状态";
CM_ SG_ 463 IBS_ESCOFF_Status "电子(车身)稳定控制系统关闭";
CM_ SG_ 463 VIU_Route_EP_2_Checksum "CRC16 checksum  (DataID: 0x81CF)";
CM_ SG_ 463 VIU_Route_EP_2_Counter "Rolling Counter";
CM_ SG_ 796 IBS_OBDFaultExistSts "OBD故障标志位";
CM_ SG_ 796 IPB_OBD_MILOnReq "MIL灯点亮请求";
CM_ SG_ 796 VIU_Route_EMS_GCU_1_Checksum "CRC16 checksum  (DataID: 0x831C)";
CM_ SG_ 796 VIU_Route_EMS_GCU_1_Counter "Rolling Counter";

// Attribute definitions
BA_DEF_ BO_ "CANFD_BRS" ENUM "1","0"; //
BA_DEF_ BO_ "DiagRequest" ENUM "Yes","No"; //
BA_DEF_ BO_ "DiagResponse" ENUM "Yes","No"; //
BA_DEF_ BO_ "DiagState" ENUM "Yes","No"; //
BA_DEF_ BO_ "GenMsgSendType" ENUM "Cycle","Event","CE"; //
BA_DEF_ SG_ "GenSigSendType" ENUM "Cycle","OnWrite","OnWriteWithRepetition","OnChange","OnChangeWithRepetition"; //
BA_DEF_ BO_ "MSG IL Support" ENUM "Yes","No"; //
BA_DEF_ BO_ "NmMessage" ENUM "Yes","No"; //
BA_DEF_ BO_ "VFrameFormat" ENUM "StandardCAN","ExtendedCAN","reserved","J1939PG","reserved","reserved","reserved","reserved","reserved","reserved","reserved","reserved","reserved","reserved","StandardCAN_FD","ExtendedCAN_FD";
BA_DEF_ BO_ "GenMsgCycleTime" FLOAT 0 300000; // [ms]
BA_DEF_ BO_ "GenMsgStartDelayTime" FLOAT 0 300000; // [ms]
BA_DEF_ BO_ "GenMsgDelayTime" FLOAT 0 300000; // [ms]
BA_DEF_ SG_ "GenSigStartValue" FLOAT -1.7976931348623157E308 18446744073709551615;
BA_DEF_ BO_ "GenMsgNrOfRepetition" INT 0 100000;
BA_DEF_ BO_ "GenMsgCycleTimeFast" FLOAT 0 300000;

BA_DEF_DEF_ "CANFD_BRS" "1";
BA_DEF_DEF_ "DiagRequest" "No";
BA_DEF_DEF_ "DiagResponse" "No";
BA_DEF_DEF_ "DiagState" "No";
BA_DEF_DEF_ "GenMsgSendType" "Cycle";
BA_DEF_DEF_ "GenSigSendType" "Cycle";
BA_DEF_DEF_ "MSG IL Support" "Yes";
BA_DEF_DEF_ "NmMessage" "No";
BA_DEF_DEF_ "VFrameFormat" "J1939PG";
BA_DEF_DEF_ "GenSigStartValue" 0;
BA_DEF_DEF_ "GenMsgNrOfRepetition" 0;
// Frame: MCUR_State_2
BA_ "VFrameFormat" BO_ 267 14;
BA_ "GenMsgCycleTime" BO_ 267 10.000;
BA_ "GenMsgStartDelayTime" BO_ 267 0.000;
BA_ "GenSigStartValue" SG_ 267 MCUR_CBKTq 500;
BA_ "GenSigStartValue" SG_ 267 MCUR_CurrtPhaA 32768;
BA_ "GenSigStartValue" SG_ 267 MCUR_CurrtPhaB 32768;
BA_ "GenSigStartValue" SG_ 267 MCUR_CurrtPhaC 32768;
BA_ "GenSigStartValue" SG_ 267 MCUR_DATSTq 500;
BA_ "GenSigStartValue" SG_ 267 MCUR_DCCurrt 10000;
BA_ "GenSigStartValue" SG_ 267 MCUR_IGBTNTCTempA 48;
BA_ "GenSigStartValue" SG_ 267 MCUR_IGBTNTCTempB 48;
BA_ "GenSigStartValue" SG_ 267 MCUR_IGBTNTCTemPC 48;
BA_ "GenSigStartValue" SG_ 267 MCUR_RMotTqContnsMax 1024;
BA_ "GenSigStartValue" SG_ 267 MCUR_RMotTqContnsMin 1024;
BA_ "GenSigStartValue" SG_ 267 MCUR_RMotTqLongMax 1024;
BA_ "GenSigStartValue" SG_ 267 MCUR_RMotTqLongMin 1024;
BA_ "GenSigStartValue" SG_ 267 MCUR_RMotTqShoMax 1024;
BA_ "GenSigStartValue" SG_ 267 MCUR_RMotTqShoMin 1024;
// Frame: MCUR_State_3
BA_ "VFrameFormat" BO_ 854 14;
BA_ "GenMsgCycleTime" BO_ 854 100.000;
BA_ "GenMsgStartDelayTime" BO_ 854 0.000;
BA_ "GenSigStartValue" SG_ 854 MCUR_EOP_MOS_Temp 40;
BA_ "GenSigStartValue" SG_ 854 MCUR_PCBTemp 48;
// Frame: MCUR_Version
BA_ "VFrameFormat" BO_ 1459 14;
BA_ "GenMsgCycleTime" BO_ 1459 10000.000;
BA_ "GenMsgStartDelayTime" BO_ 1459 0.000;
// Frame: NM_Autosar_BMS
BA_ "CANFD_BRS" BO_ 1042 1;
BA_ "GenMsgSendType" BO_ 1042 1;
BA_ "NmMessage" BO_ 1042 0;
BA_ "VFrameFormat" BO_ 1042 0;
BA_ "GenMsgDelayTime" BO_ 1042 10.000;
// Frame: NM_Autosar_CDU
BA_ "CANFD_BRS" BO_ 1045 1;
BA_ "GenMsgSendType" BO_ 1045 1;
BA_ "NmMessage" BO_ 1045 0;
BA_ "VFrameFormat" BO_ 1045 0;
BA_ "GenMsgDelayTime" BO_ 1045 10.000;
// Frame: NM_Autosar_GCU
BA_ "CANFD_BRS" BO_ 1048 1;
BA_ "GenMsgSendType" BO_ 1048 1;
BA_ "NmMessage" BO_ 1048 0;
BA_ "VFrameFormat" BO_ 1048 0;
BA_ "GenMsgDelayTime" BO_ 1048 10.000;
// Frame: NM_Autosar_MCUR
BA_ "CANFD_BRS" BO_ 1044 1;
BA_ "GenMsgSendType" BO_ 1044 1;
BA_ "NmMessage" BO_ 1044 0;
BA_ "VFrameFormat" BO_ 1044 0;
BA_ "GenMsgDelayTime" BO_ 1044 10.000;
// Frame: NM_Autosar_TDU
BA_ "CANFD_BRS" BO_ 1073 1;
BA_ "VFrameFormat" BO_ 1073 0;
BA_ "GenMsgSendType" BO_ 1073 1;
BA_ "GenMsgDelayTime" BO_ 1073 10.000;
// Frame: NM_Autosar_VDC
BA_ "CANFD_BRS" BO_ 1041 1;
BA_ "GenMsgSendType" BO_ 1041 1;
BA_ "NmMessage" BO_ 1041 0;
BA_ "VFrameFormat" BO_ 1041 0;
BA_ "GenMsgDelayTime" BO_ 1041 10.000;
// Frame: OBD_PhyReq_BMS
BA_ "VFrameFormat" BO_ 2018 14;
BA_ "GenMsgSendType" BO_ 2018 1;
BA_ "GenMsgDelayTime" BO_ 2018 20.000;
// Frame: OBD_PhyReq_GCU
BA_ "VFrameFormat" BO_ 2020 14;
BA_ "GenMsgSendType" BO_ 2020 1;
BA_ "GenMsgDelayTime" BO_ 2020 20.000;
// Frame: OBD_PhyReq_MCUR
BA_ "VFrameFormat" BO_ 2019 14;
BA_ "GenMsgSendType" BO_ 2019 1;
BA_ "GenMsgDelayTime" BO_ 2019 20.000;
// Frame: OBD_Resp_BMS
BA_ "VFrameFormat" BO_ 2026 14;
BA_ "GenMsgSendType" BO_ 2026 1;
BA_ "GenMsgDelayTime" BO_ 2026 20.000;
// Frame: OBD_Resp_GCU
BA_ "VFrameFormat" BO_ 2028 14;
BA_ "GenMsgSendType" BO_ 2028 1;
BA_ "GenMsgDelayTime" BO_ 2028 20.000;
// Frame: OBD_Resp_MCUR
BA_ "VFrameFormat" BO_ 2027 14;
BA_ "GenMsgSendType" BO_ 2027 1;
BA_ "GenMsgDelayTime" BO_ 2027 20.000;
// Frame: TBOX_RemoteSet
BA_ "GenMsgSendType" BO_ 896 2;
BA_ "VFrameFormat" BO_ 896 14;
BA_ "GenMsgCycleTime" BO_ 896 100.000;
BA_ "GenMsgStartDelayTime" BO_ 896 0.000;
BA_ "GenMsgNrOfRepetition" BO_ 896 3;
BA_ "GenMsgCycleTimeFast" BO_ 896 20.000;
BA_ "GenSigSendType" SG_ 896 TBOX_ACDefrostSet 2;
BA_ "GenSigSendType" SG_ 896 TBOX_ACONOFFSet 2;
BA_ "GenSigSendType" SG_ 896 TBOX_ACTempSet 2;
BA_ "GenSigSendType" SG_ 896 TBOX_ACVentSet 2;
BA_ "GenSigSendType" SG_ 896 TBOX_MaxACSet 2;
BA_ "GenSigSendType" SG_ 896 TBOX_MaxHeatSet 2;
BA_ "GenSigStartValue" SG_ 896 VDC_ScheduleChrgEndHour 30;
BA_ "GenSigStartValue" SG_ 896 VDC_ScheduleChrgEndMin 62;
BA_ "GenSigStartValue" SG_ 896 VDC_ScheduleChrgStarMin 62;
BA_ "GenSigStartValue" SG_ 896 VDC_ScheduleChrgStartHour 30;
// Frame: TBOX_TimeInfo
BA_ "VFrameFormat" BO_ 1506 14;
BA_ "GenMsgSendType" BO_ 1506 1;
BA_ "GenSigStartValue" SG_ 1506 TBOX_TimeDay 1;
BA_ "GenSigStartValue" SG_ 1506 TBOX_TimeMonth 1;
// Frame: TDU_ACCtrl
BA_ "VFrameFormat" BO_ 820 14;
BA_ "GenMsgCycleTime" BO_ 820 100.000;
BA_ "GenMsgStartDelayTime" BO_ 820 0.000;
BA_ "GenSigStartValue" SG_ 820 TDU_InsdTemp 680;
BA_ "GenSigStartValue" SG_ 820 TDU_OutdTemp 680;
// Frame: TDU_ACCtrl1
BA_ "VFrameFormat" BO_ 827 14;
BA_ "GenMsgCycleTime" BO_ 827 100.000;
BA_ "GenMsgStartDelayTime" BO_ 827 0.000;
// Frame: TDU_Control
BA_ "VFrameFormat" BO_ 825 14;
BA_ "GenMsgCycleTime" BO_ 825 100.000;
BA_ "GenMsgStartDelayTime" BO_ 825 0.000;
// Frame: TDU_EngThermMngt
BA_ "VFrameFormat" BO_ 823 14;
BA_ "GenMsgCycleTime" BO_ 823 100.000;
BA_ "GenMsgStartDelayTime" BO_ 823 0.000;
BA_ "GenSigStartValue" SG_ 823 TDU_EngPmpSpdHeatReq 126;
BA_ "GenSigStartValue" SG_ 823 TDU_EngPmpSpdHeatReqVld 1;
BA_ "GenSigStartValue" SG_ 823 TDU_EXV_B_LPTSnsrT 700;
BA_ "GenSigStartValue" SG_ 823 TDU_EXV_H_LPTSnsrT 700;
BA_ "GenSigStartValue" SG_ 823 TDU_IcoInlT 68;
// Frame: TDU_Fault
BA_ "VFrameFormat" BO_ 1420 14;
BA_ "GenMsgCycleTime" BO_ 1420 500.000;
BA_ "GenMsgStartDelayTime" BO_ 1420 0.000;
// Frame: TDU_HybMotCtrl
BA_ "VFrameFormat" BO_ 821 14;
BA_ "GenMsgCycleTime" BO_ 821 100.000;
BA_ "GenMsgStartDelayTime" BO_ 821 0.000;
BA_ "GenSigStartValue" SG_ 821 TDU_LeBlowFaceAirOutlT 680;
BA_ "GenSigStartValue" SG_ 821 TDU_LeBlowFootAirOutlT 680;
BA_ "GenSigStartValue" SG_ 821 TDU_RiBlowFaceAirOutlT 680;
BA_ "GenSigStartValue" SG_ 821 TDU_RiBlowFootAirOutlT 680;
// Frame: TDU_PTCCtrlFD
BA_ "VFrameFormat" BO_ 908 14;
BA_ "GenMsgCycleTime" BO_ 908 100.000;
BA_ "GenMsgStartDelayTime" BO_ 908 0.000;
BA_ "GenSigStartValue" SG_ 908 TDU_AGS1_CurrentPos 127;
BA_ "GenSigStartValue" SG_ 908 TDU_AGS2_CurrentPos 127;
BA_ "GenSigStartValue" SG_ 908 TDU_AGS_TarPos 127;
BA_ "GenSigStartValue" SG_ 908 TDU_ExInnerInletTem 680;
BA_ "GenSigStartValue" SG_ 908 TDU_ExInnerOutletTem 680;
BA_ "GenSigStartValue" SG_ 908 TDU_LePTCAirOutlT 680;
BA_ "GenSigStartValue" SG_ 908 TDU_LePTCAirOutlTrgtTemp 680;
BA_ "GenSigStartValue" SG_ 908 TDU_OtsdAirTemRaw 680;
BA_ "GenSigStartValue" SG_ 908 TDU_RiPTCAirOutlT 680;
BA_ "GenSigStartValue" SG_ 908 TDU_RiPTCAirOutlTrgtTemp 680;
// Frame: TDU_Pump
BA_ "VFrameFormat" BO_ 829 14;
BA_ "GenMsgCycleTime" BO_ 829 100.000;
BA_ "GenMsgStartDelayTime" BO_ 829 0.000;
BA_ "GenSigStartValue" SG_ 829 TDU_PumpBTemp 68;
BA_ "GenSigStartValue" SG_ 829 TDU_PumpPTemp 68;
// Frame: TDU_SubSnsrState_1
BA_ "VFrameFormat" BO_ 1329 14;
BA_ "GenMsgCycleTime" BO_ 1329 200.000;
BA_ "GenMsgStartDelayTime" BO_ 1329 0.000;
BA_ "GenSigStartValue" SG_ 1329 TDU_HPTSnsrT 700;
BA_ "GenSigStartValue" SG_ 1329 TDU_LPTSnsrT 700;
// Frame: TDU_SubSnsrState_2
BA_ "VFrameFormat" BO_ 828 14;
BA_ "GenMsgCycleTime" BO_ 828 100.000;
BA_ "GenMsgStartDelayTime" BO_ 828 0.000;
BA_ "GenSigStartValue" SG_ 828 TDU_EvaprTemp 680;
BA_ "GenSigStartValue" SG_ 828 TDU_FEvaprTrgtTemp 680;
// Frame: TDU_TempFeedBack
BA_ "VFrameFormat" BO_ 1328 14;
BA_ "GenMsgCycleTime" BO_ 1328 200.000;
BA_ "GenMsgStartDelayTime" BO_ 1328 0.000;
BA_ "GenSigStartValue" SG_ 1328 TDU_BattInlT 68;
BA_ "GenSigStartValue" SG_ 1328 TDU_BattOutlT 68;
BA_ "GenSigStartValue" SG_ 1328 TDU_MotInletWaterT 68;
// Frame: TDU_ThermalState
BA_ "VFrameFormat" BO_ 817 14;
BA_ "GenMsgCycleTime" BO_ 817 100.000;
BA_ "GenMsgStartDelayTime" BO_ 817 0.000;
// Frame: TDU_ValveCtrl
BA_ "VFrameFormat" BO_ 1333 14;
BA_ "GenMsgCycleTime" BO_ 1333 200.000;
BA_ "GenMsgStartDelayTime" BO_ 1333 0.000;
// Frame: TDU_Version
BA_ "VFrameFormat" BO_ 1461 14;
BA_ "GenMsgCycleTime" BO_ 1461 10000.000;
BA_ "GenMsgStartDelayTime" BO_ 1461 0.000;
BA_ "GenSigStartValue" SG_ 1461 TDU_PartVers 1;
// Frame: TDU_WTC_EAS
BA_ "VFrameFormat" BO_ 818 14;
BA_ "GenMsgCycleTime" BO_ 818 100.000;
BA_ "GenMsgStartDelayTime" BO_ 818 0.000;
BA_ "GenSigStartValue" SG_ 818 TDU_EAS_IPMTemp 68;
BA_ "GenSigStartValue" SG_ 818 TDU_WTC_H_CrtTemp 68;
BA_ "GenSigStartValue" SG_ 818 TDU_WTC_H_InpTemp 68;
BA_ "GenSigStartValue" SG_ 818 TDU_WTC_H_OutpTemp 68;
BA_ "GenSigStartValue" SG_ 818 TDU_WTC_H_PCBTemp 68;
BA_ "GenSigStartValue" SG_ 818 TDU_WTC_H_TarOutpTemp 68;
// Frame: VDC_BCM_DoorState
BA_ "VFrameFormat" BO_ 582 14;
BA_ "GenMsgCycleTime" BO_ 582 50.000;
BA_ "GenMsgStartDelayTime" BO_ 582 5.000;
// Frame: VDC_BCM_SeatState
BA_ "VFrameFormat" BO_ 798 14;
BA_ "GenMsgCycleTime" BO_ 798 100.000;
BA_ "GenMsgStartDelayTime" BO_ 798 0.000;
// Frame: VDC_CDC_TDUSet
BA_ "GenMsgSendType" BO_ 819 2;
BA_ "VFrameFormat" BO_ 819 14;
BA_ "GenMsgCycleTime" BO_ 819 100.000;
BA_ "GenMsgStartDelayTime" BO_ 819 0.000;
BA_ "GenMsgNrOfRepetition" BO_ 819 3;
BA_ "GenMsgCycleTimeFast" BO_ 819 20.000;
BA_ "GenSigSendType" SG_ 819 VDC_CDC_ACECOModReq 2;
BA_ "GenSigSendType" SG_ 819 VDC_CDC_ACFourZoneSync 2;
BA_ "GenSigSendType" SG_ 819 VDC_CDC_ACMaxSet 2;
BA_ "GenSigSendType" SG_ 819 VDC_CDC_ACParkAutoVentSet 2;
BA_ "GenSigSendType" SG_ 819 VDC_CDC_ACSet 2;
BA_ "GenSigSendType" SG_ 819 VDC_CDC_ACSystemOnOffSet 2;
BA_ "GenSigSendType" SG_ 819 VDC_CDC_AutoDefogSet 2;
BA_ "GenSigSendType" SG_ 819 VDC_CDC_AutoDrySet 2;
BA_ "GenSigSendType" SG_ 819 VDC_CDC_CircModSet 2;
BA_ "GenSigSendType" SG_ 819 VDC_CDC_DriverTempSet 2;
BA_ "GenSigSendType" SG_ 819 VDC_CDC_FHvacBlowLvSet 2;
BA_ "GenSigSendType" SG_ 819 VDC_CDC_FHvacModeSet 2;
BA_ "GenSigSendType" SG_ 819 VDC_CDC_FrontDefrostSet 2;
BA_ "GenSigSendType" SG_ 819 VDC_CDC_HeatMaxSet 2;
BA_ "GenSigSendType" SG_ 819 VDC_CDC_HvacAutoModeSet 2;
BA_ "GenSigSendType" SG_ 819 VDC_CDC_PassengerTempSet 2;
BA_ "GenSigSendType" SG_ 819 VDC_CDC_RACSystemOnOffSet 2;
BA_ "GenSigSendType" SG_ 819 VDC_CDC_SceneModPwrOnSts 2;
BA_ "GenSigSendType" SG_ 819 VDC_CDC_SupCoolingModSet 2;
BA_ "GenSigSendType" SG_ 819 VDC_CDC_TempExclusive 2;
BA_ "GenSigSendType" SG_ 819 VDC_CDC_VentSet 2;
// Frame: VDC_EMSCtrl
BA_ "VFrameFormat" BO_ 289 14;
BA_ "GenMsgCycleTime" BO_ 289 10.000;
BA_ "GenMsgStartDelayTime" BO_ 289 0.000;
BA_ "GenSigStartValue" SG_ 289 VDC_FlyWhFastTqReq 3500;
BA_ "GenSigStartValue" SG_ 289 VDC_FlyWhSlowTqReq 3500;
BA_ "GenSigStartValue" SG_ 289 VDC_FuelRemaining 126;
// Frame: VDC_EngyCalcu
BA_ "VFrameFormat" BO_ 1408 14;
BA_ "GenMsgCycleTime" BO_ 1408 500.000;
BA_ "GenMsgStartDelayTime" BO_ 1408 0.000;
BA_ "GenSigStartValue" SG_ 1408 VDC_EngyAfAvgLastChrg 1024;
BA_ "GenSigStartValue" SG_ 1408 VDC_EngyAfLastChrg 1000;
BA_ "GenSigStartValue" SG_ 1408 VDC_EngyAvgRstA 1024;
BA_ "GenSigStartValue" SG_ 1408 VDC_EngyAvgRstB 1024;
BA_ "GenSigStartValue" SG_ 1408 VDC_EngyDrvAvePerKm 1024;
BA_ "GenSigStartValue" SG_ 1408 VDC_EngyRstA 100;
BA_ "GenSigStartValue" SG_ 1408 VDC_EngyRstB 100;
BA_ "GenSigStartValue" SG_ 1408 VDC_EngytotalCurCyc 1000;
BA_ "GenSigStartValue" SG_ 1408 VDC_RMotPwr 2700;
// Frame: VDC_EVR
BA_ "VFrameFormat" BO_ 848 14;
BA_ "GenMsgCycleTime" BO_ 848 100.000;
BA_ "GenMsgStartDelayTime" BO_ 848 0.000;
// Frame: VDC_Fault
BA_ "VFrameFormat" BO_ 1302 14;
BA_ "GenMsgCycleTime" BO_ 1302 500.000;
BA_ "GenMsgStartDelayTime" BO_ 1302 0.000;
// Frame: VDC_GCUCtrl
BA_ "VFrameFormat" BO_ 384 14;
BA_ "GenMsgCycleTime" BO_ 384 10.000;
BA_ "GenMsgStartDelayTime" BO_ 384 0.000;
BA_ "GenSigStartValue" SG_ 384 VDC_GMotSpdReq 32768;
BA_ "GenSigStartValue" SG_ 384 VDC_GMotTqReq 32768;
BA_ "GenSigStartValue" SG_ 384 VDC_MaxEleTqLim 2048;
BA_ "GenSigStartValue" SG_ 384 VDC_MaxGenTqLim 2048;
// Frame: VDC_HVCtrl
BA_ "VFrameFormat" BO_ 385 14;
BA_ "GenMsgCycleTime" BO_ 385 20.000;
BA_ "GenMsgStartDelayTime" BO_ 385 0.000;
BA_ "GenSigStartValue" SG_ 385 VDC_ChrgTrgtSOC 100;
BA_ "GenSigStartValue" SG_ 385 VDC_OBCACCurrtMaxPerm 32;
// Frame: VDC_PTSt_VV01
BA_ "VFrameFormat" BO_ 283 14;
BA_ "GenMsgCycleTime" BO_ 283 50.000;
BA_ "GenMsgStartDelayTime" BO_ 283 5.000;
BA_ "GenSigStartValue" SG_ 283 VDC_BrakePedalFeelSet 1;
BA_ "GenSigStartValue" SG_ 283 VDC_CDCremindReq 1;
BA_ "GenSigStartValue" SG_ 283 VDC_ESCModeSet 1;
BA_ "GenSigStartValue" SG_ 283 VDC_RegenModeStatus 1;
// Frame: VDC_RMotCtrl
BA_ "VFrameFormat" BO_ 258 14;
BA_ "GenMsgCycleTime" BO_ 258 10.000;
BA_ "GenMsgStartDelayTime" BO_ 258 5.000;
BA_ "GenSigStartValue" SG_ 258 VDC_RMotMaxDrvTqLimt 2048;
BA_ "GenSigStartValue" SG_ 258 VDC_RMotMaxRegenTqLimt 2048;
BA_ "GenSigStartValue" SG_ 258 VDC_RMotSpdLimMax 600;
BA_ "GenSigStartValue" SG_ 258 VDC_RMotSpdRate 1023;
BA_ "GenSigStartValue" SG_ 258 VDC_RMotSpdReq 32768;
BA_ "GenSigStartValue" SG_ 258 VDC_RMotTqRateLimMax 255;
BA_ "GenSigStartValue" SG_ 258 VDC_RMotTqRateLimMin 255;
BA_ "GenSigStartValue" SG_ 258 VDC_RMotTqReq 32768;
BA_ "GenSigStartValue" SG_ 258 VDC_RMotTqUnloadRate 255;
// Frame: VDC_RMtTq_PT
BA_ "VFrameFormat" BO_ 275 14;
BA_ "GenMsgCycleTime" BO_ 275 50.000;
BA_ "GenMsgStartDelayTime" BO_ 275 5.000;
BA_ "GenSigStartValue" SG_ 275 VDC_CoastRegenRequest_RA 32768;
BA_ "GenSigStartValue" SG_ 275 VDC_DriverTorqueDesired 32768;
BA_ "GenSigStartValue" SG_ 275 VDC_OPDHydBrkCompenRqTq 65535;
BA_ "GenSigStartValue" SG_ 275 VDC_rearMotorRpm 30000;
BA_ "GenSigStartValue" SG_ 275 VDC_VehWhlActTq 32768;
BA_ "GenSigStartValue" SG_ 275 VDC_VehWhlReqTq 32768;
// Frame: VDC_SysState
BA_ "VFrameFormat" BO_ 388 14;
BA_ "GenMsgCycleTime" BO_ 388 20.000;
BA_ "GenMsgStartDelayTime" BO_ 388 5.000;
BA_ "GenSigStartValue" SG_ 388 VDC_AccrPedlUFirst_Input 8190;
BA_ "GenSigStartValue" SG_ 388 VDC_AccrPedlUSecond_Input 8190;
BA_ "GenSigStartValue" SG_ 388 VDC_RoadSlop 250;
BA_ "GenSigStartValue" SG_ 388 VDC_RoadSlopRate 250;
BA_ "GenSigStartValue" SG_ 388 VDC_TargetGearSt 1;
// Frame: VDC_VehState
BA_ "VFrameFormat" BO_ 785 14;
BA_ "GenMsgCycleTime" BO_ 785 100.000;
BA_ "GenMsgStartDelayTime" BO_ 785 5.000;
BA_ "GenSigStartValue" SG_ 785 VDC_CoastRegnSt 1;
BA_ "GenSigStartValue" SG_ 785 VDC_CreepModSt 1;
BA_ "GenSigStartValue" SG_ 785 VDC_EstimdSlop 254;
BA_ "GenSigStartValue" SG_ 785 VDC_TVModSt 1;
// Frame: VDC_VehSts
BA_ "VFrameFormat" BO_ 788 14;
BA_ "GenMsgCycleTime" BO_ 788 100.000;
BA_ "GenMsgStartDelayTime" BO_ 788 5.000;
// Frame: VDC_Version
BA_ "VFrameFormat" BO_ 1456 14;
BA_ "GenMsgCycleTime" BO_ 1456 10000.000;
BA_ "GenMsgStartDelayTime" BO_ 1456 0.000;
// Frame: VIU_API2CAN_EVR
BA_ "VFrameFormat" BO_ 857 14;
BA_ "GenMsgCycleTime" BO_ 857 100.000;
BA_ "GenMsgStartDelayTime" BO_ 857 5.000;
BA_ "GenSigStartValue" SG_ 857 VIU_AmbT 680;
BA_ "GenSigStartValue" SG_ 857 VIU_OilSnsrResistorVal 510;
// Frame: VIU_DoorLock_VV01
BA_ "VFrameFormat" BO_ 688 14;
BA_ "GenMsgCycleTime" BO_ 688 50.000;
BA_ "GenMsgStartDelayTime" BO_ 688 0.000;
// Frame: VIU_Info_VV02
BA_ "VFrameFormat" BO_ 467 14;
BA_ "GenMsgCycleTime" BO_ 467 20.000;
BA_ "GenMsgStartDelayTime" BO_ 467 0.000;
BA_ "GenSigStartValue" SG_ 467 VIU_CarMode 14;
BA_ "GenSigStartValue" SG_ 467 VIU_UsageMode 1;
// Frame: VIU_Route_EP
BA_ "GenMsgSendType" BO_ 856 2;
BA_ "VFrameFormat" BO_ 856 14;
BA_ "GenMsgCycleTime" BO_ 856 100.000;
BA_ "GenMsgStartDelayTime" BO_ 856 5.000;
BA_ "GenMsgNrOfRepetition" BO_ 856 3;
BA_ "GenMsgCycleTimeFast" BO_ 856 20.000;
BA_ "GenSigStartValue" SG_ 856 RSM_LeSolarInten 254;
BA_ "GenSigStartValue" SG_ 856 RSM_RiSolarInten 254;
BA_ "GenSigSendType" SG_ 856 VIU_Reserved 4;
// Frame: VIU_Route_EP_2
BA_ "VFrameFormat" BO_ 463 14;
BA_ "GenMsgCycleTime" BO_ 463 20.000;
BA_ "GenMsgStartDelayTime" BO_ 463 5.000;
BA_ "GenSigStartValue" SG_ 463 EPS_SteerWheelAngle 7800;
BA_ "GenSigStartValue" SG_ 463 IBS_AVHAvailable 1;
// Frame: VIU_Route_EVR_1
BA_ "VFrameFormat" BO_ 796 14;
BA_ "GenMsgCycleTime" BO_ 796 100.000;
BA_ "GenMsgStartDelayTime" BO_ 796 5.000;
VAL_ 267 MCUR_CBKTq 1023 "MCUR_CBKTq_1023_Invalid";
VAL_ 267 MCUR_CurrtPhaA 65535 "MCUR_CurrtPhaA_65535_Invalid";
VAL_ 267 MCUR_CurrtPhaB 65535 "MCUR_CurrtPhaB_65535_Invalid";
VAL_ 267 MCUR_CurrtPhaC 65535 "MCUR_CurrtPhaC_65535_Invalid";
VAL_ 267 MCUR_DATSTq 1023 "MCUR_DATSTq_1023_Invalid";
VAL_ 267 MCUR_DCCurrt 65535 "MCUR_DCCurrt_65535_Invalid";
VAL_ 267 MCUR_DCVolt 65535 "MCUR_DCVolt_65535_Invalid";
VAL_ 267 MCUR_FaultLamp 0 "MCUR_FaultLamp_0_OFF" 1 "MCUR_FaultLamp_1_ON";
VAL_ 267 MCUR_IGBTNTCTempA 255 "MCUR_IGBTNTCTempA_255_Invalid";
VAL_ 267 MCUR_IGBTNTCTempB 255 "MCUR_IGBTNTCTempB_255_Invalid";
VAL_ 267 MCUR_IGBTNTCTemPC 255 "MCUR_IGBTNTCTemPC_255_Invalid";
VAL_ 267 MCUR_KL30_Volt 511 "MCUR_KL30_Volt_511_Invalid";
VAL_ 267 MCUR_MIL_Request 0 "MCUR_MIL_Request_0_NO_Request" 1 "MCUR_MIL_Request_1_Request_On";
VAL_ 267 MCUR_OBDFaultExistSts 0 "MCUR_OBDFaultExistSts_0_No_OBD_Fault" 1 "MCUR_OBDFaultExistSts_1_OBD_Fault";
VAL_ 267 MCUR_RMotActvDampLvlSt 0 "MCUR_RMotActvDampLvlSt_0_Normal" 1 "MCUR_RMotActvDampLvlSt_1_Soft_(DTC/CRB激活)" 2 "MCUR_RMotActvDampLvlSt_2_Slip_(TCS激活)" 3 "MCUR_RMotActvDampLvlSt_3_High";
VAL_ 267 MCUR_RMotTqContnsMax 2047 "MCUR_RMotTqContnsMax_2047_Invalid";
VAL_ 267 MCUR_RMotTqContnsMin 2047 "MCUR_RMotTqContnsMin_2047_Invalid";
VAL_ 267 MCUR_RMotTqLongMax 2047 "MCUR_RMotTqLongMax_2047_Invalid";
VAL_ 267 MCUR_RMotTqLongMin 2047 "MCUR_RMotTqLongMin_2047_Invalid";
VAL_ 267 MCUR_RMotTqShoMax 2047 "MCUR_RMotTqShoMax_2047_Invalid";
VAL_ 267 MCUR_RMotTqShoMin 2047 "MCUR_RMotTqShoMin_2047_Invalid";
VAL_ 854 MCUR_CBKEnaSt 0 "MCUR_CBKEnaSt_0_OFF" 1 "MCUR_CBKEnaSt_1_ON";
VAL_ 854 MCUR_DATSEnableSt 0 "MCUR_DATSEnableSt_0_OFF" 1 "MCUR_DATSEnableSt_1_ON";
VAL_ 854 MCUR_DCHV_OverU_OBDFlt 0 "MCUR_DCHV_OverU_OBDFlt_0_No_Error" 1 "MCUR_DCHV_OverU_OBDFlt_1_Error" 2 "MCUR_DCHV_OverU_OBDFlt_2_Reserved";
VAL_ 854 MCUR_EOP_AIRmix_Fault 0 "MCUR_EOP_AIRmix_Fault_0_Normal" 1 "MCUR_EOP_AIRmix_Fault_1_Fault";
VAL_ 854 MCUR_EOP_Current 255 "MCUR_EOP_Current_255_Invalid";
VAL_ 854 MCUR_EOP_MOS_Temp 255 "MCUR_EOP_MOS_Temp_255_Invalid";
VAL_ 854 MCUR_EOP_Over_Current_Fault 0 "MCUR_EOP_Over_Current_Fault_0_Normal" 1 "MCUR_EOP_Over_Current_Fault_1_Fault";
VAL_ 854 MCUR_EOP_Over_Temp_Fault 0 "MCUR_EOP_Over_Temp_Fault_0_Normal" 1 "MCUR_EOP_Over_Temp_Fault_1_Fault";
VAL_ 854 MCUR_EOP_Over_Voltage_Fault 0 "MCUR_EOP_Over_Voltage_Fault_0_Normal" 1 "MCUR_EOP_Over_Voltage_Fault_1_Fault";
VAL_ 854 MCUR_EOP_Self_Check_Fault 0 "MCUR_EOP_Self_Check_Fault_0_Normal" 1 "MCUR_EOP_Self_Check_Fault_1_Fault";
VAL_ 854 MCUR_EOP_State 0 "MCUR_EOP_State_0_Standby" 1 "MCUR_EOP_State_1_Running" 2 "MCUR_EOP_State_2_Degraded_Running" 3 "MCUR_EOP_State_3_Fault";
VAL_ 854 MCUR_EOP_Stuck_Fault 0 "MCUR_EOP_Stuck_Fault_0_Normal" 1 "MCUR_EOP_Stuck_Fault_1_Fault";
VAL_ 854 MCUR_EOP_Under_Voltage_Fault 0 "MCUR_EOP_Under_Voltage_Fault_0_Normal" 1 "MCUR_EOP_Under_Voltage_Fault_1_Fault";
VAL_ 854 MCUR_EOP_Voltage 255 "MCUR_EOP_Voltage_255_Invalid";
VAL_ 854 MCUR_HVAuxPwrSt 0 "MCUR_HVAuxPwrSt_0_OFF" 1 "MCUR_HVAuxPwrSt_1_ON";
VAL_ 854 MCUR_HVCalSt 0 "MCUR_HVCalSt_0_Not_calibrated" 1 "MCUR_HVCalSt_1_Calibration_in_progress" 2 "MCUR_HVCalSt_2_Calibration_Failure" 3 "MCUR_HVCalSt_3_Calibration_Completed";
VAL_ 854 MCUR_HWWakeupSt 0 "MCUR_HWWakeupSt_0_Invalid" 1 "MCUR_HWWakeupSt_1_Valid";
VAL_ 854 MCUR_IGBTOverTWarn_OBDFlt 0 "MCUR_IGBTOverTWarn_OBDFlt_0_No_Error" 1 "MCUR_IGBTOverTWarn_OBDFlt_1_Error" 2 "MCUR_IGBTOverTWarn_OBDFlt_2_Reserved";
VAL_ 854 MCUR_KL30_OverU_OBDFlt 0 "MCUR_KL30_OverU_OBDFlt_0_No_Error" 1 "MCUR_KL30_OverU_OBDFlt_1_Error" 2 "MCUR_KL30_OverU_OBDFlt_2_Reserved";
VAL_ 854 MCUR_MotOverTWarn_OBDFlt 0 "MCUR_MotOverTWarn_OBDFlt_0_No_Error" 1 "MCUR_MotOverTWarn_OBDFlt_1_Error" 2 "MCUR_MotOverTWarn_OBDFlt_2_Reserved";
VAL_ 854 MCUR_PCBTemp 255 "MCUR_PCBTemp_255_Invalid";
VAL_ 854 MCUR_RMotHeatActPwr 127 "MCUR_RMotHeatActPwr_127_Invalid";
VAL_ 854 MCUR_RMotHeatMaxPwr 127 "MCUR_RMotHeatMaxPwr_127_Invalid";
VAL_ 854 MCUR_RMotHeatSt 0 "MCUR_RMotHeatSt_0_Standby" 1 "MCUR_RMotHeatSt_1_Static_Heating" 2 "MCUR_RMotHeatSt_2_Running_Heating" 3 "MCUR_RMotHeatSt_3_Invalid";
VAL_ 896 TBOX_ACDefrostSet 0 "TBOX_ACDefrostSet_0_NO_Request" 1 "TBOX_ACDefrostSet_1_OFF" 2 "TBOX_ACDefrostSet_2_ON" 3 "TBOX_ACDefrostSet_3_Reserved";
VAL_ 896 TBOX_ACONOFFSet 0 "TBOX_ACONOFFSet_0_NO_Request" 1 "TBOX_ACONOFFSet_1_OFF" 2 "TBOX_ACONOFFSet_2_ON" 3 "TBOX_ACONOFFSet_3_Reserved";
VAL_ 896 Tbox_ACParkAutoVentSetSts 0 "Tbox_ACParkAutoVentSetSts_0_Initial" 1 "Tbox_ACParkAutoVentSetSts_1_OFF" 2 "Tbox_ACParkAutoVentSetSts_2_ON" 3 "Tbox_ACParkAutoVentSetSts_3_Reserved";
VAL_ 896 TBOX_ACTempSet 0 "TBOX_ACTempSet_0_NO_Request" 63 "TBOX_ACTempSet_63_Invalid";
VAL_ 896 TBOX_ACVentSet 0 "TBOX_ACVentSet_0_NO_Request" 1 "TBOX_ACVentSet_1_OFF" 2 "TBOX_ACVentSet_2_ON" 3 "TBOX_ACVentSet_3_Reserved";
VAL_ 896 TBOX_MaxACSet 0 "TBOX_MaxACSet_0_NO_Request" 1 "TBOX_MaxACSet_1_OFF" 2 "TBOX_MaxACSet_2_ON" 3 "TBOX_MaxACSet_3_Reserved";
VAL_ 896 TBOX_MaxHeatSet 0 "TBOX_MaxHeatSet_0_NO_Request" 1 "TBOX_MaxHeatSet_1_OFF" 2 "TBOX_MaxHeatSet_2_ON" 3 "TBOX_MaxHeatSet_3_Reserved";
VAL_ 896 VDC_ScheduleChrgEndHour 31 "VDC_ScheduleChrgEndHour_31_Invalid";
VAL_ 896 VDC_ScheduleChrgEndMin 63 "VDC_ScheduleChrgEndMin_63_Invalid";
VAL_ 896 VDC_ScheduleChrgStarMin 63 "VDC_ScheduleChrgStarMin_63_Invalid";
VAL_ 896 VDC_ScheduleChrgStartHour 31 "VDC_ScheduleChrgStartHour_31_Invalid";
VAL_ 1506 TBOX_DSTFlag 0 "TBOX_DSTFlag_0_Invalid" 1 "TBOX_DSTFlag_1_Valid";
VAL_ 1506 TBOX_TimeFlag 0 "TBOX_TimeFlag_0_Invalid" 1 "TBOX_TimeFlag_1_Valid" 2 "TBOX_TimeFlag_2_With_Offset(Reserved)" 3 "TBOX_TimeFlag_3_Reserved";
VAL_ 1506 TBOX_TimeZone 0 "TBOX_TimeZone_0_Initial" 1 "TBOX_TimeZone_1_East" 2 "TBOX_TimeZone_2_West" 3 "TBOX_TimeZone_3_Reserved";
VAL_ 1506 TBOX_TimeZoneNum 0 "TBOX_TimeZoneNum_0_TimeZone_0" 1 "TBOX_TimeZoneNum_1_TimeZone_1" 2 "TBOX_TimeZoneNum_2_TimeZone_2" 3 "TBOX_TimeZoneNum_3_TimeZone_3" 4 "TBOX_TimeZoneNum_4_TimeZone_4" 5 "TBOX_TimeZoneNum_5_TimeZone_5" 6 "TBOX_TimeZoneNum_6_TimeZone_6" 7 "TBOX_TimeZoneNum_7_TimeZone_7" 8 "TBOX_TimeZoneNum_8_TimeZone_8" 9 "TBOX_TimeZoneNum_9_TimeZone_9" 10 "TBOX_TimeZoneNum_10_TimeZone_10" 11 "TBOX_TimeZoneNum_11_TimeZone_11" 12 "TBOX_TimeZoneNum_12_TimeZone_12" 13 "TBOX_TimeZoneNum_13_TimeZone_13" 14 "TBOX_TimeZoneNum_14_TimeZone_14" 15 "TBOX_TimeZoneNum_15_Reserved";
VAL_ 820 TDU_ACMainSwtSts 0 "TDU_ACMainSwtSts_0_Initial" 1 "TDU_ACMainSwtSts_1_OFF" 2 "TDU_ACMainSwtSts_2_ON" 3 "TDU_ACMainSwtSts_3_Reserved";
VAL_ 820 TDU_ACMaxSts 0 "TDU_ACMaxSts_0_Initial" 1 "TDU_ACMaxSts_1_OFF" 2 "TDU_ACMaxSts_2_ON" 3 "TDU_ACMaxSts_3_Reserved";
VAL_ 820 TDU_ACSts 0 "TDU_ACSts_0_Initial" 1 "TDU_ACSts_1_OFF" 2 "TDU_ACSts_2_ON" 3 "TDU_ACSts_3_Reserved";
VAL_ 820 TDU_ACSyncSts 0 "TDU_ACSyncSts_0_Initial" 1 "TDU_ACSyncSts_1_OFF" 2 "TDU_ACSyncSts_2_ON" 3 "TDU_ACSyncSts_3_Reserved";
VAL_ 820 TDU_ACWorkModeSts 0 "TDU_ACWorkModeSts_0_Initial" 1 "TDU_ACWorkModeSts_1_Cooling" 2 "TDU_ACWorkModeSts_2_Heating" 3 "TDU_ACWorkModeSts_3_Ventilation" 4 "TDU_ACWorkModeSts_4_reserved" 5 "TDU_ACWorkModeSts_5_reserved" 6 "TDU_ACWorkModeSts_6_reserved" 7 "TDU_ACWorkModeSts_7_Reserved";
VAL_ 820 TDU_AutoDefogRunSts 0 "TDU_AutoDefogRunSts_0_initial" 1 "TDU_AutoDefogRunSts_1_Running" 2 "TDU_AutoDefogRunSts_2_STOP" 3 "TDU_AutoDefogRunSts_3_invaild";
VAL_ 820 TDU_AutoDefogSts 0 "TDU_AutoDefogSts_0_Initial" 1 "TDU_AutoDefogSts_1_OFF" 2 "TDU_AutoDefogSts_2_ON" 3 "TDU_AutoDefogSts_3_Reserved";
VAL_ 820 TDU_CircModSts 0 "TDU_CircModSts_0_Initial" 1 "TDU_CircModSts_1_Internal" 2 "TDU_CircModSts_2_External" 3 "TDU_CircModSts_3_Auto";
VAL_ 820 TDU_DriverTempSts 0 "TDU_DriverTempSts_0_Initial" 63 "TDU_DriverTempSts_63_Invalid";
VAL_ 820 TDU_FBlowModeAutoSts 0 "TDU_FBlowModeAutoSts_0_Auto" 1 "TDU_FBlowModeAutoSts_1_Not_Auto";
VAL_ 820 TDU_FHvacBlowLv 0 "TDU_FHvacBlowLv_0_OFF" 1 "TDU_FHvacBlowLv_1_Level_1" 2 "TDU_FHvacBlowLv_2_Level_2" 3 "TDU_FHvacBlowLv_3_Level_3" 4 "TDU_FHvacBlowLv_4_Level_4" 5 "TDU_FHvacBlowLv_5_Level_5" 6 "TDU_FHvacBlowLv_6_Level_6" 7 "TDU_FHvacBlowLv_7_Level_7" 8 "TDU_FHvacBlowLv_8_Level_8" 9 "TDU_FHvacBlowLv_9_Level_9" 10 "TDU_FHvacBlowLv_10_Reserved" 15 "TDU_FHvacBlowLv_15_Reserved";
VAL_ 820 TDU_FHvacBlowLvAutoSts 0 "TDU_FHvacBlowLvAutoSts_0_Auto" 1 "TDU_FHvacBlowLvAutoSts_1_Not_Auto";
VAL_ 820 TDU_FogRiskLvl 0 "TDU_FogRiskLvl_0_Initial/No_Level" 1 "TDU_FogRiskLvl_1_Level_1" 2 "TDU_FogRiskLvl_2_Level_2" 3 "TDU_FogRiskLvl_3_Level_3" 4 "TDU_FogRiskLvl_4_Level_4" 5 "TDU_FogRiskLvl_5_Level_5" 6 "TDU_FogRiskLvl_6_Level_6" 7 "TDU_FogRiskLvl_7_Reserved";
VAL_ 820 TDU_FrontAutoSts 0 "TDU_FrontAutoSts_0_Initial" 1 "TDU_FrontAutoSts_1_OFF" 2 "TDU_FrontAutoSts_2_ON" 3 "TDU_FrontAutoSts_3_Reserved";
VAL_ 820 TDU_FrontBlowModeSts 0 "TDU_FrontBlowModeSts_0_Initial" 1 "TDU_FrontBlowModeSts_1_BlowFace" 2 "TDU_FrontBlowModeSts_2_BlowFace_&_Foot" 3 "TDU_FrontBlowModeSts_3_BlowFoot" 4 "TDU_FrontBlowModeSts_4_BlowFoot_&_Windows" 5 "TDU_FrontBlowModeSts_5_BlowWindows" 6 "TDU_FrontBlowModeSts_6_BlowFace_&_Windows" 7 "TDU_FrontBlowModeSts_7_BlowFace_&_Foot_&_Windows" 8 "TDU_FrontBlowModeSts_8_OFF" 9 "TDU_FrontBlowModeSts_9_Reserved" 15 "TDU_FrontBlowModeSts_15_Reserved";
VAL_ 820 TDU_FrontDefrostSts 0 "TDU_FrontDefrostSts_0_Initial" 1 "TDU_FrontDefrostSts_1_OFF" 2 "TDU_FrontDefrostSts_2_ON" 3 "TDU_FrontDefrostSts_3_Reserved";
VAL_ 820 TDU_HeatMaxSts 0 "TDU_HeatMaxSts_0_Initial" 1 "TDU_HeatMaxSts_1_OFF" 2 "TDU_HeatMaxSts_2_ON" 3 "TDU_HeatMaxSts_3_Reserved";
VAL_ 820 TDU_InsdTemp 4095 "TDU_InsdTemp_4095_Invalid";
VAL_ 820 TDU_OutdTemp 4095 "TDU_OutdTemp_4095_Invalid";
VAL_ 820 TDU_ParkAutoVentSts 0 "TDU_ParkAutoVentSts_0_Initial" 1 "TDU_ParkAutoVentSts_1_OFF" 2 "TDU_ParkAutoVentSts_2_ON" 3 "TDU_ParkAutoVentSts_3_Reserved";
VAL_ 820 TDU_PassengerTemptSts 0 "TDU_PassengerTemptSts_0_Initial" 63 "TDU_PassengerTemptSts_63_Invalid";
VAL_ 820 TDU_RACMainSwtSts 0 "TDU_RACMainSwtSts_0_Initial" 1 "TDU_RACMainSwtSts_1_OFF" 2 "TDU_RACMainSwtSts_2_ON" 3 "TDU_RACMainSwtSts_3_Reserved";
VAL_ 820 TDU_TempExclusiveSts 0 "TDU_TempExclusiveSts_0_Initial" 1 "TDU_TempExclusiveSts_1_OFF" 2 "TDU_TempExclusiveSts_2_ON" 3 "TDU_TempExclusiveSts_3_Reserved";
VAL_ 820 TDU_UnlockVentSt 0 "TDU_UnlockVentSt_0_Initial" 1 "TDU_UnlockVentSt_1_OFF" 2 "TDU_UnlockVentSt_2_ON" 3 "TDU_UnlockVentSt_3_Reserved";
VAL_ 827 TDU_ACECOModSts 0 "TDU_ACECOModSts_0_Initial" 1 "TDU_ACECOModSts_1_OFF" 2 "TDU_ACECOModSts_2_ON" 3 "TDU_ACECOModSts_3_Invalid";
VAL_ 827 TDU_AGS1_Position_Cmd 255 "TDU_AGS1_Position_Cmd_255_Invalid";
VAL_ 827 TDU_AutoDrySts 0 "TDU_AutoDrySts_0_Initial" 1 "TDU_AutoDrySts_1_OFF" 2 "TDU_AutoDrySts_2_ON" 3 "TDU_AutoDrySts_3_Invalid";
VAL_ 827 TDU_RemDefrostSts 0 "TDU_RemDefrostSts_0_Standby" 1 "TDU_RemDefrostSts_1_Work" 2 "TDU_RemDefrostSts_2_Fault" 3 "TDU_RemDefrostSts_3_Reserved";
VAL_ 827 TDU_RemFaultSts 0 "TDU_RemFaultSts_0_Normal" 1 "TDU_RemFaultSts_1_Fault" 2 "TDU_RemFaultSts_2_Reserved" 3 "TDU_RemFaultSts_3_Reserved";
VAL_ 827 TDU_RemSts 0 "TDU_RemSts_0_Standby" 1 "TDU_RemSts_1_Work" 2 "TDU_RemSts_2_Fault" 3 "TDU_RemSts_3_Reserved";
VAL_ 827 TDU_RemTempSetSts 0 "TDU_RemTempSetSts_0_Inactive" 1 "TDU_RemTempSetSts_1_Low" 36 "TDU_RemTempSetSts_36_18℃" 37 "TDU_RemTempSetSts_37_18.5℃" 38 "TDU_RemTempSetSts_38_19℃" 39 "TDU_RemTempSetSts_39_19.5℃" 40 "TDU_RemTempSetSts_40_20℃" 41 "TDU_RemTempSetSts_41_20.5℃" 42 "TDU_RemTempSetSts_42_21℃" 43 "TDU_RemTempSetSts_43_21.5℃" 44 "TDU_RemTempSetSts_44_22℃" 45 "TDU_RemTempSetSts_45_22.5℃" 46 "TDU_RemTempSetSts_46_23℃" 47 "TDU_RemTempSetSts_47_23.5℃" 48 "TDU_RemTempSetSts_48_24℃" 49 "TDU_RemTempSetSts_49_24.5℃" 50 "TDU_RemTempSetSts_50_25℃" 51 "TDU_RemTempSetSts_51_25.5℃" 52 "TDU_RemTempSetSts_52_26℃" 53 "TDU_RemTempSetSts_53_26.5℃" 54 "TDU_RemTempSetSts_54_27℃" 55 "TDU_RemTempSetSts_55_27.5℃" 56 "TDU_RemTempSetSts_56_28℃" 57 "TDU_RemTempSetSts_57_28.5℃" 58 "TDU_RemTempSetSts_58_29℃" 59 "TDU_RemTempSetSts_59_29.5℃" 60 "TDU_RemTempSetSts_60_30℃" 61 "TDU_RemTempSetSts_61_30.5℃" 62 "TDU_RemTempSetSts_62_31℃" 63 "TDU_RemTempSetSts_63_31.5℃" 64 "TDU_RemTempSetSts_64_32℃" 65 "TDU_RemTempSetSts_65_High" 255 "TDU_RemTempSetSts_255_Invalid";
VAL_ 827 TDU_VentSts 0 "TDU_VentSts_0_Initial" 1 "TDU_VentSts_1_OFF" 2 "TDU_VentSts_2_ON" 3 "TDU_VentSts_3_Reserved";
VAL_ 825 TDU_EnaCmd_EAS 0 "TDU_EnaCmd_EAS_0_Disable" 1 "TDU_EnaCmd_EAS_1_Enable";
VAL_ 825 TDU_EnaCmd_WTC_H 0 "TDU_EnaCmd_WTC_H_0_Disable" 1 "TDU_EnaCmd_WTC_H_1_Enable" 2 "TDU_EnaCmd_WTC_H_2_Enable_Discharge" 3 "TDU_EnaCmd_WTC_H_3_Reserved";
VAL_ 825 TDU_TrgtGear_WTC_H 0 "TDU_TrgtGear_WTC_H_0_0" 1 "TDU_TrgtGear_WTC_H_1_1" 2 "TDU_TrgtGear_WTC_H_2_2" 3 "TDU_TrgtGear_WTC_H_3_3" 4 "TDU_TrgtGear_WTC_H_4_4" 5 "TDU_TrgtGear_WTC_H_5_5" 6 "TDU_TrgtGear_WTC_H_6_6" 7 "TDU_TrgtGear_WTC_H_7_7" 8 "TDU_TrgtGear_WTC_H_8_8" 9 "TDU_TrgtGear_WTC_H_9_9" 10 "TDU_TrgtGear_WTC_H_10_10" 11 "TDU_TrgtGear_WTC_H_11_11" 12 "TDU_TrgtGear_WTC_H_12_12" 13 "TDU_TrgtGear_WTC_H_13_13" 14 "TDU_TrgtGear_WTC_H_14_14" 15 "TDU_TrgtGear_WTC_H_15_15" 16 "TDU_TrgtGear_WTC_H_16_16" 17 "TDU_TrgtGear_WTC_H_17_reserved";
VAL_ 825 TDU_TrgtPwrReq_WTC_H 65535 "TDU_TrgtPwrReq_WTC_H_65535_Invalid";
VAL_ 823 TDU_CVM_B_ActPerc 255 "TDU_CVM_B_ActPerc_255_Invalid";
VAL_ 823 TDU_CVM_B_TrgtPerc 255 "TDU_CVM_B_TrgtPerc_255_Invalid";
VAL_ 823 TDU_CVM_H_ActPerc 255 "TDU_CVM_H_ActPerc_255_Invalid";
VAL_ 823 TDU_CVM_H_TrgtPerc 255 "TDU_CVM_H_TrgtPerc_255_Invalid";
VAL_ 823 TDU_EngingstartReq 0 "TDU_EngingstartReq_0_NO_request" 1 "TDU_EngingstartReq_1_start_request";
VAL_ 823 TDU_EngPmpSpdHeatReq 126 "TDU_EngPmpSpdHeatReq_126_Initial";
VAL_ 823 TDU_EngPmpSpdHeatReqVld 0 "TDU_EngPmpSpdHeatReqVld_0_Invalid" 1 "TDU_EngPmpSpdHeatReqVld_1_Vaild";
VAL_ 823 TDU_EXV_B_LPTSnsrT 4095 "TDU_EXV_B_LPTSnsrT_4095_Invalid";
VAL_ 823 TDU_EXV_H_LPTSnsrT 4095 "TDU_EXV_H_LPTSnsrT_4095_Invalid";
VAL_ 823 TDU_FWV_location 511 "TDU_FWV_location_511_Invalid";
VAL_ 823 TDU_FWV_location_FB 255 "TDU_FWV_location_FB_255_Invalid";
VAL_ 823 TDU_IcoInlT 255 "TDU_IcoInlT_255_Invalid";
VAL_ 821 TDU_CircHybThrMotActPerc 0 "TDU_CircHybThrMotActPerc_0_Inner_loop" 100 "TDU_CircHybThrMotActPerc_100_Outer_loop";
VAL_ 821 TDU_CircHybThrMotTrgtPerc 0 "TDU_CircHybThrMotTrgtPerc_0_Inner_loop" 100 "TDU_CircHybThrMotTrgtPerc_100_Outer_loop";
VAL_ 821 TDU_LeBlowFaceAirOutlT 4095 "TDU_LeBlowFaceAirOutlT_4095_Invalid";
VAL_ 821 TDU_LeBlowFootAirOutlT 4095 "TDU_LeBlowFootAirOutlT_4095_Invalid";
VAL_ 821 TDU_LeModHybThrMotActGear_F 0 "TDU_LeModHybThrMotActGear_F_0_Initial" 1 "TDU_LeModHybThrMotActGear_F_1_BlowFace" 2 "TDU_LeModHybThrMotActGear_F_2_BlowFace_&_Foot" 3 "TDU_LeModHybThrMotActGear_F_3_BlowFoot" 4 "TDU_LeModHybThrMotActGear_F_4_BlowFoot_&_Windows" 5 "TDU_LeModHybThrMotActGear_F_5_BlowWindows" 6 "TDU_LeModHybThrMotActGear_F_6_BlowFace_&_Windows" 7 "TDU_LeModHybThrMotActGear_F_7_BlowFace_&_Foot_&_Windows" 8 "TDU_LeModHybThrMotActGear_F_8_Reserved";
VAL_ 821 TDU_LeModHybThrMotTrgtGear_F 0 "TDU_LeModHybThrMotTrgtGear_F_0_Initial" 1 "TDU_LeModHybThrMotTrgtGear_F_1_BlowFace" 2 "TDU_LeModHybThrMotTrgtGear_F_2_BlowFace_&_Foot" 3 "TDU_LeModHybThrMotTrgtGear_F_3_BlowFoot" 4 "TDU_LeModHybThrMotTrgtGear_F_4_BlowFoot_&_Windows" 5 "TDU_LeModHybThrMotTrgtGear_F_5_BlowWindows" 6 "TDU_LeModHybThrMotTrgtGear_F_6_BlowFace_&_Windows" 7 "TDU_LeModHybThrMotTrgtGear_F_7_BlowFace_&_Foot_&_Windows" 8 "TDU_LeModHybThrMotTrgtGear_F_8_Reserved";
VAL_ 821 TDU_LeTHybThrMotActPerc_F 0 "TDU_LeTHybThrMotActPerc_F_0_Full_Cool" 100 "TDU_LeTHybThrMotActPerc_F_100_Full_Heat";
VAL_ 821 TDU_LeTHybThrMotTrgtPerc_F 0 "TDU_LeTHybThrMotTrgtPerc_F_0_Full_Cool" 100 "TDU_LeTHybThrMotTrgtPerc_F_100_Full_Heat";
VAL_ 821 TDU_RiBlowFaceAirOutlT 4095 "TDU_RiBlowFaceAirOutlT_4095_Invalid";
VAL_ 821 TDU_RiBlowFootAirOutlT 4095 "TDU_RiBlowFootAirOutlT_4095_Invalid";
VAL_ 821 TDU_RiTHybThrMotActPerc_F 0 "TDU_RiTHybThrMotActPerc_F_0_Full_Cool" 100 "TDU_RiTHybThrMotActPerc_F_100_Full_Heat";
VAL_ 821 TDU_RiTHybThrMotTrgtPerc_F 0 "TDU_RiTHybThrMotTrgtPerc_F_0_Full_Cool" 100 "TDU_RiTHybThrMotTrgtPerc_F_100_Full_Heat";
VAL_ 908 ACComprMngmntInfo 0 "ACComprMngmntInfo_0_Normal_Work" 1 "ACComprMngmntInfo_1_Over_pressure" 2 "ACComprMngmntInfo_2_Low_blower_voltage" 3 "ACComprMngmntInfo_3_Under_pressure" 4 "ACComprMngmntInfo_4_No_AC_Need" 5 "ACComprMngmntInfo_5_Engine_on_time_less_than_some_seconds" 6 "ACComprMngmntInfo_6_Ac_off_and_Econ_On" 7 "ACComprMngmntInfo_7_Off_mode" 8 "ACComprMngmntInfo_8_Low_ambient_Temp" 9 "ACComprMngmntInfo_9_Operation_Mode_0" 10 "ACComprMngmntInfo_10_Low_battery" 11 "ACComprMngmntInfo_11_EngineHigh_coolant_Temp" 12 "ACComprMngmntInfo_12_AcOffMSGRq" 13 "ACComprMngmntInfo_13_High_battery" 14 "ACComprMngmntInfo_14_Low_Evap_Temp" 15 "ACComprMngmntInfo_15_Nmax_Pressure_Error" 16 "ACComprMngmntInfo_16_ComprPWMError" 17 "ACComprMngmntInfo_17_Coolant_Pressure_Error" 18 "ACComprMngmntInfo_18_BurnOut" 19 "ACComprMngmntInfo_19_BSGRq" 20 "ACComprMngmntInfo_20_Low_Refrigerant" 21 "ACComprMngmntInfo_21_Running_Rpm" 22 "ACComprMngmntInfo_22_Running_not_Ready" 23 "ACComprMngmntInfo_23_Hybrid_Ready" 24 "ACComprMngmntInfo_24_AC_Hybrid_Active_Code" 25 "ACComprMngmntInfo_25_Chiller_and_Evap_Both_Close" 26 "ACComprMngmntInfo_26_Chiller_and_Evap_Both_Offcode" 27 "ACComprMngmntInfo_27_BMS_Chiller_Off_Rq" 28 "ACComprMngmntInfo_28_Battery_Coolant_Pump_Off_and_Chiller_Request_On" 29 "ACComprMngmntInfo_29_Battery_Coolant_Temp_Too_Low" 30 "ACComprMngmntInfo_30_EAC_Error" 31 "ACComprMngmntInfo_31_EAC_Communiation_Error" 32 "ACComprMngmntInfo_32_HV_Not_Ready" 33 "ACComprMngmntInfo_33_Fast_Charing" 34 "ACComprMngmntInfo_34_ECO_On" 35 "ACComprMngmntInfo_35_No_Evap_Cool_Request" 36 "ACComprMngmntInfo_36_Power_limit_EPTACLdAld";
VAL_ 908 HeatPumpErMngmntInfo 0 "HeatPumpErMngmntInfo_0_normal_work" 1 "HeatPumpErMngmntInfo_1_EAC_Pressure_Protection" 2 "HeatPumpErMngmntInfo_2_EAC_temperature_protection" 3 "HeatPumpErMngmntInfo_3_Refrigerant_leak" 4 "HeatPumpErMngmntInfo_4_Low_outside_air" 5 "HeatPumpErMngmntInfo_5_Sensor_Error" 6 "HeatPumpErMngmntInfo_6_Solenoid_Valve_Error" 7 "HeatPumpErMngmntInfo_7_ElecCmpsCtrlVlv_Error" 8 "HeatPumpErMngmntInfo_8_Communicatio_Error" 9 "HeatPumpErMngmntInfo_9_Voltage_Error" 10 "HeatPumpErMngmntInfo_10_HPressure_Protection" 11 "HeatPumpErMngmntInfo_11_LPressure_Protection" 12 "HeatPumpErMngmntInfo_12_TinCompTemp_Protection" 13 "HeatPumpErMngmntInfo_13_ToutCompTemp_Protection" 14 "HeatPumpErMngmntInfo_14_TinCompSH_Protection";
VAL_ 908 HeatPumpMd 0 "HeatPumpMd_0_stop_no_request" 1 "HeatPumpMd_1_Heating" 2 "HeatPumpMd_2_Dehumidification_heating" 3 "HeatPumpMd_3_Dehumidification_cooling" 4 "HeatPumpMd_4_Cooling" 5 "HeatPumpMd_5_Defrost" 6 "HeatPumpMd_6_Only_Battery_Cooling_mode" 7 "HeatPumpMd_7_Battery_Cooling_and_Cabin_Cooling" 8 "HeatPumpMd_8_cabin_cooling_and_battery_cooling" 9 "HeatPumpMd_9_Remote_Air_Condition_Mode" 10 "HeatPumpMd_10_Reserved" 11 "HeatPumpMd_11_WAIT" 12 "HeatPumpMd_12_HPinitialize" 13 "HeatPumpMd_13_self_diagnosis" 14 "HeatPumpMd_14_SLEEP";
VAL_ 908 TDU_ESSPTC_HVIL_St 0 "TDU_ESSPTC_HVIL_St_0_Not_ready" 1 "TDU_ESSPTC_HVIL_St_1_Lock" 2 "TDU_ESSPTC_HVIL_St_2_Unlock" 3 "TDU_ESSPTC_HVIL_St_3_HW_Fault";
VAL_ 908 TDU_ESSTC_HVIL_St 0 "TDU_ESSTC_HVIL_St_0_ESSPTC_HVIL_Sta_0_Initial" 1 "TDU_ESSTC_HVIL_St_1_ESSPTC_HVIL_Sta_1_Normal" 2 "TDU_ESSTC_HVIL_St_2_ESSPTC_HVIL_Sta_2_Fault" 3 "TDU_ESSTC_HVIL_St_3_ESSPTC_HVIL_Sta_3_Short_Circuit";
VAL_ 908 TDU_ExInnerInletTem 4095 "TDU_ExInnerInletTem_4095_Invalid";
VAL_ 908 TDU_ExInnerOutletTem 4095 "TDU_ExInnerOutletTem_4095_Invalid";
VAL_ 908 TDU_LePTCAirOutlT 4095 "TDU_LePTCAirOutlT_4095_Invalid";
VAL_ 908 TDU_LePTCAirOutlTrgtTemp 4095 "TDU_LePTCAirOutlTrgtTemp_4095_Invalid";
VAL_ 908 TDU_OtsdAirTemRaw 4095 "TDU_OtsdAirTemRaw_4095_Invalid";
VAL_ 908 TDU_RiPTCAirOutlT 4095 "TDU_RiPTCAirOutlT_4095_Invalid";
VAL_ 908 TDU_RiPTCAirOutlTrgtTemp 4095 "TDU_RiPTCAirOutlTrgtTemp_4095_Invalid";
VAL_ 908 TDU_TempExclusiveRearFlg 0 "TDU_TempExclusiveRearFlg_0_Initial" 1 "TDU_TempExclusiveRearFlg_1_OFF" 2 "TDU_TempExclusiveRearFlg_2_ON" 3 "TDU_TempExclusiveRearFlg_3_Invalid";
VAL_ 908 TDUEnbPTC 0 "TDUEnbPTC_0_TDUEnbPTC_0_Off" 1 "TDUEnbPTC_1_TDUEnbPTC_1_On";
VAL_ 908 TDUReqMd 0 "TDUReqMd_0_TDUReqMd_0_NoRequest" 1 "TDUReqMd_1_TDUReqMd_1_PowerControl" 2 "TDUReqMd_2_TDUReqMd_2_TapPositionControl" 3 "TDUReqMd_3_TDUReqMd_3_PwmControl";
VAL_ 1329 TDU_HPTSnsrT 4095 "TDU_HPTSnsrT_4095_Invalid";
VAL_ 1329 TDU_LPTSnsrT 4095 "TDU_LPTSnsrT_4095_Invalid";
VAL_ 828 TDU_EvaprTemp 4095 "TDU_EvaprTemp_4095_Invalid";
VAL_ 828 TDU_FEvaprTrgtTemp 4095 "TDU_FEvaprTrgtTemp_4095_Invalid";
VAL_ 828 TDU_LeSunshineSnsrT 2047 "TDU_LeSunshineSnsrT_2047_Invalid";
VAL_ 828 TDU_RiSunshineSnsrT 2047 "TDU_RiSunshineSnsrT_2047_Invalid";
VAL_ 1328 TDU_BattInlT 255 "TDU_BattInlT_255_Invalid";
VAL_ 1328 TDU_BattOutlT 255 "TDU_BattOutlT_255_Invalid";
VAL_ 1328 TDU_HEXInWtrT 255 "TDU_HEXInWtrT_255_Invalid";
VAL_ 1328 TDU_MotInletWaterT 255 "TDU_MotInletWaterT_255_Invalid";
VAL_ 1328 TDU_MotLoopCooltFlow 255 "TDU_MotLoopCooltFlow_255_Invalid";
VAL_ 817 TDU_BattCoolgLoopSts 0 "TDU_BattCoolgLoopSts_0_OFF" 1 "TDU_BattCoolgLoopSts_1_Normal" 2 "TDU_BattCoolgLoopSts_2_Warning" 3 "TDU_BattCoolgLoopSts_3_Failure";
VAL_ 817 TDU_BattModSt 0 "TDU_BattModSt_0_Shutdown" 1 "TDU_BattModSt_1_Average_temperature" 2 "TDU_BattModSt_2_Cooling" 3 "TDU_BattModSt_3_Heating" 4 "TDU_BattModSt_4_Battery_thermal_runaway" 5 "TDU_BattModSt_5_Reserved";
VAL_ 817 TDU_BattThermRunawaySts 0 "TDU_BattThermRunawaySts_0_Not_Active" 1 "TDU_BattThermRunawaySts_1_Active";
VAL_ 817 TDU_BattWrmLoopSts 0 "TDU_BattWrmLoopSts_0_OFF" 1 "TDU_BattWrmLoopSts_1_Normal" 2 "TDU_BattWrmLoopSts_2_Warning" 3 "TDU_BattWrmLoopSts_3_Failure";
VAL_ 817 TDU_CabCoolLoopSts 0 "TDU_CabCoolLoopSts_0_OFF" 1 "TDU_CabCoolLoopSts_1_Normal" 2 "TDU_CabCoolLoopSts_2_Warning" 3 "TDU_CabCoolLoopSts_3_Failure";
VAL_ 817 TDU_CabHeatLoopSts 0 "TDU_CabHeatLoopSts_0_OFF" 1 "TDU_CabHeatLoopSts_1_Normal" 2 "TDU_CabHeatLoopSts_2_Warning" 3 "TDU_CabHeatLoopSts_3_Failure";
VAL_ 817 TDU_CabModSt 0 "TDU_CabModSt_0_Shutdown" 1 "TDU_CabModSt_1_Ventilation" 2 "TDU_CabModSt_2_Cooling" 3 "TDU_CabModSt_3_Heating" 4 "TDU_CabModSt_4_Heating_and_Dehumidification" 5 "TDU_CabModSt_5_Reserved";
VAL_ 817 TDU_FaultLevel 0 "TDU_FaultLevel_0_Normal" 1 "TDU_FaultLevel_1_Level_1" 2 "TDU_FaultLevel_2_Level_2" 3 "TDU_FaultLevel_3_Level_3" 4 "TDU_FaultLevel_4_Level_4" 5 "TDU_FaultLevel_5_Level_5" 6 "TDU_FaultLevel_6_Reserved" 7 "TDU_FaultLevel_7_Reserved";
VAL_ 817 TDU_HeatMngtFctLim 0 "TDU_HeatMngtFctLim_0_Normal" 1 "TDU_HeatMngtFctLim_1_Function_Limited";
VAL_ 817 TDU_HeatMngtSysFlt 0 "TDU_HeatMngtSysFlt_0_Normal" 1 "TDU_HeatMngtSysFlt_1_Fault_(light)";
VAL_ 817 TDU_HEnerConsume 65535 "TDU_HEnerConsume_65535_Invalid";
VAL_ 817 TDU_HVCnctHldReq 0 "TDU_HVCnctHldReq_0_No_Req" 1 "TDU_HVCnctHldReq_1_Req";
VAL_ 817 TDU_HVPwrMaxReq 65535 "TDU_HVPwrMaxReq_65535_Invalid";
VAL_ 817 TDU_HVPwrMinReq 65535 "TDU_HVPwrMinReq_65535_Invalid";
VAL_ 817 TDU_LEnerConsume 1023 "TDU_LEnerConsume_1023_Invalid";
VAL_ 817 TDU_LVPwrMaxReq 65535 "TDU_LVPwrMaxReq_65535_Invalid";
VAL_ 817 TDU_LVPwrMinReq 65535 "TDU_LVPwrMinReq_65535_Invalid";
VAL_ 817 TDU_MotCoolgLoopSts 0 "TDU_MotCoolgLoopSts_0_OFF" 1 "TDU_MotCoolgLoopSts_1_Normal" 2 "TDU_MotCoolgLoopSts_2_Warning" 3 "TDU_MotCoolgLoopSts_3_Failure";
VAL_ 817 TDU_MotHeatPwrAvl 255 "TDU_MotHeatPwrAvl_255_Invalid";
VAL_ 817 TDU_OperMod 0 "TDU_OperMod_0_Initial" 1 "TDU_OperMod_1_Standby" 2 "TDU_OperMod_2_HV_Active" 3 "TDU_OperMod_3_Afterrun" 4 "TDU_OperMod_4_Failure" 5 "TDU_OperMod_5_ReadyToPowerDown" 6 "TDU_OperMod_6_Reserved" 15 "TDU_OperMod_15_ready_to_sleep";
VAL_ 817 TDU_PTCPwrAct 255 "TDU_PTCPwrAct_255_Invalid";
VAL_ 817 TDU_PTCPwrAvl 255 "TDU_PTCPwrAvl_255_Invalid";
VAL_ 817 TDU_PwrModSt 0 "TDU_PwrModSt_0_Shutdown" 1 "TDU_PwrModSt_1_Cooling" 2 "TDU_PwrModSt_2_Heat_pump_absorbs_heat" 3 "TDU_PwrModSt_3_Waste_heat_recovery" 5 "TDU_PwrModSt_5_Reserved";
VAL_ 817 TDU_RefModSt 0 "TDU_RefModSt_0_Shutdown" 1 "TDU_RefModSt_1_Single-air_conditioner_cooling" 2 "TDU_RefModSt_2_Single_air_conditioner_heat_pump_heating_(WTC_allowed)" 3 "TDU_RefModSt_3_Single_air_conditioner_heating_and_dehumidification_(refrigerant_waste_heat_and_WTC)" 4 "TDU_RefModSt_4_Single-battery_cooling" 5 "TDU_RefModSt_5_Air_conditioner_battery_hybrid_cooling" 6 "TDU_RefModSt_6_Battery-cooled_air_conditioner_WTC_heating_(including_refrigerant_waste_heat)" 7 "TDU_RefModSt_7_WTC_heating_of_the_air_conditioner_battery_mixed_cooling_and_heating_core_(including_the_residual_heat_of_the_refrigerant)" 8 "TDU_RefModSt_8_Single-battery_heat_pump_heating_(WTC_allowed)" 9 "TDU_RefModSt_9_Air_conditioner_cooling_battery_WTC_heating_(including_refrigerant_waste_heat)" 10 "TDU_RefModSt_10_Air_conditioner_battery_heat_pump_hybrid_heating_(refrigerant_waste_heat_and_WTC)" 11 "TDU_RefModSt_11_Dual_heating_of_the_cooling_and_heating_core_of_the_air_conditioner_and_the_battery_WTC_(including_the_residual_heat_of_the_refrigerant)" 12 "TDU_RefModSt_12_Single_air_conditioner_heat_pump_and_dehumidification" 13 "TDU_RefModSt_13_Air_conditioner_heat_pump_and_dehumidification_and_battery_heat_pump" 14 "TDU_RefModSt_14_Reserved";
VAL_ 817 TDU_SafteyModSts 0 "TDU_SafteyModSts_0_Not_active" 1 "TDU_SafteyModSts_1_Acitve";
VAL_ 817 TDU_SilentCoolgErrWakeup 0 "TDU_SilentCoolgErrWakeup_0_Inactive" 1 "TDU_SilentCoolgErrWakeup_1_Active";
VAL_ 817 TDU_SilentCoolgSts 0 "TDU_SilentCoolgSts_0_Initial" 1 "TDU_SilentCoolgSts_1_ON" 2 "TDU_SilentCoolgSts_2_OFF" 3 "TDU_SilentCoolgSts_3_Reserved";
VAL_ 817 TDU_WakeupHldReq 0 "TDU_WakeupHldReq_0_No_Req" 1 "TDU_WakeupHldReq_1_Req";
VAL_ 1333 TDU_EXVB_ActOpenVal 65535 "TDU_EXVB_ActOpenVal_65535_Invalid";
VAL_ 1333 TDU_EXVB_InitSts 0 "TDU_EXVB_InitSts_0_Not_Initialized" 1 "TDU_EXVB_InitSts_1_Initialization_in_Process" 2 "TDU_EXVB_InitSts_2_Initialized" 3 "TDU_EXVB_InitSts_3_Invalid";
VAL_ 1333 TDU_EXVB_Sts 0 "TDU_EXVB_Sts_0_Actuator_is_not_moving" 1 "TDU_EXVB_Sts_1_Actuator_is_moving";
VAL_ 1333 TDU_EXVH_ActOpenVal 65535 "TDU_EXVH_ActOpenVal_65535_Invalid";
VAL_ 1333 TDU_EXVH_InitSts 0 "TDU_EXVH_InitSts_0_Not_Initialized" 1 "TDU_EXVH_InitSts_1_Initialization_in_Process" 2 "TDU_EXVH_InitSts_2_Initialized" 3 "TDU_EXVH_InitSts_3_Invalid";
VAL_ 1333 TDU_EXVH_Sts 0 "TDU_EXVH_Sts_0_Actuator_is_not_moving" 1 "TDU_EXVH_Sts_1_Actuator_is_moving";
VAL_ 818 TDU_EAS_CrtPwr 65535 "TDU_EAS_CrtPwr_65535_Invalid";
VAL_ 818 TDU_EAS_CrtSts 0 "TDU_EAS_CrtSts_0_Standby" 1 "TDU_EAS_CrtSts_1_Work" 2 "TDU_EAS_CrtSts_2_Fault" 3 "TDU_EAS_CrtSts_3_Reserved";
VAL_ 818 TDU_EAS_HVIL_St 0 "TDU_EAS_HVIL_St_0_Not_ready" 1 "TDU_EAS_HVIL_St_1_Lock" 2 "TDU_EAS_HVIL_St_2_Unlock" 3 "TDU_EAS_HVIL_St_3_HW_Fault";
VAL_ 818 TDU_WTC_H_ActGear 0 "TDU_WTC_H_ActGear_0_0" 1 "TDU_WTC_H_ActGear_1_1" 2 "TDU_WTC_H_ActGear_2_2" 3 "TDU_WTC_H_ActGear_3_3" 4 "TDU_WTC_H_ActGear_4_4" 5 "TDU_WTC_H_ActGear_5_5" 6 "TDU_WTC_H_ActGear_6_6" 7 "TDU_WTC_H_ActGear_7_7" 8 "TDU_WTC_H_ActGear_8_8" 9 "TDU_WTC_H_ActGear_9_9" 10 "TDU_WTC_H_ActGear_10_10" 11 "TDU_WTC_H_ActGear_11_11" 12 "TDU_WTC_H_ActGear_12_12" 13 "TDU_WTC_H_ActGear_13_13" 14 "TDU_WTC_H_ActGear_14_14" 15 "TDU_WTC_H_ActGear_15_15" 16 "TDU_WTC_H_ActGear_16_16" 17 "TDU_WTC_H_ActGear_17_reserved";
VAL_ 818 TDU_WTC_H_CrtPwr 65535 "TDU_WTC_H_CrtPwr_65535_Invalid";
VAL_ 818 TDU_WTC_H_CrtSts 0 "TDU_WTC_H_CrtSts_0_Standby" 1 "TDU_WTC_H_CrtSts_1_Gear_control_working_mode" 2 "TDU_WTC_H_CrtSts_2_Power_control_working_mode" 3 "TDU_WTC_H_CrtSts_3_Discharge_mode" 4 "TDU_WTC_H_CrtSts_4_Fault" 5 "TDU_WTC_H_CrtSts_5_reserved";
VAL_ 818 TDU_WTC_H_CrtTemp 255 "TDU_WTC_H_CrtTemp_255_Invalid";
VAL_ 818 TDU_WTC_H_Currt 65535 "TDU_WTC_H_Currt_65535_Invalid";
VAL_ 818 TDU_WTC_H_InpTemp 255 "TDU_WTC_H_InpTemp_255_Invalid";
VAL_ 818 TDU_WTC_H_OutpTemp 255 "TDU_WTC_H_OutpTemp_255_Invalid";
VAL_ 818 TDU_WTC_H_PCBTemp 255 "TDU_WTC_H_PCBTemp_255_Invalid";
VAL_ 818 TDU_WTC_H_TarOutpTemp 255 "TDU_WTC_H_TarOutpTemp_255_Invalid";
VAL_ 818 TDU_WTC_HVIL_St 0 "TDU_WTC_HVIL_St_0_Not_ready" 1 "TDU_WTC_HVIL_St_1_Lock" 2 "TDU_WTC_HVIL_St_2_Unlock" 3 "TDU_WTC_HVIL_St_3_HW_Fault";
VAL_ 582 VDC_DrvrDoorLockSt 0 "VDC_DrvrDoorLockSt_0_Initial" 1 "VDC_DrvrDoorLockSt_1_Unlocked" 2 "VDC_DrvrDoorLockSt_2_Locked" 3 "VDC_DrvrDoorLockSt_3_Invalid";
VAL_ 582 VDC_DrvrDoorLockStVld 0 "VDC_DrvrDoorLockStVld_0_Invalid" 1 "VDC_DrvrDoorLockStVld_1_Valid";
VAL_ 582 VDC_DrvrDoorSt 0 "VDC_DrvrDoorSt_0_Initial" 1 "VDC_DrvrDoorSt_1_Closed" 2 "VDC_DrvrDoorSt_2_Opened" 3 "VDC_DrvrDoorSt_3_Invalid";
VAL_ 582 VDC_DrvrDoorStValid 0 "VDC_DrvrDoorStValid_0_Invalid" 1 "VDC_DrvrDoorStValid_1_Valid";
VAL_ 582 VDC_HoodSts 0 "VDC_HoodSts_0_Initial" 1 "VDC_HoodSts_1_Closed" 2 "VDC_HoodSts_2_Opened" 3 "VDC_HoodSts_3_Invalid";
VAL_ 582 VDC_PassDoorLockSt 0 "VDC_PassDoorLockSt_0_Initial" 1 "VDC_PassDoorLockSt_1_Unlocked" 2 "VDC_PassDoorLockSt_2_Locked" 3 "VDC_PassDoorLockSt_3_Invalid";
VAL_ 582 VDC_PassDoorSt 0 "VDC_PassDoorSt_0_Initial" 1 "VDC_PassDoorSt_1_Closed" 2 "VDC_PassDoorSt_2_Opened" 3 "VDC_PassDoorSt_3_Invalid";
VAL_ 582 VDC_RLDoorLockSt 0 "VDC_RLDoorLockSt_0_Initial" 1 "VDC_RLDoorLockSt_1_Unlocked" 2 "VDC_RLDoorLockSt_2_Locked" 3 "VDC_RLDoorLockSt_3_Invalid";
VAL_ 582 VDC_RLDoorSt 0 "VDC_RLDoorSt_0_Initial" 1 "VDC_RLDoorSt_1_Closed" 2 "VDC_RLDoorSt_2_Opened" 3 "VDC_RLDoorSt_3_Invalid";
VAL_ 582 VDC_RRDoorLockSt 0 "VDC_RRDoorLockSt_0_Initial" 1 "VDC_RRDoorLockSt_1_Unlocked" 2 "VDC_RRDoorLockSt_2_Locked" 3 "VDC_RRDoorLockSt_3_Invalid";
VAL_ 582 VDC_RRDoorSt 0 "VDC_RRDoorSt_0_Initial" 1 "VDC_RRDoorSt_1_Closed" 2 "VDC_RRDoorSt_2_Opened" 3 "VDC_RRDoorSt_3_Invalid";
VAL_ 582 VDC_TailgateSt 0 "VDC_TailgateSt_0_Initial" 1 "VDC_TailgateSt_1_closed" 2 "VDC_TailgateSt_2_opened" 3 "VDC_TailgateSt_3_closeing" 4 "VDC_TailgateSt_4_opening" 5 "VDC_TailgateSt_5_stop" 6 "VDC_TailgateSt_6_Closed_Not_Completely（半锁）" 7 "VDC_TailgateSt_7_locking" 8 "VDC_TailgateSt_8_unlocking" 9 "VDC_TailgateSt_9_Reserved" 15 "VDC_TailgateSt_15_Invalid";
VAL_ 798 VDC_DriverSeatOccptSt 0 "VDC_DriverSeatOccptSt_0_Initial" 1 "VDC_DriverSeatOccptSt_1_Free" 2 "VDC_DriverSeatOccptSt_2_Occupied" 3 "VDC_DriverSeatOccptSt_3_Invalid";
VAL_ 798 VDC_PassSeatOccptSt 0 "VDC_PassSeatOccptSt_0_Initial" 1 "VDC_PassSeatOccptSt_1_Free" 2 "VDC_PassSeatOccptSt_2_Occupied" 3 "VDC_PassSeatOccptSt_3_Invalid";
VAL_ 798 VDC_RLSecRowSeatOccptSt 0 "VDC_RLSecRowSeatOccptSt_0_Initial" 1 "VDC_RLSecRowSeatOccptSt_1_Free" 2 "VDC_RLSecRowSeatOccptSt_2_Occupied" 3 "VDC_RLSecRowSeatOccptSt_3_Invalid";
VAL_ 798 VDC_RMSecRowSeatOccptSt 0 "VDC_RMSecRowSeatOccptSt_0_Initial" 1 "VDC_RMSecRowSeatOccptSt_1_Free" 2 "VDC_RMSecRowSeatOccptSt_2_Occupied" 3 "VDC_RMSecRowSeatOccptSt_3_Invalid";
VAL_ 798 VDC_RRSecRowSeatOccptSt 0 "VDC_RRSecRowSeatOccptSt_0_Initial" 1 "VDC_RRSecRowSeatOccptSt_1_Free" 2 "VDC_RRSecRowSeatOccptSt_2_Occupied" 3 "VDC_RRSecRowSeatOccptSt_3_Invalid";
VAL_ 819 VDC_CDC_ACECOModReq 0 "VDC_CDC_ACECOModReq_0_NO_Request" 1 "VDC_CDC_ACECOModReq_1_OFF" 2 "VDC_CDC_ACECOModReq_2_ON" 3 "VDC_CDC_ACECOModReq_3_Reserved";
VAL_ 819 VDC_CDC_ACFourZoneSync 0 "VDC_CDC_ACFourZoneSync_0_NO_Request" 1 "VDC_CDC_ACFourZoneSync_1_OFF" 2 "VDC_CDC_ACFourZoneSync_2_ON" 3 "VDC_CDC_ACFourZoneSync_3_Reserved";
VAL_ 819 VDC_CDC_ACMaxSet 0 "VDC_CDC_ACMaxSet_0_NO_Request" 1 "VDC_CDC_ACMaxSet_1_OFF" 2 "VDC_CDC_ACMaxSet_2_ON" 3 "VDC_CDC_ACMaxSet_3_Reserved";
VAL_ 819 VDC_CDC_ACParkAutoVentSet 0 "VDC_CDC_ACParkAutoVentSet_0_NO_Request" 1 "VDC_CDC_ACParkAutoVentSet_1_OFF" 2 "VDC_CDC_ACParkAutoVentSet_2_ON" 3 "VDC_CDC_ACParkAutoVentSet_3_Reserved";
VAL_ 819 VDC_CDC_ACSet 0 "VDC_CDC_ACSet_0_NO_Request" 1 "VDC_CDC_ACSet_1_OFF" 2 "VDC_CDC_ACSet_2_ON" 3 "VDC_CDC_ACSet_3_Reserved";
VAL_ 819 VDC_CDC_ACSystemOnOffSet 0 "VDC_CDC_ACSystemOnOffSet_0_NO_Request" 1 "VDC_CDC_ACSystemOnOffSet_1_OFF" 2 "VDC_CDC_ACSystemOnOffSet_2_ON" 3 "VDC_CDC_ACSystemOnOffSet_3_Reserved";
VAL_ 819 VDC_CDC_AutoDefogSet 0 "VDC_CDC_AutoDefogSet_0_NO_Request" 1 "VDC_CDC_AutoDefogSet_1_OFF" 2 "VDC_CDC_AutoDefogSet_2_ON" 3 "VDC_CDC_AutoDefogSet_3_Reserved";
VAL_ 819 VDC_CDC_AutoDrySet 0 "VDC_CDC_AutoDrySet_0_NO_Request" 1 "VDC_CDC_AutoDrySet_1_OFF" 2 "VDC_CDC_AutoDrySet_2_ON" 3 "VDC_CDC_AutoDrySet_3_Reserved";
VAL_ 819 VDC_CDC_CircModSet 0 "VDC_CDC_CircModSet_0_NO_Request" 1 "VDC_CDC_CircModSet_1_Internal" 2 "VDC_CDC_CircModSet_2_External" 3 "VDC_CDC_CircModSet_3_Auto";
VAL_ 819 VDC_CDC_DriverTempSet 0 "VDC_CDC_DriverTempSet_0_NO_Request" 63 "VDC_CDC_DriverTempSet_63_Invalid";
VAL_ 819 VDC_CDC_FHvacBlowLvSet 0 "VDC_CDC_FHvacBlowLvSet_0_No_Request" 1 "VDC_CDC_FHvacBlowLvSet_1_Level_1" 2 "VDC_CDC_FHvacBlowLvSet_2_Level_2" 3 "VDC_CDC_FHvacBlowLvSet_3_Level_3" 4 "VDC_CDC_FHvacBlowLvSet_4_Level_4" 5 "VDC_CDC_FHvacBlowLvSet_5_Level_5" 6 "VDC_CDC_FHvacBlowLvSet_6_Level_6" 7 "VDC_CDC_FHvacBlowLvSet_7_Level_7" 8 "VDC_CDC_FHvacBlowLvSet_8_Level_8" 9 "VDC_CDC_FHvacBlowLvSet_9_Level_9" 10 "VDC_CDC_FHvacBlowLvSet_10_Level_10(Reserved)" 11 "VDC_CDC_FHvacBlowLvSet_11_OFF" 12 "VDC_CDC_FHvacBlowLvSet_12_Reserved";
VAL_ 819 VDC_CDC_FHvacModeSet 0 "VDC_CDC_FHvacModeSet_0_NO_Request" 1 "VDC_CDC_FHvacModeSet_1_BlowFace" 2 "VDC_CDC_FHvacModeSet_2_BlowFace_&_Foot" 3 "VDC_CDC_FHvacModeSet_3_BlowFoot" 4 "VDC_CDC_FHvacModeSet_4_BlowFoot_&_Windows" 5 "VDC_CDC_FHvacModeSet_5_BlowWindows" 6 "VDC_CDC_FHvacModeSet_6_BlowFace_&_Windows" 7 "VDC_CDC_FHvacModeSet_7_BlowFace_&_Foot_&_Windows" 8 "VDC_CDC_FHvacModeSet_8_OFF" 9 "VDC_CDC_FHvacModeSet_9_Reserved" 15 "VDC_CDC_FHvacModeSet_15_Reserved";
VAL_ 819 VDC_CDC_FrontDefrostSet 0 "VDC_CDC_FrontDefrostSet_0_NO_Request" 1 "VDC_CDC_FrontDefrostSet_1_OFF" 2 "VDC_CDC_FrontDefrostSet_2_ON" 3 "VDC_CDC_FrontDefrostSet_3_Reserved";
VAL_ 819 VDC_CDC_HeatMaxSet 0 "VDC_CDC_HeatMaxSet_0_NO_Request" 1 "VDC_CDC_HeatMaxSet_1_OFF" 2 "VDC_CDC_HeatMaxSet_2_ON" 3 "VDC_CDC_HeatMaxSet_3_Reserved";
VAL_ 819 VDC_CDC_HvacAutoModeSet 0 "VDC_CDC_HvacAutoModeSet_0_NO_Request" 1 "VDC_CDC_HvacAutoModeSet_1_OFF" 2 "VDC_CDC_HvacAutoModeSet_2_ON" 3 "VDC_CDC_HvacAutoModeSet_3_Reserved";
VAL_ 819 VDC_CDC_PassengerTempSet 0 "VDC_CDC_PassengerTempSet_0_NO_Request" 63 "VDC_CDC_PassengerTempSet_63_Invalid";
VAL_ 819 VDC_CDC_RACSystemOnOffSet 0 "VDC_CDC_RACSystemOnOffSet_0_NO_Request" 1 "VDC_CDC_RACSystemOnOffSet_1_OFF" 2 "VDC_CDC_RACSystemOnOffSet_2_ON" 3 "VDC_CDC_RACSystemOnOffSet_3_Reserved";
VAL_ 819 VDC_CDC_SceneModPwrOnSts 0 "VDC_CDC_SceneModPwrOnSts_0_INVALID" 1 "VDC_CDC_SceneModPwrOnSts_1_ON" 2 "VDC_CDC_SceneModPwrOnSts_2_ON_REMOTE" 3 "VDC_CDC_SceneModPwrOnSts_3_OFF";
VAL_ 819 VDC_CDC_SupCoolingModSet 0 "VDC_CDC_SupCoolingModSet_0_NO_Request" 1 "VDC_CDC_SupCoolingModSet_1_OFF" 2 "VDC_CDC_SupCoolingModSet_2_ON" 3 "VDC_CDC_SupCoolingModSet_3_Reserved";
VAL_ 819 VDC_CDC_TempExclusive 0 "VDC_CDC_TempExclusive_0_NO_Request" 1 "VDC_CDC_TempExclusive_1_OFF" 2 "VDC_CDC_TempExclusive_2_ON" 3 "VDC_CDC_TempExclusive_3_Reserved";
VAL_ 819 VDC_CDC_VentSet 0 "VDC_CDC_VentSet_0_NO_Request" 1 "VDC_CDC_VentSet_1_OFF" 2 "VDC_CDC_VentSet_2_ON" 3 "VDC_CDC_VentSet_3_Reserved";
VAL_ 289 VDC_CoordiRespondSt 0 "VDC_CoordiRespondSt_0_No_Respond" 1 "VDC_CoordiRespondSt_1_Respond";
VAL_ 289 VDC_DrvgCyc 0 "VDC_DrvgCyc_0_NOT_ACHIEVED" 1 "VDC_DrvgCyc_1_ACHIEVED";
VAL_ 289 VDC_EngCrankReq 0 "VDC_EngCrankReq_0_Not_Start" 1 "VDC_EngCrankReq_1_Start";
VAL_ 289 VDC_EngCtrlSt 0 "VDC_EngCtrlSt_0_Initial" 1 "VDC_EngCtrlSt_1_EngNotReady" 2 "VDC_EngCtrlSt_2_EngReady" 3 "VDC_EngCtrlSt_3_Starting" 4 "VDC_EngCtrlSt_4_Generating" 5 "VDC_EngCtrlSt_5_Idling" 6 "VDC_EngCtrlSt_6_Cranking" 7 "VDC_EngCtrlSt_7_Stopping" 8 "VDC_EngCtrlSt_8_Reserved";
VAL_ 289 VDC_EngMaxSpdLim 8191 "VDC_EngMaxSpdLim_8191_Invalid";
VAL_ 289 VDC_EngRampEna 0 "VDC_EngRampEna_0_Disable(No_Ramp_Request)" 1 "VDC_EngRampEna_1_Enable(Ramp)";
VAL_ 289 VDC_EngReadySt 0 "VDC_EngReadySt_0_Not_Ready" 1 "VDC_EngReadySt_1_Ready";
VAL_ 289 VDC_EngStartMod 0 "VDC_EngStartMod_0_No_Start" 1 "VDC_EngStartMod_1_Normal_Start" 2 "VDC_EngStartMod_2_IGN_Start" 3 "VDC_EngStartMod_3_None";
VAL_ 289 VDC_EngStartReq 0 "VDC_EngStartReq_0_No_Start" 1 "VDC_EngStartReq_1_Start";
VAL_ 289 VDC_EngStopReq 0 "VDC_EngStopReq_0_No_Stop" 1 "VDC_EngStopReq_1_Stop";
VAL_ 289 VDC_EngStrtFuInjInhb 0 "VDC_EngStrtFuInjInhb_0_Injection_Allowed" 1 "VDC_EngStrtFuInjInhb_1_Injection_Inhibition";
VAL_ 289 VDC_EngTqResv 2047 "VDC_EngTqResv_2047_Invalid";
VAL_ 289 VDC_FlyWhFastTqReqVld 0 "VDC_FlyWhFastTqReqVld_0_Invalid" 1 "VDC_FlyWhFastTqReqVld_1_Valid";
VAL_ 289 VDC_FlyWhSlowTqReqVld 0 "VDC_FlyWhSlowTqReqVld_0_Invalid" 1 "VDC_FlyWhSlowTqReqVld_1_Valid";
VAL_ 289 VDC_FuelChargeStatus 0 "VDC_FuelChargeStatus_0_NO_REQUEST" 1 "VDC_FuelChargeStatus_1_HIGH_LEVEL" 2 "VDC_FuelChargeStatus_2_MIDDLE_LEVEL" 3 "VDC_FuelChargeStatus_3_LOW_LEVEL";
VAL_ 289 VDC_FuelChargeSwitch 0 "VDC_FuelChargeSwitch_0_OFF" 1 "VDC_FuelChargeSwitch_1_ON";
VAL_ 289 VDC_FuelCutOffReq 0 "VDC_FuelCutOffReq_0_No_request" 1 "VDC_FuelCutOffReq_1_Request";
VAL_ 289 VDC_FueldetectionStatus 0 "VDC_FueldetectionStatus_0_NO_REQUEST" 1 "VDC_FueldetectionStatus_1_LOW_LEVEL" 2 "VDC_FueldetectionStatus_2_HIGH_LEVEL" 3 "VDC_FueldetectionStatus_3_Reserved";
VAL_ 289 VDC_FueldetectionSwitch 0 "VDC_FueldetectionSwitch_0_OFF" 1 "VDC_FueldetectionSwitch_1_ON";
VAL_ 289 VDC_FuelRemaining 255 "VDC_FuelRemaining_255_Invalid";
VAL_ 289 VDC_FuelRemainingVld 0 "VDC_FuelRemainingVld_0_Invalid" 1 "VDC_FuelRemainingVld_1_Valid";
VAL_ 289 VDC_FuelRemainingVol 16383 "VDC_FuelRemainingVol_16383_Invalid";
VAL_ 289 VDC_GenStableTqAdpSt 0 "VDC_GenStableTqAdpSt_0_Not_Stable" 1 "VDC_GenStableTqAdpSt_1_Stable";
VAL_ 289 VDC_IdleChrgActvReq 0 "VDC_IdleChrgActvReq_0_Not_Actived" 1 "VDC_IdleChrgActvReq_1_Actived";
VAL_ 289 VDC_IdleChrgFlyWhlLoadTqVld 0 "VDC_IdleChrgFlyWhlLoadTqVld_0_Invalid" 1 "VDC_IdleChrgFlyWhlLoadTqVld_1_Valid";
VAL_ 289 VDC_IdleChrgSpdReqVld 0 "VDC_IdleChrgSpdReqVld_0_Invalid" 1 "VDC_IdleChrgSpdReqVld_1_Valid";
VAL_ 289 VDC_IdleCtrlReq 0 "VDC_IdleCtrlReq_0_No_Request" 1 "VDC_IdleCtrlReq_1_Request";
VAL_ 289 VDC_IdleLoadTqVld 0 "VDC_IdleLoadTqVld_0_Invalid" 1 "VDC_IdleLoadTqVld_1_Valid";
VAL_ 289 VDC_IgAglRlsActvSts 0 "VDC_IgAglRlsActvSts_0_Deactive" 1 "VDC_IgAglRlsActvSts_1_Active";
VAL_ 289 VDC_IgnCyc 0 "VDC_IgnCyc_0_NOT_ACHIEVED" 1 "VDC_IgnCyc_1_ACHIEVED";
VAL_ 289 VDC_MILReq 0 "VDC_MILReq_0_No_Request" 1 "VDC_MILReq_1_Request_On";
VAL_ 289 VDC_OBDFaultExistSts 0 "VDC_OBDFaultExistSts_0_No_OBD_Fault" 1 "VDC_OBDFaultExistSts_1_OBD_Fault";
VAL_ 289 VDC_REVMod 0 "VDC_REVMod_0_Electric_Priority纯电优先" 1 "VDC_REVMod_1_Auto自动" 2 "VDC_REVMod_2_Fuel_Priority_Standard燃油优先-标准" 3 "VDC_REVMod_3_Fuel_Test燃油检测" 4 "VDC_REVMod_4_Electric_Only强制纯电" 5 "VDC_REVMod_5_Fuel_Priority_Saving燃油优先-节油" 6 "VDC_REVMod_6_Reserved";
VAL_ 289 VDC_TarIdleSpdReqVld 0 "VDC_TarIdleSpdReqVld_0_Invalid" 1 "VDC_TarIdleSpdReqVld_1_Valid";
VAL_ 289 VDC_WarmupCyc 0 "VDC_WarmupCyc_0_NOT_ACHIEVED" 1 "VDC_WarmupCyc_1_ACHIEVED";
VAL_ 1408 VDC_ChrgPostCurrent 1023 "VDC_ChrgPostCurrent_1023_Invalid";
VAL_ 1408 VDC_ChrgPostPwr 8191 "VDC_ChrgPostPwr_8191_Invalid";
VAL_ 1408 VDC_CLTCRang 2047 "VDC_CLTCRang_2047_Invalid";
VAL_ 1408 VDC_CompositeRang_VV01 2047 "VDC_CompositeRang_2047_Invalid";
VAL_ 1408 VDC_EngyAfAvgLastChrg 2047 "VDC_EngyAfAvgLastChrg_2047_Invalid";
VAL_ 1408 VDC_EngyAfLastChrg 2047 "VDC_EngyAfLastChrg_2047_Invalid";
VAL_ 1408 VDC_EngyAvgRstA 2047 "VDC_EngyAvgRstA_2047_Invalid";
VAL_ 1408 VDC_EngyAvgRstB 2047 "VDC_EngyAvgRstB_2047_Invalid";
VAL_ 1408 VDC_EngyDrvAvePerKm 2047 "VDC_EngyDrvAvePerKm_2047_Invalid";
VAL_ 1408 VDC_EngyRegenPerKm 1023 "VDC_EngyRegenPerKm_1023_Invalid";
VAL_ 1408 VDC_EngyRstA 16383 "VDC_EngyRstA_16383_Invalid";
VAL_ 1408 VDC_EngyRstB 16383 "VDC_EngyRstB_16383_Invalid";
VAL_ 1408 VDC_EngytotalCurCyc 2047 "VDC_EngytotalCurCyc_2047_Invalid";
VAL_ 1408 VDC_EngyTotalRegen 65535 "VDC_EngyTotalRegen_65535_Invalid";
VAL_ 1408 VDC_EstimdArrivalDst 65535 "VDC_EstimdArrivalDst_65535_Invalid";
VAL_ 1408 VDC_EstimdArrivalSOC 1023 "VDC_EstimdArrivalSOC_1023_Invalid";
VAL_ 1408 VDC_EstimdArrivalTi 1023 "VDC_EstimdArrivalTi_1023_Invalid";
VAL_ 1408 VDC_HeatEngy 65535 "VDC_HeatEngy_65535_Invalid";
VAL_ 1408 VDC_RangAfLastChrg 32767 "VDC_RangAfLastChrg_32767_Invalid";
VAL_ 1408 VDC_RangChrgSet 1023 "VDC_RangChrgSet_1023_Invalid";
VAL_ 1408 VDC_RangeRstSetSt 1 "VDC_RangeRstSetSt_1_mileage_A_reset" 2 "VDC_RangeRstSetSt_2_mileage_B_reset" 3 "VDC_RangeRstSetSt_3_Reserved" 4 "VDC_RangeRstSetSt_4_Current_driving_cycle_reset" 5 "VDC_RangeRstSetSt_5_Reserved";
VAL_ 1408 VDC_RangRstA 32767 "VDC_RangRstA_32767_Invalid";
VAL_ 1408 VDC_RangRstB 32767 "VDC_RangRstB_32767_Invalid";
VAL_ 1408 VDC_RatRegen 255 "VDC_RatRegen_255_Invalid";
VAL_ 1408 VDC_RMotPwr 16383 "VDC_RMotPwr_16383_Invalid";
VAL_ 1408 VDC_TotalRang_VV01 1048575 "VDC_TotalRang_1048575_Invalid";
VAL_ 848 VDC_GCUPowergenerationstatus 0 "VDC_GCUPowergenerationstatus_0_NEUTRAL" 1 "VDC_GCUPowergenerationstatus_1_electricity_generation" 2 "VDC_GCUPowergenerationstatus_2_consume_power" 3 "VDC_GCUPowergenerationstatus_3_invalid";
VAL_ 384 VDC_GMotActvDampReq 0 "VDC_GMotActvDampReq_0_OFF" 1 "VDC_GMotActvDampReq_1_ON";
VAL_ 384 VDC_GMotEna 0 "VDC_GMotEna_0_Disable" 1 "VDC_GMotEna_1_Enable";
VAL_ 384 VDC_GMotModReq 0 "VDC_GMotModReq_0_Initial初始化" 1 "VDC_GMotModReq_1_LVStandby低压待机" 2 "VDC_GMotModReq_2_HVStandby高压待机" 3 "VDC_GMotModReq_3_TorqueMode转矩模式" 4 "VDC_GMotModReq_4_SpeedMode转速模式" 5 "VDC_GMotModReq_5_Reserved" 8 "VDC_GMotModReq_8_DisCharging主动放电" 9 "VDC_GMotModReq_9_VoltageClosedLoop电压闭环" 10 "VDC_GMotModReq_10_Reserved";
VAL_ 384 VDC_GMotSpdReq 65535 "VDC_GMotSpdReq_65535_Invalid";
VAL_ 384 VDC_GMotTqReq 65535 "VDC_GMotTqReq_65535_Invalid";
VAL_ 384 VDC_MaxEleTqLim 4095 "VDC_MaxEleTqLim_4095_Invalid";
VAL_ 384 VDC_MaxGenTqLim 4095 "VDC_MaxGenTqLim_4095_Invalid";
VAL_ 385 VDC_ACChrgAllwdSts 0 "VDC_ACChrgAllwdSts_0_Not_Allow" 1 "VDC_ACChrgAllwdSts_1_Allow";
VAL_ 385 VDC_BMSHVConsumePower 255 "VDC_BMSHVConsumePower_255_Invalid";
VAL_ 385 VDC_ChrgAlld 0 "VDC_ChrgAlld_0_Not_Allowed" 1 "VDC_ChrgAlld_1_Allowed";
VAL_ 385 VDC_ChrgPilePowerSupplyAllow 0 "VDC_ChrgPilePowerSupplyAllow_0_Not_Allowed" 1 "VDC_ChrgPilePowerSupplyAllow_1_Allowed";
VAL_ 385 VDC_ChrgPortLockSt 0 "VDC_ChrgPortLockSt_0_Unlocked" 1 "VDC_ChrgPortLockSt_1_Locked" 2 "VDC_ChrgPortLockSt_2_Abnormal" 3 "VDC_ChrgPortLockSt_3_Init";
VAL_ 385 VDC_ChrgStopType 0 "VDC_ChrgStopType_0_Initial" 1 "VDC_ChrgStopType_1_Complate" 2 "VDC_ChrgStopType_2_Fault" 3 "VDC_ChrgStopType_3_Reserved";
VAL_ 385 VDC_ChrgTrgtSOC 127 "VDC_ChrgTrgtSOC_127_Invalid";
VAL_ 385 VDC_DCBoostChrgAllwdSts 0 "VDC_DCBoostChrgAllwdSts_0_Not_Allow" 1 "VDC_DCBoostChrgAllwdSts_1_Allow";
VAL_ 385 VDC_DCChrgAllwd 0 "VDC_DCChrgAllwd_0_Initial" 1 "VDC_DCChrgAllwd_1_Allowed" 2 "VDC_DCChrgAllwd_2_Emergency_not_Allowed" 3 "VDC_DCChrgAllwd_3_Charge_over_Temp_not_Allowed" 4 "VDC_DCChrgAllwd_4_Reserved" 5 "VDC_DCChrgAllwd_5_Fault_not_Allowed" 6 "VDC_DCChrgAllwd_6_Insulation_Fault_not_Allowed" 7 "VDC_DCChrgAllwd_7_Reserved" 8 "VDC_DCChrgAllwd_8_User_not_Allowed" 9 "VDC_DCChrgAllwd_9_Scenario_not_Allowed" 10 "VDC_DCChrgAllwd_10_Not_Parked_not_Allowed" 11 "VDC_DCChrgAllwd_11_Reserved" 15 "VDC_DCChrgAllwd_15_Invalid";
VAL_ 385 VDC_DCDCEnableCmd 0 "VDC_DCDCEnableCmd_0_Disable" 1 "VDC_DCDCEnableCmd_1_Enable" 2 "VDC_DCDCEnableCmd_2_Reserved";
VAL_ 385 VDC_DCDCMaxCurrtAlld 1023 "VDC_DCDCMaxCurrtAlld_1023_Invalid";
VAL_ 385 VDC_DCDCMaxPwrAlld 255 "VDC_DCDCMaxPwrAlld_255_Invalid";
VAL_ 385 VDC_DCDCSetVolt 255 "VDC_DCDCSetVolt_255_Invalid";
VAL_ 385 VDC_DchaAllwdSts 0 "VDC_DchaAllwdSts_0_Not_Allow" 1 "VDC_DchaAllwdSts_1_Allow";
VAL_ 385 VDC_DchaStopType 0 "VDC_DchaStopType_0_Initial" 1 "VDC_DchaStopType_1_Complete" 2 "VDC_DchaStopType_2_Fault" 3 "VDC_DchaStopType_3_Reserved";
VAL_ 385 VDC_ExtrLoTMod 0 "VDC_ExtrLoTMod_0_No_ExtrLoTMod" 1 "VDC_ExtrLoTMod_1_ExtrLoTMod" 2 "VDC_ExtrLoTMod_2_ExtrLoTHeatMod" 3 "VDC_ExtrLoTMod_3_Invalid";
VAL_ 385 VDC_HeatMod 0 "VDC_HeatMod_0_Disable" 1 "VDC_HeatMod_1_ChargeFisrt" 2 "VDC_HeatMod_2_HeatFisrt" 3 "VDC_HeatMod_3_Reserved";
VAL_ 385 VDC_HVBattHVONCmd 0 "VDC_HVBattHVONCmd_0_Reserved" 1 "VDC_HVBattHVONCmd_1_Standby_NoRequest" 2 "VDC_HVBattHVONCmd_2_PowerOn" 3 "VDC_HVBattHVONCmd_3_PowerDown" 4 "VDC_HVBattHVONCmd_4_PreHeat_(Reserved)" 5 "VDC_HVBattHVONCmd_5_EmergencyPowerDown_(Reserved)" 6 "VDC_HVBattHVONCmd_6_Reserved" 7 "VDC_HVBattHVONCmd_7_Sleep" 8 "VDC_HVBattHVONCmd_8_Reserved";
VAL_ 385 VDC_NavChrgThermReq 0 "VDC_NavChrgThermReq_0_Init" 1 "VDC_NavChrgThermReq_1_ON" 2 "VDC_NavChrgThermReq_2_OFF" 3 "VDC_NavChrgThermReq_3_Invalid";
VAL_ 385 VDC_OBCACCurrtMaxPerm 127 "VDC_OBCACCurrtMaxPerm_127_Invalid";
VAL_ 385 VDC_PTCPwrReq 255 "VDC_PTCPwrReq_255_Invalid";
VAL_ 385 VDC_TDUHVPwrLimMax 255 "VDC_TDUHVPwrLimMax_255_Invalid";
VAL_ 385 VDC_TDUModReq 0 "VDC_TDUModReq_0_Initial" 1 "VDC_TDUModReq_1_Standby" 2 "VDC_TDUModReq_2_HV_On" 3 "VDC_TDUModReq_3_Power_Down" 4 "VDC_TDUModReq_4_Discharge" 5 "VDC_TDUModReq_5_Reserved";
VAL_ 385 VDC_VehDCChrgCurrtLimit 511 "VDC_VehDCChrgCurrtLimit_511_Invalid";
VAL_ 283 VDC_AccPedalAcPositionValid 0 "VDC_AccPedalAcPositionValid_0_Invalid" 1 "VDC_AccPedalAcPositionValid_1_Valid";
VAL_ 283 VDC_AccPedalActualPosition 1023 "VDC_AccPedalActualPosition_1023_Invalid";
VAL_ 283 VDC_AccPedalPosition 1023 "VDC_AccPedalPosition_1023_Invalid";
VAL_ 283 VDC_AccPedalPositionValid 0 "VDC_AccPedalPositionValid_0_Invalid" 1 "VDC_AccPedalPositionValid_1_Valid";
VAL_ 283 VDC_ActualGear 0 "VDC_ActualGear_0_P" 1 "VDC_ActualGear_1_R" 2 "VDC_ActualGear_2_N" 3 "VDC_ActualGear_3_D";
VAL_ 283 VDC_ActualGearValid 0 "VDC_ActualGearValid_0_Invalid" 1 "VDC_ActualGearValid_1_Valid";
VAL_ 283 VDC_AdsLowPowCmd 0 "VDC_AdsLowPowCmd_0_Initial" 1 "VDC_AdsLowPowCmd_1_开启ADS低功耗" 2 "VDC_AdsLowPowCmd_2_关闭ADS低功耗" 3 "VDC_AdsLowPowCmd_3_Reserve" 7 "VDC_AdsLowPowCmd_7_Invalid";
VAL_ 283 VDC_BMS_SOC 255 "VDC_BMS_SOC_255_Invalid";
VAL_ 283 VDC_BrakePedalFeelSet 0 "VDC_BrakePedalFeelSet_0_NO_Request" 1 "VDC_BrakePedalFeelSet_1_Strong" 2 "VDC_BrakePedalFeelSet_2_Week" 3 "VDC_BrakePedalFeelSet_3_Reserved";
VAL_ 283 VDC_brakePedalSts 0 "VDC_brakePedalSts_0_Not_pressed" 1 "VDC_brakePedalSts_1_Pressed";
VAL_ 283 VDC_brakePedalStsValid 0 "VDC_brakePedalStsValid_0_Invalid" 1 "VDC_brakePedalStsValid_1_Valid";
VAL_ 283 VDC_CDC_OnHighwaySt 0 "VDC_CDC_OnHighwaySt_0_Not_On_Highway" 1 "VDC_CDC_OnHighwaySt_1_On_Highway" 2 "VDC_CDC_OnHighwaySt_2_reserve" 3 "VDC_CDC_OnHighwaySt_3_Invalid";
VAL_ 283 VDC_CDCremindReq 0 "VDC_CDCremindReq_0_NO_Request" 1 "VDC_CDCremindReq_1_当前不具备模式切换条件,请稍后再试" 2 "VDC_CDCremindReq_2_请关闭车门和前舱盖再进行模式切换" 3 "VDC_CDCremindReq_3_车辆转向中，请稍后再进行切换" 4 "VDC_CDCremindReq_4_悬架系统热保护中，请稍后再进行高度设置" 5 "VDC_CDCremindReq_5_RESERVED" 6 "VDC_CDCremindReq_6_RESERVED" 7 "VDC_CDCremindReq_7_INVALID";
VAL_ 283 VDC_CompositeRang 2047 "VDC_CompositeRang_2047_Invalid";
VAL_ 283 VDC_driveReady 0 "VDC_driveReady_0_NOT_READY" 1 "VDC_driveReady_1_READY" 2 "VDC_driveReady_2_reserved" 3 "VDC_driveReady_3_reserved";
VAL_ 283 VDC_DrvMod 0 "VDC_DrvMod_0_Initial" 1 "VDC_DrvMod_1_ECO" 2 "VDC_DrvMod_2_Comfort" 3 "VDC_DrvMod_3_Sport" 4 "VDC_DrvMod_4_Individual" 5 "VDC_DrvMod_5_Wet" 6 "VDC_DrvMod_6_Snow" 7 "VDC_DrvMod_7_Escape" 8 "VDC_DrvMod_8_Race" 9 "VDC_DrvMod_9_Reserved" 10 "VDC_DrvMod_10_MtnSicknessMtgtn" 11 "VDC_DrvMod_11_Trailer" 12 "VDC_DrvMod_12_BOSS" 13 "VDC_DrvMod_13_Reserved" 14 "VDC_DrvMod_14_UltraPowerSaving" 15 "VDC_DrvMod_15_Reserved";
VAL_ 283 VDC_DrvrAccrPedlOvrd 0 "VDC_DrvrAccrPedlOvrd_0_Not_override" 1 "VDC_DrvrAccrPedlOvrd_1_Override";
VAL_ 283 VDC_DrvrGearOvrd 0 "VDC_DrvrGearOvrd_0_Not_override" 1 "VDC_DrvrGearOvrd_1_Override";
VAL_ 283 VDC_ECASFuncLimit 0 "VDC_ECASFuncLimit_0_Initial" 1 "VDC_ECASFuncLimit_1_Inhibit" 2 "VDC_ECASFuncLimit_2_Hold" 3 "VDC_ECASFuncLimit_3_Reserve";
VAL_ 283 VDC_ECASHeightAdjust 0 "VDC_ECASHeightAdjust_0_No_request" 1 "VDC_ECASHeightAdjust_1_Up" 2 "VDC_ECASHeightAdjust_2_Down" 3 "VDC_ECASHeightAdjust_3_High2" 4 "VDC_ECASHeightAdjust_4_High1" 5 "VDC_ECASHeightAdjust_5_Middle" 6 "VDC_ECASHeightAdjust_6_Low1" 7 "VDC_ECASHeightAdjust_7_Low2";
VAL_ 283 VDC_ECASMaintenanceMode 0 "VDC_ECASMaintenanceMode_0_No_request" 1 "VDC_ECASMaintenanceMode_1_Unenable" 2 "VDC_ECASMaintenanceMode_2_Enable" 3 "VDC_ECASMaintenanceMode_3_reserved";
VAL_ 283 VDC_EDCModeSet 0 "VDC_EDCModeSet_0_No_request" 1 "VDC_EDCModeSet_1_Soft" 2 "VDC_EDCModeSet_2_Middle" 3 "VDC_EDCModeSet_3_Hard" 4 "VDC_EDCModeSet_4_Reserved" 5 "VDC_EDCModeSet_5_Reserved" 6 "VDC_EDCModeSet_6_Reserved" 7 "VDC_EDCModeSet_7_Reserved";
VAL_ 283 VDC_epbRequest 0 "VDC_epbRequest_0_NO_COMMAND" 1 "VDC_epbRequest_1_APPLY" 2 "VDC_epbRequest_2_RELEASE" 3 "VDC_epbRequest_3_reserved";
VAL_ 283 VDC_epbRequestValid 0 "VDC_epbRequestValid_0_Invalid" 1 "VDC_epbRequestValid_1_Valid";
VAL_ 283 VDC_EPSModeRequest 0 "VDC_EPSModeRequest_0_NORequest" 1 "VDC_EPSModeRequest_1_Light" 2 "VDC_EPSModeRequest_2_Middle" 3 "VDC_EPSModeRequest_3_Heavy" 4 "VDC_EPSModeRequest_4_reserved" 5 "VDC_EPSModeRequest_5_reserved" 6 "VDC_EPSModeRequest_6_reserved" 7 "VDC_EPSModeRequest_7_Invalid";
VAL_ 283 VDC_ESCdriveReady 0 "VDC_ESCdriveReady_0_Not_Ready" 1 "VDC_ESCdriveReady_1_Failure" 2 "VDC_ESCdriveReady_2_Ready" 3 "VDC_ESCdriveReady_3_Reserve";
VAL_ 283 VDC_ESCModeSet 0 "VDC_ESCModeSet_0_NO_Request" 1 "VDC_ESCModeSet_1_Intervene+" 2 "VDC_ESCModeSet_2_Intervene_Middle" 3 "VDC_ESCModeSet_3_Intervene-" 4 "VDC_ESCModeSet_4_Wet/slip" 5 "VDC_ESCModeSet_5_Through_offroad" 6 "VDC_ESCModeSet_6_reserve";
VAL_ 283 VDC_GearShiftAvl 0 "VDC_GearShiftAvl_0_Not_Aavailable" 1 "VDC_GearShiftAvl_1_Available";
VAL_ 283 VDC_HV_State 0 "VDC_HV_State_0_HIGH_VOLT_DOWN" 1 "VDC_HV_State_1_HIGH_VOLT_UP" 2 "VDC_HV_State_2_RESERVED" 3 "VDC_HV_State_3_RESERVED" 4 "VDC_HV_State_4_RESERVED" 5 "VDC_HV_State_5_RESERVED" 6 "VDC_HV_State_6_RESERVED" 7 "VDC_HV_State_7_RESERVED";
VAL_ 283 VDC_LVEM_LoEgyCnsModReq 0 "VDC_LVEM_LoEgyCnsModReq_0_NO_Request" 1 "VDC_LVEM_LoEgyCnsModReq_1_Inactive" 2 "VDC_LVEM_LoEgyCnsModReq_2_Active" 3 "VDC_LVEM_LoEgyCnsModReq_3_Invalid";
VAL_ 283 VDC_OnePedalstatus 0 "VDC_OnePedalstatus_0_OFF" 1 "VDC_OnePedalstatus_1_ON";
VAL_ 283 VDC_PtTqAvl 0 "VDC_PtTqAvl_0_not_available" 1 "VDC_PtTqAvl_1_available" 2 "VDC_PtTqAvl_2_available_degraded" 3 "VDC_PtTqAvl_3_Reserved";
VAL_ 283 VDC_RegenModeStatus 0 "VDC_RegenModeStatus_0_OFF" 1 "VDC_RegenModeStatus_1_standard" 2 "VDC_RegenModeStatus_2_Strong" 3 "VDC_RegenModeStatus_3_one_padle" 4 "VDC_RegenModeStatus_4_reserve";
VAL_ 283 VDC_targetGear 0 "VDC_targetGear_0_P" 1 "VDC_targetGear_1_R" 2 "VDC_targetGear_2_N" 3 "VDC_targetGear_3_D";
VAL_ 283 VDC_targetGearValid 0 "VDC_targetGearValid_0_Invalid" 1 "VDC_targetGearValid_1_Valid";
VAL_ 283 VDC_TotalRang 1048575 "VDC_TotalRang_1048575_Invalid";
VAL_ 283 VDC_towMode_VV01 0 "VDC_towMode_0_Inactive" 1 "VDC_towMode_1_OFF" 2 "VDC_towMode_2_ON" 3 "VDC_towMode_3_Invalid";
VAL_ 283 VDC_TraveMode 0 "VDC_TraveMode_0_OFF" 1 "VDC_TraveMode_1_Wet_湿滑" 2 "VDC_TraveMode_2_Snow_雪地" 3 "VDC_TraveMode_3_Sand_沙地" 4 "VDC_TraveMode_4_Coming_Out_脱困" 5 "VDC_TraveMode_5_Reserved" 6 "VDC_TraveMode_6_Reserved" 7 "VDC_TraveMode_7_INVALID";
VAL_ 283 VDC_VehicleStopTimeValid 0 "VDC_VehicleStopTimeValid_0_Invalid" 1 "VDC_VehicleStopTimeValid_1_Valid";
VAL_ 283 VDC_VehSpd 8191 "VDC_VehSpd_8191_Invalid";
VAL_ 283 VDC_VehSpdDir 0 "VDC_VehSpdDir_0_invalid" 1 "VDC_VehSpdDir_1_forward" 2 "VDC_VehSpdDir_2_reverse" 3 "VDC_VehSpdDir_3_standstill";
VAL_ 283 VDC_VehSpdVld 0 "VDC_VehSpdVld_0_Invalid" 1 "VDC_VehSpdVld_1_Valid" 2 "VDC_VehSpdVld_2_Reserved";
VAL_ 258 VDC_RMcuWakUpReq 0 "VDC_RMcuWakUpReq_0_Sleep" 1 "VDC_RMcuWakUpReq_1_Wakeup";
VAL_ 258 VDC_RMotActiveDampReq 0 "VDC_RMotActiveDampReq_0_OFF" 1 "VDC_RMotActiveDampReq_1_ON";
VAL_ 258 VDC_RMotActiveDATSReq 0 "VDC_RMotActiveDATSReq_0_Initial" 1 "VDC_RMotActiveDATSReq_1_OFF" 2 "VDC_RMotActiveDATSReq_2_On" 3 "VDC_RMotActiveDATSReq_3_Invalid";
VAL_ 258 VDC_RMotActvDampLvlReq 0 "VDC_RMotActvDampLvlReq_0_Normal" 1 "VDC_RMotActvDampLvlReq_1_Soft" 2 "VDC_RMotActvDampLvlReq_2_Slip" 3 "VDC_RMotActvDampLvlReq_3_High";
VAL_ 258 VDC_RMotEnable 0 "VDC_RMotEnable_0_Disable" 1 "VDC_RMotEnable_1_Enable";
VAL_ 258 VDC_RMotMaxDrvTqLimt 4095 "VDC_RMotMaxDrvTqLimt_4095_Invalid";
VAL_ 258 VDC_RMotMaxRegenTqLimt 4095 "VDC_RMotMaxRegenTqLimt_4095_Invalid";
VAL_ 258 VDC_RMotModReq 0 "VDC_RMotModReq_0_Initial" 1 "VDC_RMotModReq_1_LV_Standby" 2 "VDC_RMotModReq_2_HV_Standby" 3 "VDC_RMotModReq_3_Torque_Mode" 4 "VDC_RMotModReq_4_Speed_Mode" 5 "VDC_RMotModReq_5_Reserved" 6 "VDC_RMotModReq_6_Reserved" 7 "VDC_RMotModReq_7_PowerDown" 8 "VDC_RMotModReq_8_DisCharge" 10 "VDC_RMotModReq_10_FastChargeMode" 11 "VDC_RMotModReq_11_Heat_up" 12 "VDC_RMotModReq_12_SV_Mode" 13 "VDC_RMotModReq_13_Reserved";
VAL_ 258 VDC_RMotSpdReq 65535 "VDC_RMotSpdReq_65535_Invalid";
VAL_ 258 VDC_RMotSVReplan 0 "VDC_RMotSVReplan_0_Not_replan" 1 "VDC_RMotSVReplan_1_Replan_Request" 2 "VDC_RMotSVReplan_2_Reserved";
VAL_ 258 VDC_RMotTqReq 65535 "VDC_RMotTqReq_65535_Invalid";
VAL_ 258 VDC_RMotTqUnloadEna 0 "VDC_RMotTqUnloadEna_0_Disable" 1 "VDC_RMotTqUnloadEna_1_Enable" 2 "VDC_RMotTqUnloadEna_2_Reserved";
VAL_ 258 VDC_RMotTrackingMod 0 "VDC_RMotTrackingMod_0_Normal_Tracking" 1 "VDC_RMotTrackingMod_1_Fast_Tracking" 2 "VDC_RMotTrackingMod_2_Reserved";
VAL_ 275 VDC_CoastRegenRequest_RA 65535 "VDC_CoastRegenRequest_RA_65535_Invalid";
VAL_ 275 VDC_CoastRegenRequest_RAValid 0 "VDC_CoastRegenRequest_RAValid_0_Invalid" 1 "VDC_CoastRegenRequest_RAValid_1_Valid";
VAL_ 275 VDC_DriverTorqueDesired 65535 "VDC_DriverTorqueDesired_65535_Invalid";
VAL_ 275 VDC_MotorRegenTorqueInD_VV01 0 "VDC_MotorRegenTorqueInD_0_Invalid";
VAL_ 275 VDC_MotorRegenTorqueInDValid 0 "VDC_MotorRegenTorqueInDValid_0_Invalid" 1 "VDC_MotorRegenTorqueInDValid_1_Valid";
VAL_ 275 VDC_MotorRegenTorqueLmtInD_VV01 0 "VDC_MotorRegenTorqueLmtInD_0_Invalid";
VAL_ 275 VDC_MotorRegenTrqLmtInDValid 0 "VDC_MotorRegenTrqLmtInDValid_0_Invalid" 1 "VDC_MotorRegenTrqLmtInDValid_1_Valid";
VAL_ 275 VDC_OPDHydBrkCompenRqSts 0 "VDC_OPDHydBrkCompenRqSts_0_no_request" 1 "VDC_OPDHydBrkCompenRqSts_1_request_hydraulic_compensation";
VAL_ 275 VDC_OPDHydBrkCompenRqTqValid 0 "VDC_OPDHydBrkCompenRqTqValid_0_Invalid" 1 "VDC_OPDHydBrkCompenRqTqValid_1_Valid";
VAL_ 275 VDC_PtTqActvSts 0 "VDC_PtTqActvSts_0_Not_response" 1 "VDC_PtTqActvSts_1_Responsed";
VAL_ 275 VDC_rearMotorRegenTorqueInD 4095 "VDC_rearMotorRegenTorqueInD_4095_Invalid";
VAL_ 275 VDC_rearMotorRegenTorqueInDValid 0 "VDC_rearMotorRegenTorqueInDValid_0_Invalid" 1 "VDC_rearMotorRegenTorqueInDValid_1_Valid";
VAL_ 275 VDC_rearMotorRegenTorqueLmtInD 4095 "VDC_rearMotorRegenTorqueLmtInD_4095_Invalid";
VAL_ 275 VDC_rearMotorRegenTrqLmtInDValid 0 "VDC_rearMotorRegenTrqLmtInDValid_0_Invalid" 1 "VDC_rearMotorRegenTrqLmtInDValid_1_Valid";
VAL_ 275 VDC_rearMotorRpm 65535 "VDC_rearMotorRpm_65535_Invalid";
VAL_ 275 VDC_rearMotorRpmValid 0 "VDC_rearMotorRpmValid_0_Invalid" 1 "VDC_rearMotorRpmValid_1_Valid";
VAL_ 275 VDC_rearMotorTorquePedValid 0 "VDC_rearMotorTorquePedValid_0_Invalid" 1 "VDC_rearMotorTorquePedValid_1_Valid";
VAL_ 275 VDC_rearMotorTqReqPedValid 0 "VDC_rearMotorTqReqPedValid_0_Invalid" 1 "VDC_rearMotorTqReqPedValid_1_Valid";
VAL_ 275 VDC_vehicleTorqueMax 16383 "VDC_vehicleTorqueMax_16383_Invalid";
VAL_ 275 VDC_vehicleTorqueMaxValid 0 "VDC_vehicleTorqueMaxValid_0_Invalid" 1 "VDC_vehicleTorqueMaxValid_1_Valid";
VAL_ 275 VDC_vehicleTorqueMin_VV01 16383 "VDC_vehicleTorqueMin_16383_Invalid";
VAL_ 275 VDC_vehicleTorqueMinValid 0 "VDC_vehicleTorqueMinValid_0_Invalid" 1 "VDC_vehicleTorqueMinValid_1_Valid";
VAL_ 275 VDC_VehWhlActTq 65535 "VDC_VehWhlActTq_65535_Invalid";
VAL_ 275 VDC_VehWhlActTqVld 0 "VDC_VehWhlActTqVld_0_Invalid" 1 "VDC_VehWhlActTqVld_1_Valid";
VAL_ 275 VDC_VehWhlReqTq 65535 "VDC_VehWhlReqTq_65535_Invalid";
VAL_ 275 VDC_VehWhlReqTqVld 0 "VDC_VehWhlReqTqVld_0_Invalid" 1 "VDC_VehWhlReqTqVld_1_Valid";
VAL_ 388 VDC_AccPedalPos 1023 "VDC_AccPedalPos_1023_Invalid";
VAL_ 388 VDC_AccrPedlUFirst 8191 "VDC_AccrPedlUFirst_8191_Invalid";
VAL_ 388 VDC_AccrPedlUFirst_Input 8190 "VDC_AccrPedlUFirst_Input_8190_Initial" 8191 "VDC_AccrPedlUFirst_Input_8191_Invalid";
VAL_ 388 VDC_AccrPedlUSecond 8191 "VDC_AccrPedlUSecond_8191_Invalid";
VAL_ 388 VDC_AccrPedlUSecond_Input 8190 "VDC_AccrPedlUSecond_Input_8190_Initial" 8191 "VDC_AccrPedlUSecond_Input_8191_Invalid";
VAL_ 388 VDC_ActGearSt 0 "VDC_ActGearSt_0_Undefined" 1 "VDC_ActGearSt_1_P" 2 "VDC_ActGearSt_2_R" 3 "VDC_ActGearSt_3_N" 4 "VDC_ActGearSt_4_D" 5 "VDC_ActGearSt_5_Reserved" 6 "VDC_ActGearSt_6_Reserved";
VAL_ 388 VDC_BrkPedalPressed 0 "VDC_BrkPedalPressed_0_Not_pressed" 1 "VDC_BrkPedalPressed_1_Pressed";
VAL_ 388 VDC_BrkPedalPressedValid 0 "VDC_BrkPedalPressedValid_0_Invalid" 1 "VDC_BrkPedalPressedValid_1_Valid";
VAL_ 388 VDC_KeyOnSt 0 "VDC_KeyOnSt_0_KeyOff" 1 "VDC_KeyOnSt_1_KeyON";
VAL_ 388 VDC_PowerMode 0 "VDC_PowerMode_0_OFF" 1 "VDC_PowerMode_1_ON" 2 "VDC_PowerMode_2_Reserved" 3 "VDC_PowerMode_3_Invalid";
VAL_ 388 VDC_PTReadySt 0 "VDC_PTReadySt_0_Not_Ready" 1 "VDC_PTReadySt_1_Ready";
VAL_ 388 VDC_RoadSlop 511 "VDC_RoadSlop_511_Invalid";
VAL_ 388 VDC_RoadSlopRate 511 "VDC_RoadSlopRate_511_Invalid";
VAL_ 388 VDC_SysFaultLevel_VV01 0 "VDC_SysFaultLevel_0_Normal" 1 "VDC_SysFaultLevel_1_L1" 2 "VDC_SysFaultLevel_2_L2" 3 "VDC_SysFaultLevel_3_L3" 4 "VDC_SysFaultLevel_4_L4" 5 "VDC_SysFaultLevel_5_L5" 6 "VDC_SysFaultLevel_6_L6" 7 "VDC_SysFaultLevel_7_L7" 8 "VDC_SysFaultLevel_8_L8" 9 "VDC_SysFaultLevel_9_L9" 10 "VDC_SysFaultLevel_10_L10" 11 "VDC_SysFaultLevel_11_L11" 12 "VDC_SysFaultLevel_12_L12" 13 "VDC_SysFaultLevel_13_Reserved" 14 "VDC_SysFaultLevel_14_Reserved" 15 "VDC_SysFaultLevel_15_L15";
VAL_ 388 VDC_TargetGearSt 1 "VDC_TargetGearSt_1_P" 2 "VDC_TargetGearSt_2_R" 3 "VDC_TargetGearSt_3_N" 4 "VDC_TargetGearSt_4_D" 5 "VDC_TargetGearSt_5_Reserved";
VAL_ 388 VDC_VehPowerSt 0 "VDC_VehPowerSt_0_OFF" 1 "VDC_VehPowerSt_1_ON";
VAL_ 785 VDC_AccMod 0 "VDC_AccMod_0_Initial" 1 "VDC_AccMod_1_ECO" 2 "VDC_AccMod_2_Comfort" 3 "VDC_AccMod_3_Sport" 4 "VDC_AccMod_4_Catapult" 5 "VDC_AccMod_5_Wet" 6 "VDC_AccMod_6_Snow" 7 "VDC_AccMod_7_Escape" 8 "VDC_AccMod_8_Race" 9 "VDC_AccMod_9_Reserved" 10 "VDC_AccMod_10_MtnSicknessMtgtn" 11 "VDC_AccMod_11_Reserved" 14 "VDC_AccMod_14_UltraPowerSaving" 15 "VDC_AccMod_15_Reserved";
VAL_ 785 VDC_CDC_ACChrgCurrtSet 0 "VDC_CDC_ACChrgCurrtSet_0_Initial" 127 "VDC_CDC_ACChrgCurrtSet_127_Invalid";
VAL_ 785 VDC_ChrgFaultSt 0 "VDC_ChrgFaultSt_0_No_Warning" 1 "VDC_ChrgFaultSt_1_Vehicle_Fault,_Please_Reboot_Vehicle" 2 "VDC_ChrgFaultSt_2_Replace_charging_pile(Reserved)" 3 "VDC_ChrgFaultSt_3_Pile_Fault" 4 "VDC_ChrgFaultSt_4_Pile_No_Power" 5 "VDC_ChrgFaultSt_5_Pile_Communication_Timeout" 6 "VDC_ChrgFaultSt_6_Abnormal_Connection,_Check_Connection" 7 "VDC_ChrgFaultSt_7_Pile_Voltage_Mismatching_Cannot_Charge" 8 "VDC_ChrgFaultSt_8_Pile_Voltage_Mismatching" 9 "VDC_ChrgFaultSt_9_Connection_exception_Current_limiting_(Reserved)" 10 "VDC_ChrgFaultSt_10_Connection_exception_ChrgEnd_(Reserved)" 11 "VDC_ChrgFaultSt_11_Start_charging_pile_(Reserved)" 12 "VDC_ChrgFaultSt_12_Restart_charging_pile(Reserved)" 13 "VDC_ChrgFaultSt_13_Waiting_for_charging_appointment(Reserved)" 14 "VDC_ChrgFaultSt_14_Current_limiting(Reserved)" 15 "VDC_ChrgFaultSt_15_Derated_Charging" 16 "VDC_ChrgFaultSt_16_(Reserved)" 17 "VDC_ChrgFaultSt_17_Charge_Lock_Abnormal" 18 "VDC_ChrgFaultSt_18_(Reserved)" 19 "VDC_ChrgFaultSt_19_Remaining_Time_Increasing" 20 "VDC_ChrgFaultSt_20_Appliance_Fault" 21 "VDC_ChrgFaultSt_21_Reserved";
VAL_ 785 VDC_ChrgLockSts 0 "VDC_ChrgLockSts_0_Init" 1 "VDC_ChrgLockSts_1_Lock" 2 "VDC_ChrgLockSts_2_Unlock" 3 "VDC_ChrgLockSts_3_Invalid";
VAL_ 785 VDC_CoastRegnSt 0 "VDC_CoastRegnSt_0_OFF" 1 "VDC_CoastRegnSt_1_Level1" 2 "VDC_CoastRegnSt_2_Level2" 3 "VDC_CoastRegnSt_3_Level3" 4 "VDC_CoastRegnSt_4_Reserved";
VAL_ 785 VDC_CoolSysOTSt 0 "VDC_CoolSysOTSt_0_Normal冷却系统正常" 1 "VDC_CoolSysOTSt_1_Fault冷却系统过温";
VAL_ 785 VDC_CooltLvlStatus 0 "VDC_CooltLvlStatus_0_initial" 1 "VDC_CooltLvlStatus_1_Normal" 2 "VDC_CooltLvlStatus_2_Low" 3 "VDC_CooltLvlStatus_3_invaild";
VAL_ 785 VDC_CreepModSt 0 "VDC_CreepModSt_0_OFF" 1 "VDC_CreepModSt_1_ON";
VAL_ 785 VDC_DCScheduleChrgAlld 0 "VDC_DCScheduleChrgAlld_0_Not_Allow" 1 "VDC_DCScheduleChrgAlld_1_Allow";
VAL_ 785 VDC_DrvMod_VV01 0 "VDC_DrvMod_0_Initial" 1 "VDC_DrvMod_1_ECO" 2 "VDC_DrvMod_2_Comfort" 3 "VDC_DrvMod_3_Sport" 4 "VDC_DrvMod_4_Individual" 5 "VDC_DrvMod_5_Wet" 6 "VDC_DrvMod_6_Snow" 7 "VDC_DrvMod_7_Escape" 8 "VDC_DrvMod_8_Race" 9 "VDC_DrvMod_9_Reserved" 10 "VDC_DrvMod_10_MtnSicknessMtgtn" 11 "VDC_DrvMod_11_Trailer" 12 "VDC_DrvMod_12_BOSS" 13 "VDC_DrvMod_13_Reserved" 14 "VDC_DrvMod_14_UltraPowerSaving" 15 "VDC_DrvMod_15_Reserved";
VAL_ 785 VDC_EstimdSlop 254 "VDC_EstimdSlop_254_Init" 255 "VDC_EstimdSlop_255_Invalid";
VAL_ 785 VDC_EstimdSlopVld 0 "VDC_EstimdSlopVld_0_Invalid" 1 "VDC_EstimdSlopVld_1_Valid";
VAL_ 785 VDC_FactoryReset 0 "VDC_FactoryReset_0_No_Request" 1 "VDC_FactoryReset_1_Request";
VAL_ 785 VDC_GearFailedWarnInfo 0 "VDC_GearFailedWarnInfo_0_No_Warning" 1 "VDC_GearFailedWarnInfo_1_GearP_EnterWarning" 2 "VDC_GearFailedWarnInfo_2_WarningGearShiftNotBrake" 3 "VDC_GearFailedWarnInfo_3_WarningGearShiftHighSpeed" 4 "VDC_GearFailedWarnInfo_4_GearAntiTheftWarning" 5 "VDC_GearFailedWarnInfo_5_WarningChargerNotShift" 6 "VDC_GearFailedWarnInfo_6_NotReadyFailedGearshift" 7 "VDC_GearFailedWarnInfo_7_ErrorFailedGearShift";
VAL_ 785 VDC_HVAllowSts 0 "VDC_HVAllowSts_0_Allowed" 1 "VDC_HVAllowSts_1_Not_allowed" 2 "VDC_HVAllowSts_2_Reserved" 7 "VDC_HVAllowSts_7_Invalid";
VAL_ 785 VDC_HVBattFaultSt 0 "VDC_HVBattFaultSt_0_Normal正常" 1 "VDC_HVBattFaultSt_1_Fault故障";
VAL_ 785 VDC_LowSOCSt 0 "VDC_LowSOCSt_0_Off" 1 "VDC_LowSOCSt_1_ON";
VAL_ 785 VDC_LowSocWarn 0 "VDC_LowSocWarn_0_normal" 1 "VDC_LowSocWarn_1_level1" 2 "VDC_LowSocWarn_2_level2" 3 "VDC_LowSocWarn_3_level3" 4 "VDC_LowSocWarn_4_level4" 5 "VDC_LowSocWarn_5_level5" 6 "VDC_LowSocWarn_6_reserved";
VAL_ 785 VDC_LVBattChrgFault 0 "VDC_LVBattChrgFault_0_Normal" 1 "VDC_LVBattChrgFault_1_Failed_to_start_charging" 2 "VDC_LVBattChrgFault_2_System_Fault,_Cannot_be_recharged" 3 "VDC_LVBattChrgFault_3_LV_Battery_Fault";
VAL_ 785 VDC_LVBattChrgReqSt 0 "VDC_LVBattChrgReqSt_0_No_Request" 1 "VDC_LVBattChrgReqSt_1_Normal" 2 "VDC_LVBattChrgReqSt_2_Mode1" 3 "VDC_LVBattChrgReqSt_3_Mode2" 4 "VDC_LVBattChrgReqSt_4_Reserved";
VAL_ 785 VDC_LVBattChrgSt 0 "VDC_LVBattChrgSt_0_initial" 1 "VDC_LVBattChrgSt_1_Charging" 2 "VDC_LVBattChrgSt_2_Charging_Fault" 3 "VDC_LVBattChrgSt_3_Charging_Completed";
VAL_ 785 VDC_LVBattFaultSt 0 "VDC_LVBattFaultSt_0_Normal正常" 1 "VDC_LVBattFaultSt_1_Fault故障";
VAL_ 785 VDC_MCUPwrAct 255 "VDC_MCUPwrAct_255_Invalid";
VAL_ 785 VDC_MCUPwrReq 255 "VDC_MCUPwrReq_255_Invalid";
VAL_ 785 VDC_MotFaultSt 0 "VDC_MotFaultSt_0_Normal正常" 1 "VDC_MotFaultSt_1_Fault故障";
VAL_ 785 VDC_NavTunnelSt 0 "VDC_NavTunnelSt_0_OUT" 1 "VDC_NavTunnelSt_1_Enter";
VAL_ 785 VDC_OnePedlModSt 0 "VDC_OnePedlModSt_0_OFF" 1 "VDC_OnePedlModSt_1_Hold" 2 "VDC_OnePedlModSt_2_Creep" 3 "VDC_OnePedlModSt_3_Reserved";
VAL_ 785 VDC_PwrLimitSt 0 "VDC_PwrLimitSt_0_Not_limited" 1 "VDC_PwrLimitSt_1_Limited";
VAL_ 785 VDC_RemThermReq 0 "VDC_RemThermReq_0_OFF" 1 "VDC_RemThermReq_1_ON" 2 "VDC_RemThermReq_2_Reserved" 3 "VDC_RemThermReq_3_Invalid";
VAL_ 785 VDC_RemThermTiCalcdReq 0 "VDC_RemThermTiCalcdReq_0_No_Request" 1 "VDC_RemThermTiCalcdReq_1_Calculating" 2 "VDC_RemThermTiCalcdReq_2_Reserved" 3 "VDC_RemThermTiCalcdReq_3_Invalid";
VAL_ 785 VDC_RepairModeSts 0 "VDC_RepairModeSts_0_Initia" 1 "VDC_RepairModeSts_1_OFF" 2 "VDC_RepairModeSts_2_ON" 3 "VDC_RepairModeSts_3_Invalid";
VAL_ 785 VDC_ScheduleChrgCtrlSts 0 "VDC_ScheduleChrgCtrlSts_0_NO_Request" 1 "VDC_ScheduleChrgCtrlSts_1_Charg_Allow" 2 "VDC_ScheduleChrgCtrlSts_2_Charg_NotAllow" 3 "VDC_ScheduleChrgCtrlSts_3_Reserved" 15 "VDC_ScheduleChrgCtrlSts_15_Invalid";
VAL_ 785 VDC_ScheduleChrgStartStopCmd 0 "VDC_ScheduleChrgStartStopCmd_0_No_Request" 1 "VDC_ScheduleChrgStartStopCmd_1_Manual_Start_Charge" 2 "VDC_ScheduleChrgStartStopCmd_2_Schedule_Start_Charge" 3 "VDC_ScheduleChrgStartStopCmd_3_Manual_Stop_Charge" 4 "VDC_ScheduleChrgStartStopCmd_4_Schedule_Stop_Charge" 5 "VDC_ScheduleChrgStartStopCmd_5_Reserved" 15 "VDC_ScheduleChrgStartStopCmd_15_无效值";
VAL_ 785 VDC_ShiftGearWarnSt 0 "VDC_ShiftGearWarnSt_0_No_Warning" 1 "VDC_ShiftGearWarnSt_1_GearP_EnterWarning" 2 "VDC_ShiftGearWarnSt_2_WarningGearShiftNotBrake" 3 "VDC_ShiftGearWarnSt_3_WarningGearShiftHighSpeed" 4 "VDC_ShiftGearWarnSt_4_GearAntiTheftWarning" 5 "VDC_ShiftGearWarnSt_5_ChargeNotallowedGear" 6 "VDC_ShiftGearWarnSt_6_NotReadyFailedGearshift" 7 "VDC_ShiftGearWarnSt_7_EPBParkFailedGearShift" 8 "VDC_ShiftGearWarnSt_8_EPBReleaseFailedGearShift" 9 "VDC_ShiftGearWarnSt_9_GSMErrorFailedGearShift" 10 "VDC_ShiftGearWarnSt_10_VehSpdErrorFailedGearShift" 11 "VDC_ShiftGearWarnSt_11_TowModeFailedGearShift" 12 "VDC_ShiftGearWarnSt_12_ShowModeFailedGearShift" 13 "VDC_ShiftGearWarnSt_13_WashModeFailedGearShift" 14 "VDC_ShiftGearWarnSt_14_ADSNotExitFailedGearShift" 15 "VDC_ShiftGearWarnSt_15_NShortTimeFailedGearShift";
VAL_ 785 VDC_SpdLimWarn 0 "VDC_SpdLimWarn_0_No_Warning" 1 "VDC_SpdLimWarn_1_Warning";
VAL_ 785 VDC_SysFaultText 0 "VDC_SysFaultText_0_Normal无故障无提示" 1 "VDC_SysFaultText_1_Acceleration_Limited加速性能受限！请尽快联系服务中心检修" 2 "VDC_SysFaultText_2_Speed_Limited最高车速受限！请尽快联系服务中心检修" 3 "VDC_SysFaultText_3_Power_Limited_Static动力系统受限！请尽快联系服务中心检修" 4 "VDC_SysFaultText_4_Power_Limited_Dynamic动力系统受限！请尽快靠边停车" 5 "VDC_SysFaultText_5_Power_Limited_PGear动力系统受限！切至P档后无法继续行车！" 6 "VDC_SysFaultText_6_Power_On_Limited无法上电！请尽快联系服务中心检修" 7 "VDC_SysFaultText_7_Stay_Away请靠边停车，远离车辆！（文字+语音）" 8 "VDC_SysFaultText_8_reserved预留";
VAL_ 785 VDC_TempExclusivePassFlg 0 "VDC_TempExclusivePassFlg_0_Initial" 1 "VDC_TempExclusivePassFlg_1_OFF" 2 "VDC_TempExclusivePassFlg_2_ON" 3 "VDC_TempExclusivePassFlg_3_Invalid";
VAL_ 785 VDC_TempExclusiveRearFlg 0 "VDC_TempExclusiveRearFlg_0_Initial" 1 "VDC_TempExclusiveRearFlg_1_OFF" 2 "VDC_TempExclusiveRearFlg_2_ON" 3 "VDC_TempExclusiveRearFlg_3_Invalid";
VAL_ 785 VDC_TempExclusiveRearRiFlg 0 "VDC_TempExclusiveRearRiFlg_0_Initial" 1 "VDC_TempExclusiveRearRiFlg_1_OFF" 2 "VDC_TempExclusiveRearRiFlg_2_ON" 3 "VDC_TempExclusiveRearRiFlg_3_Invalid";
VAL_ 785 VDC_TimeChargeSwtichSts 0 "VDC_TimeChargeSwtichSts_0_OFF" 1 "VDC_TimeChargeSwtichSts_1_ON";
VAL_ 785 VDC_TVModSt 0 "VDC_TVModSt_0_OFF" 1 "VDC_TVModSt_1_ON";
VAL_ 785 VDC_Usagemode 0 "VDC_Usagemode_0_Abandoned" 1 "VDC_Usagemode_1_Inactive" 2 "VDC_Usagemode_2_Convenience" 3 "VDC_Usagemode_3_Remote" 4 "VDC_Usagemode_4_RemoteDriving" 5 "VDC_Usagemode_5_Driving" 6 "VDC_Usagemode_6_OTA" 7 "VDC_Usagemode_7_Reserved";
VAL_ 785 VDC_VehFaultLevel 0 "VDC_VehFaultLevel_0_Normal" 1 "VDC_VehFaultLevel_1_L1" 2 "VDC_VehFaultLevel_2_L2" 3 "VDC_VehFaultLevel_3_L3" 4 "VDC_VehFaultLevel_4_L4" 5 "VDC_VehFaultLevel_5_L5" 6 "VDC_VehFaultLevel_6_L6" 7 "VDC_VehFaultLevel_7_L7" 8 "VDC_VehFaultLevel_8_L8" 9 "VDC_VehFaultLevel_9_L9" 10 "VDC_VehFaultLevel_10_L10" 11 "VDC_VehFaultLevel_11_L11" 12 "VDC_VehFaultLevel_12_L12" 13 "VDC_VehFaultLevel_13_Reserved" 14 "VDC_VehFaultLevel_14_Reserved" 15 "VDC_VehFaultLevel_15_L15";
VAL_ 785 VDC_VehModSt 0 "VDC_VehModSt_0_Initial" 1 "VDC_VehModSt_1_Idle_Mode" 2 "VDC_VehModSt_2_Charge_Mode" 3 "VDC_VehModSt_3_Drive_Mode" 4 "VDC_VehModSt_4_PostRun_Mode" 5 "VDC_VehModSt_5_UDS_Mode";
VAL_ 785 VDC_VehSysWarnSt 0 "VDC_VehSysWarnSt_0_Normal系统正常" 1 "VDC_VehSysWarnSt_1_Fault系统故障";
VAL_ 785 VDC_WeakRegnRemind 0 "VDC_WeakRegnRemind_0_OFF" 1 "VDC_WeakRegnRemind_1_ON";
VAL_ 788 VDC_EnaCmd_EAS 0 "VDC_EnaCmd_EAS_0_Disable" 1 "VDC_EnaCmd_EAS_1_Enable";
VAL_ 788 VDC_EngNotReadyReason 0 "VDC_EngNotReadyReason_0_Initial" 1 "VDC_EngNotReadyReason_1_EngReady" 2 "VDC_EngNotReadyReason_2_ExhibitionMod" 3 "VDC_EngNotReadyReason_3_OTA_Updating" 4 "VDC_EngNotReadyReason_4_FaultForbid" 5 "VDC_EngNotReadyReason_5_EngForbidScene" 6 "VDC_EngNotReadyReason_6_ChargeMode" 7 "VDC_EngNotReadyReason_7_FuelAddingMode" 8 "VDC_EngNotReadyReason_8_HVOFF" 9 "VDC_EngNotReadyReason_9_KL15OFF" 10 "VDC_EngNotReadyReason_10_BrakePedalNotPress" 11 "VDC_EngNotReadyReason_11_Not_Reev_Configuration";
VAL_ 788 VDC_EngStartForbidReason 0 "VDC_EngStartForbidReason_0_Initial" 1 "VDC_EngStartForbidReason_1_Start_Allow" 2 "VDC_EngStartForbidReason_2_Eng_Not_Ready" 3 "VDC_EngStartForbidReason_3_Empty_Gasoline" 4 "VDC_EngStartForbidReason_4_Protection_Stop_Over_Times" 5 "VDC_EngStartForbidReason_5_Start_Failure_Over_Times" 6 "VDC_EngStartForbidReason_6_StopTime_Too_Short";
VAL_ 788 VDC_FuelAddingAlldSt 0 "VDC_FuelAddingAlldSt_0_NOT_ALLOW_INC" 1 "VDC_FuelAddingAlldSt_1_ALLOW_INC_允许加油";
VAL_ 788 VDC_TotalRang_1 16777215 "VDC_TotalRang_1_16777215_Invalid";
VAL_ 857 VIU_AmbT 4095 "VIU_AmbT_4095_Invalid";
VAL_ 857 VIU_AmbTVld 0 "VIU_AmbTVld_0_Invalid" 1 "VIU_AmbTVld_1_Valid";
VAL_ 857 VIU_FuelSigFlt 0 "VIU_FuelSigFlt_0_Normal" 1 "VIU_FuelSigFlt_1_油位信号输入电路对电源短路（主副箱任何一路发生对电源短路）；" 2 "VIU_FuelSigFlt_2_油位信号输入电路对地短路（主副箱任何一路发生对地短路）；" 3 "VIU_FuelSigFlt_3_油位信号输入电路开路（主副箱任何一路发生开路）；" 4 "VIU_FuelSigFlt_4_Reserved；" 7 "VIU_FuelSigFlt_7_Invalid";
VAL_ 857 VIU_HVFuelRleaseRequest 0 "VIU_HVFuelRleaseRequest_0_No_Request" 1 "VIU_HVFuelRleaseRequest_1_Request" 2 "VIU_HVFuelRleaseRequest_2_Reserved" 3 "VIU_HVFuelRleaseRequest_3_Invalid";
VAL_ 857 VIU_OilSnsrResistorVal 510 "VIU_OilSnsrResistorVal_510_Initial" 511 "VIU_OilSnsrResistorVal_511_Invalid";
VAL_ 688 VIU_FuCapSt 0 "VIU_FuCapSt_0_Initial" 1 "VIU_FuCapSt_1_Closed" 2 "VIU_FuCapSt_2_Opened" 3 "VIU_FuCapSt_3_Invalid";
VAL_ 467 VIU_CarMode 0 "VIU_CarMode_0_Factory" 1 "VIU_CarMode_1_Transport" 2 "VIU_CarMode_2_Dynotest" 3 "VIU_CarMode_3_Normal" 4 "VIU_CarMode_4_ExhibitionInDoor" 5 "VIU_CarMode_5_ExhibitionOutDoor" 6 "VIU_CarMode_6_reserved" 14 "VIU_CarMode_14_Initial" 15 "VIU_CarMode_15_Invalid";
VAL_ 467 VIU_PowerMode 0 "VIU_PowerMode_0_OFF" 1 "VIU_PowerMode_1_ON" 2 "VIU_PowerMode_2_Reserved" 3 "VIU_PowerMode_3_Invalid";
VAL_ 467 VIU_PowerModeFltFlag 0 "VIU_PowerModeFltFlag_0_False" 1 "VIU_PowerModeFltFlag_1_True" 2 "VIU_PowerModeFltFlag_2_Reserved" 3 "VIU_PowerModeFltFlag_3_Invalid";
VAL_ 467 VIU_UsageMode 0 "VIU_UsageMode_0_Abandoned" 1 "VIU_UsageMode_1_Inactive" 2 "VIU_UsageMode_2_Convenience" 3 "VIU_UsageMode_3_Driving" 4 "VIU_UsageMode_4_OTA_Updating" 5 "VIU_UsageMode_5_Remote" 6 "VIU_UsageMode_6_RemoteDriving" 7 "VIU_UsageMode_7_reserved" 15 "VIU_UsageMode_15_Invalid";
VAL_ 467 VIU_VehAntithftSt 0 "VIU_VehAntithftSt_0_unset" 1 "VIU_VehAntithftSt_1_set" 2 "VIU_VehAntithftSt_2_part_set" 3 "VIU_VehAntithftSt_3_alarm" 4 "VIU_VehAntithftSt_4_pre_set" 5 "VIU_VehAntithftSt_5_reserved" 7 "VIU_VehAntithftSt_7_invalid";
VAL_ 856 RSM_AirT 2047 "RSM_AirT_2047_Invalid";
VAL_ 856 RSM_DewPointT 2047 "RSM_DewPointT_2047_Invalid";
VAL_ 856 RSM_HumTFlt 0 "RSM_HumTFlt_0_Normal" 1 "RSM_HumTFlt_1_Failure";
VAL_ 856 RSM_LeSolarInten 254 "RSM_LeSolarInten_254_Initial_Value" 255 "RSM_LeSolarInten_255_Invalid";
VAL_ 856 RSM_LiSnsrErr 0 "RSM_LiSnsrErr_0_Normal" 1 "RSM_LiSnsrErr_1_Failure";
VAL_ 856 RSM_Rainfall 0 "RSM_Rainfall_0_No_Rain" 1 "RSM_Rainfall_1_Light_Rain" 2 "RSM_Rainfall_2_Moderate_Rain" 3 "RSM_Rainfall_3_Heavy_Rain";
VAL_ 856 RSM_RainSnsrErr 0 "RSM_RainSnsrErr_0_Normal" 1 "RSM_RainSnsrErr_1_Failure";
VAL_ 856 RSM_RelHum 255 "RSM_RelHum_255_Invalid";
VAL_ 856 RSM_RiSolarInten 254 "RSM_RiSolarInten_254_Initial_Value" 255 "RSM_RiSolarInten_255_Invalid";
VAL_ 856 RSM_WinT 2047 "RSM_WinT_2047_Invalid";
VAL_ 463 ADS_MotSpdCtrlEna 0 "ADS_MotSpdCtrlEna_0_Disable" 1 "ADS_MotSpdCtrlEna_1_Enable";
VAL_ 463 CS_FWiperMistReq 0 "CS_FWiperMistReq_0_Initial" 1 "CS_FWiperMistReq_1_NO_Request" 2 "CS_FWiperMistReq_2_Request" 3 "CS_FWiperMistReq_3_Invalid";
VAL_ 463 CS_FWiperSwtReq 0 "CS_FWiperSwtReq_0_Initial" 1 "CS_FWiperSwtReq_1_OFF" 2 "CS_FWiperSwtReq_2_Auto" 3 "CS_FWiperSwtReq_3_Low_Speed" 4 "CS_FWiperSwtReq_4_High_Speed" 5 "CS_FWiperSwtReq_5_Reserved" 7 "CS_FWiperSwtReq_7_Invalid";
VAL_ 463 CS_FWiperWashReq 0 "CS_FWiperWashReq_0_Initial" 1 "CS_FWiperWashReq_1_NO_Request" 2 "CS_FWiperWashReq_2_Request" 3 "CS_FWiperWashReq_3_Invalid";
VAL_ 463 EPS_SteerWheelAngle 16383 "EPS_SteerWheelAngle_16383_Invalid";
VAL_ 463 EPS_SteerWheelAngleValid 0 "EPS_SteerWheelAngleValid_0_Invalid";
VAL_ 463 IBS_AVHAvailable 0 "IBS_AVHAvailable_0_Not_Available" 1 "IBS_AVHAvailable_1_Available";
VAL_ 463 IBS_AVHStatus 0 "IBS_AVHStatus_0_OFF" 1 "IBS_AVHStatus_1_Standby" 2 "IBS_AVHStatus_2_Actvie" 3 "IBS_AVHStatus_3_Reserved";
VAL_ 463 IBS_ESCOFF_Status 0 "IBS_ESCOFF_Status_0_OFF" 1 "IBS_ESCOFF_Status_1_ON";
VAL_ 796 IBS_OBDFaultExistSts 0 "IBS_OBDFaultExistSts_0_No_OBD_Fault" 1 "IBS_OBDFaultExistSts_1_OBD_Fault";
VAL_ 796 IPB_OBD_MILOnReq 0 "IPB_OBD_MILOnReq_0_NO_Request" 1 "IPB_OBD_MILOnReq_1_Request_On";
